VERSION ""

NS_ :

BS_:

BU_: AMP BCM DCSD DIAG_TEST DTV ECC EMCM ETM HCPM IPC LSMD LSMP LTM RRM TBM
BO_ 1283 RADIO_B3: 8 ETM
 SG_ ManDispCtrl : 56|1@0+ (1,0) [0|1] "" DCSD
 SG_ RQ_DISP_INTS : 55|8@0+ (0.5,0) [0|100] "%" DCSD

BO_ 1284 RADIO_B4: 8 ETM
 SG_ Radio_Theme : 7|8@0+ (1,0) [0|254] "-" Vector__XXX

BO_ 1289 RADIO_B9: 8 ETM
 SG_ ChargeNow : 39|1@0+ (1,0) [0|1] "" BCM

BO_ 1452 SAT_POS: 8 TBM
 SG_ Lat_Pos : 7|32@0+ (0.3017485143,-324000000) [-324000000|972000000.23334] "Milliarcseconds" ETM,LTM
 SG_ Long_Pos : 39|32@0+ (0.3017485143,-324000000) [-324000000|972000000.23334] "Milliarcseconds" ETM,LTM

BO_ 948 SDW_INFO: 6 BCM
 SG_ SDW_ChimeActivation_LHF : 36|1@0+ (1,0) [0|1] "-" AMP,ETM,IPC,LTM,TBM
 SG_ SDW_ChimeActivation_LHR : 38|1@0+ (1,0) [0|1] "-" AMP,ETM,IPC,LTM,TBM
 SG_ SDW_ChimeActivation_RHF : 37|1@0+ (1,0) [0|1] "-" AMP,ETM,IPC,LTM,TBM
 SG_ SDW_ChimeActivation_RHR : 39|1@0+ (1,0) [0|1] "-" AMP,ETM,IPC,LTM,TBM
 SG_ SDW_ChimeRepetitionRate_Left : 47|4@0+ (1,0) [0|15] "Hz" AMP,ETM,IPC,LTM,TBM
 SG_ SDW_ChimeRepetitionRate_Right : 43|4@0+ (1,0) [0|15] "Hz" AMP,ETM,IPC,LTM,TBM
 SG_ SDW_ChimeType_Left : 33|2@0+ (1,0) [0|3] "-" AMP,ETM,LTM,TBM
 SG_ SDW_ChimeType_Right : 35|2@0+ (1,0) [0|3] "-" AMP,ETM,LTM,TBM
 SG_ SDW_DisplayActivation : 6|1@0+ (1,0) [0|1] "-" IPC
 SG_ SDW_ObstacleInTrajectory_LLF : 5|1@0+ (1,0) [0|1] "-" IPC
 SG_ SDW_ObstacleInTrajectory_LLR : 4|1@0+ (1,0) [0|1] "-" IPC
 SG_ SDW_ObstacleInTrajectory_LRF : 3|1@0+ (1,0) [0|1] "-" IPC
 SG_ SDW_ObstacleInTrajectory_LRR : 2|1@0+ (1,0) [0|1] "-" IPC
 SG_ SDW_Warning_Left_1 : 27|2@0+ (1,0) [0|2] "-" IPC
 SG_ SDW_Warning_Left_2 : 25|2@0+ (1,0) [0|2] "-" IPC
 SG_ SDW_Warning_Right_1 : 31|2@0+ (1,0) [0|2] "-" IPC
 SG_ SDW_Warning_Right_2 : 29|2@0+ (1,0) [0|2] "-" IPC

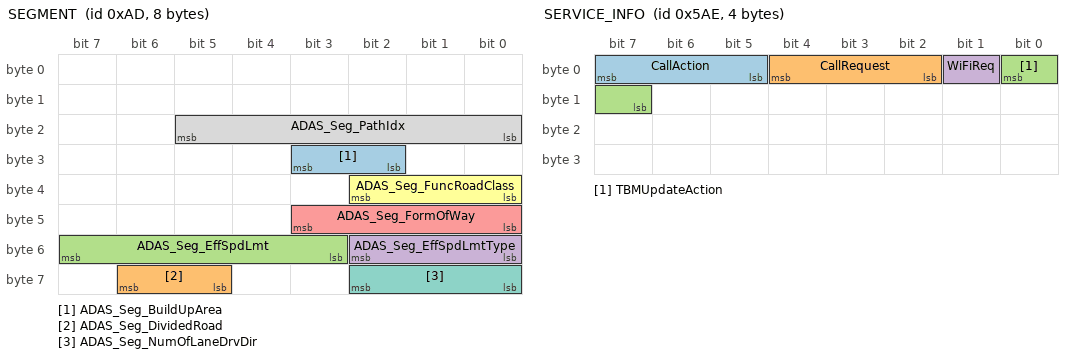
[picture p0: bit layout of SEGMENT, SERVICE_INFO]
BO_ 173 SEGMENT: 8 ETM
 SG_ ADAS_Seg_BuildUpArea : 27|2@0+ (1,0) [0|3] "-" BCM,IPC
 SG_ ADAS_Seg_DividedRoad : 62|2@0+ (1,0) [0|3] "-" BCM,IPC
 SG_ ADAS_Seg_EffSpdLmt : 55|5@0+ (1,0) [0|31] "-" BCM,IPC
 SG_ ADAS_Seg_EffSpdLmtType : 50|3@0+ (1,0) [0|7] "-" BCM,IPC
 SG_ ADAS_Seg_FormOfWay : 43|4@0+ (1,0) [0|15] "-" BCM,IPC
 SG_ ADAS_Seg_FuncRoadClass : 34|3@0+ (1,0) [0|7] "-" BCM,IPC
 SG_ ADAS_Seg_NumOfLaneDrvDir : 58|3@0+ (1,0) [0|7] "" BCM,IPC
 SG_ ADAS_Seg_PathIdx : 21|6@0+ (1,0) [0|63] "-" BCM,IPC

BO_ 1454 SERVICE_INFO: 4 ETM
 SG_ CallAction : 7|3@0+ (1,0) [0|7] "" TBM
 SG_ CallRequest : 4|3@0+ (1,0) [0|7] "" TBM
 SG_ TBMUpdateAction : 0|2@0+ (1,0) [0|3] "" TBM
 SG_ WiFiReq : 1|1@0+ (1,0) [0|1] "" TBM

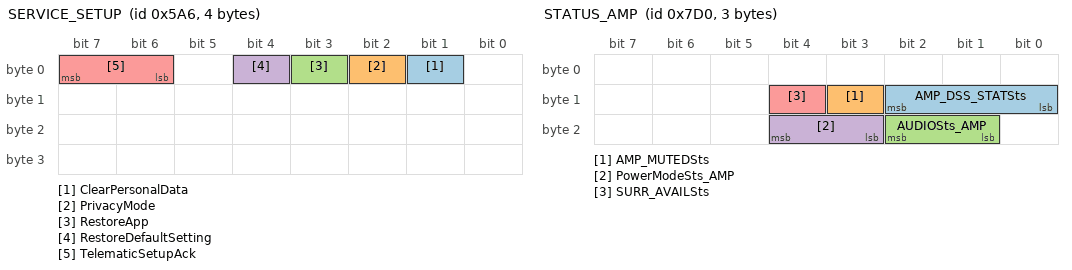
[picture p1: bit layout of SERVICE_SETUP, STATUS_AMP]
BO_ 1446 SERVICE_SETUP: 4 TBM
 SG_ ClearPersonalData : 1|1@0+ (1,0) [0|1] "-" ETM,LTM
 SG_ PrivacyMode : 2|1@0+ (1,0) [0|1] "-" ETM,LTM
 SG_ RestoreApp : 3|1@0+ (1,0) [0|1] "-" ETM,LTM
 SG_ RestoreDefaultSetting : 4|1@0+ (1,0) [0|1] "-" ETM,LTM
 SG_ TelematicSetupAck : 7|2@0+ (1,0) [0|3] "-" ETM

BO_ 1890 SERVICEINFO2: 6 IPC
 SG_ DaysToService : 22|9@0+ (1,0) [0|366] "day" LTM,TBM
 SG_ DistanceToService : 7|17@0+ (1,0) [0|131071] "km_or_mi" ETM,LTM,TBM

BO_ 2000 STATUS_AMP: 3 AMP
 SG_ AMP_DSS_STATSts : 10|3@0+ (1,0) [0|7] "" ETM,LTM
 SG_ AMP_MUTEDSts : 11|1@0+ (1,0) [0|1] "" ETM,LTM
 SG_ AUDIOSts_AMP : 18|2@0+ (1,0) [0|3] "" ETM,LTM
 SG_ PowerModeSts_AMP : 20|2@0+ (1,0) [0|3] "" BCM
 SG_ SURR_AVAILSts : 12|1@0+ (1,0) [0|1] "" ETM,LTM

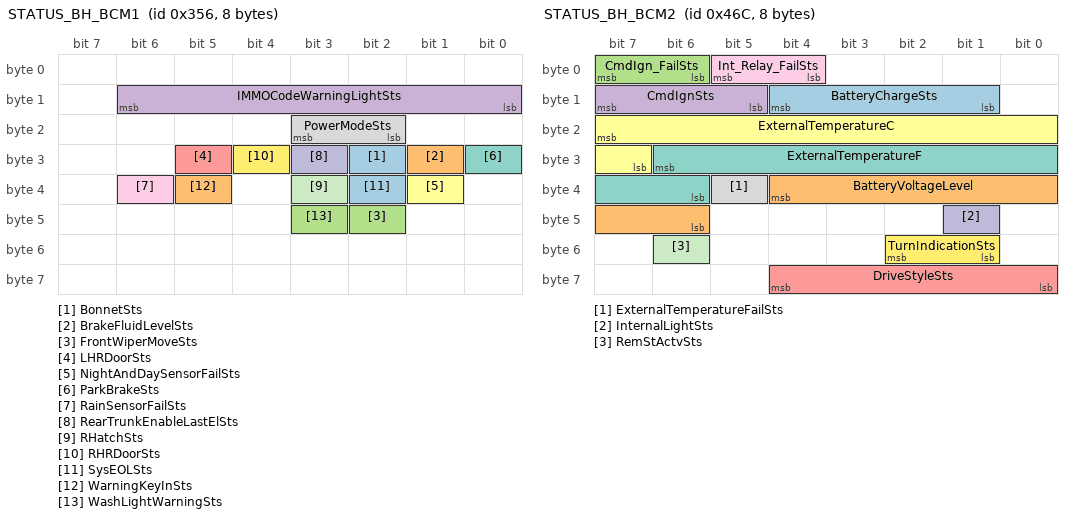
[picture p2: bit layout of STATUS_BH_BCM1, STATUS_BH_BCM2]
BO_ 854 STATUS_BH_BCM1: 8 BCM
 SG_ BonnetSts : 26|1@0+ (1,0) [0|1] "-" ETM,IPC,LTM,TBM
 SG_ BrakeFluidLevelSts : 25|1@0+ (1,0) [0|1] "-" ETM,LTM,RRM,TBM
 SG_ FrontWiperMoveSts : 42|1@0+ (1,0) [0|1] "" ECC,TBM
 SG_ IMMOCodeWarningLightSts : 14|7@0+ (1,0) [0|18] "-" IPC
 SG_ LHRDoorSts : 29|1@0+ (1,0) [0|1] "-" ECC,ETM,IPC,LTM,TBM
 SG_ NightAndDaySensorFailSts : 33|1@0+ (1,0) [0|1] "" IPC
 SG_ ParkBrakeSts : 24|1@0+ (1,0) [0|1] "-" ETM,LTM
 SG_ PowerModeSts : 19|2@0+ (1,0) [0|3] "" AMP,ECC,ETM,HCPM,LSMD,LSMP,LTM,RRM,TBM
 SG_ RainSensorFailSts : 38|1@0+ (1,0) [0|1] "-" IPC
 SG_ RearTrunkEnableLastElSts : 27|1@0+ (1,0) [0|1] "-" TBM
 SG_ RHatchSts : 35|1@0+ (1,0) [0|1] "-" ECC,ETM,IPC,LTM,TBM
 SG_ RHRDoorSts : 28|1@0+ (1,0) [0|1] "-" ECC,ETM,IPC,LTM,TBM
 SG_ SysEOLSts : 34|1@0+ (1,0) [0|1] "-" IPC
 SG_ WarningKeyInSts : 37|1@0+ (1,0) [0|1] "" IPC
 SG_ WashLightWarningSts : 43|1@0+ (1,0) [0|1] "" IPC,TBM

BO_ 1132 STATUS_BH_BCM2: 8 BCM
 SG_ BatteryChargeSts : 12|4@0+ (5,40) [40|110] "%" Vector__XXX
 SG_ BatteryVoltageLevel : 36|7@0+ (0.16,0) [0|18] "Volt" ECC,ETM,LTM,TBM
 SG_ CmdIgn_FailSts : 7|2@0+ (1,0) [0|3] "" AMP,DCSD,ECC,EMCM,ETM,HCPM,LSMD,LSMP,LTM,RRM,TBM
 SG_ CmdIgnSts : 15|3@0+ (1,0) [0|7] "" AMP,DCSD,ECC,EMCM,ETM,HCPM,LSMD,LSMP,LTM,RRM,TBM
 SG_ DriveStyleSts : 60|5@0+ (1,0) [0|31] "-" ECC,ETM,IPC,LTM,TBM
 SG_ ExternalTemperatureC : 23|9@0+ (0.5,-85) [-85|170] "°C" ECC,ETM,IPC,LTM,RRM,TBM
 SG_ ExternalTemperatureF : 30|9@0+ (1,-121) [-121|389] "°F" ETM,IPC,LTM,RRM,TBM
 SG_ ExternalTemperatureFailSts : 37|1@0+ (1,0) [0|1] "-" ECC,ETM,IPC,LTM,RRM,TBM
 SG_ Int_Relay_FailSts : 5|2@0+ (1,0) [0|3] "" Vector__XXX
 SG_ InternalLightSts : 41|1@0+ (1,0) [0|1] "" DCSD,EMCM,ETM,HCPM,LSMD,LSMP,LTM,TBM
 SG_ RemStActvSts : 54|1@0+ (1,0) [0|1] "" ECC,EMCM,ETM,LTM,RRM,TBM
 SG_ TurnIndicationSts : 50|2@0+ (1,0) [0|3] "" ETM,LTM

BO_ 1450 STATUS_BH_BCM3: 4 BCM
 SG_ PreCondActvSts : 28|1@0+ (1,0) [0|1] "" ECC
 SG_ RecoveryIgnOffInd : 15|2@0+ (1,0) [0|3] "" IPC

BO_ 1128 STATUS_BH_IPC: 2 IPC
 SG_ InternalLightLevel2 : 2|4@0+ (1,0) [0|15] "" BCM,DCSD,EMCM,HCPM,TBM

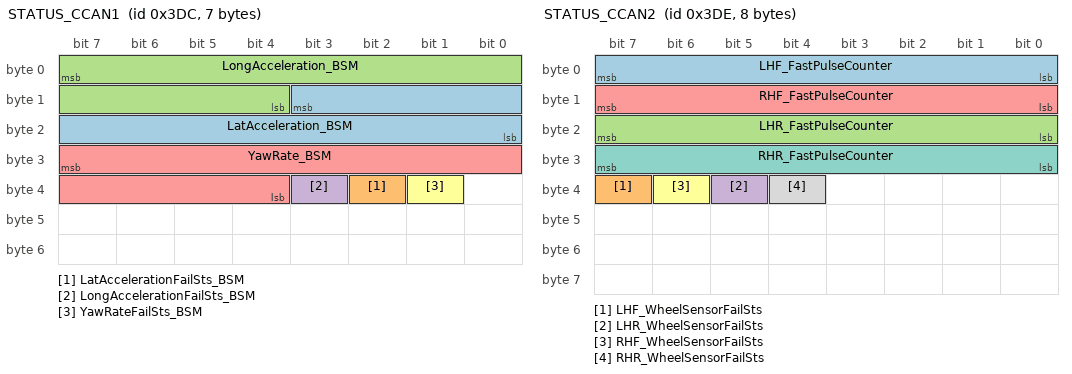
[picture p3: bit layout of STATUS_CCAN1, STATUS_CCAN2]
BO_ 988 STATUS_CCAN1: 7 BCM
 SG_ LatAcceleration_BSM : 11|12@0+ (0.02,-40.96) [-40.96|40.92] "m/s^2" ETM,LTM
 SG_ LatAccelerationFailSts_BSM : 34|1@0+ (1,0) [0|1] "-" ETM,LTM
 SG_ LongAcceleration_BSM : 7|12@0+ (0.02,-40.96) [-40.96|40.92] "m/s^2" ETM,LTM
 SG_ LongAccelerationFailSts_BSM : 35|1@0+ (1,0) [0|1] "-" ETM,LTM
 SG_ YawRate_BSM : 31|12@0+ (0.08,-163.84) [-163.84|163.68] "deg/s" ETM,LTM
 SG_ YawRateFailSts_BSM : 33|1@0+ (1,0) [0|1] "-" ETM,LTM

BO_ 990 STATUS_CCAN2: 8 BCM
 SG_ LHF_FastPulseCounter : 7|8@0+ (1,0) [0|255] "pulse" ETM,LTM,RRM
 SG_ LHF_WheelSensorFailSts : 39|1@0+ (1,0) [0|1] "-" ETM,LTM,RRM
 SG_ LHR_FastPulseCounter : 23|8@0+ (1,0) [0|255] "pulse" ETM,LTM,RRM
 SG_ LHR_WheelSensorFailSts : 37|1@0+ (1,0) [0|1] "-" ETM,LTM,RRM
 SG_ RHF_FastPulseCounter : 15|8@0+ (1,0) [0|255] "pulse" ETM,LTM,RRM
 SG_ RHF_WheelSensorFailSts : 38|1@0+ (1,0) [0|1] "-" ETM,LTM,RRM
 SG_ RHR_FastPulseCounter : 31|8@0+ (1,0) [0|255] "pulse" ETM,LTM,RRM
 SG_ RHR_WheelSensorFailSts : 36|1@0+ (1,0) [0|1] "-" ETM,LTM,RRM

BO_ 994 STATUS_CCAN3: 8 BCM
 SG_ PowertrainPrplsnActv : 33|1@0+ (1,0) [0|1] "" AMP,DCSD,ECC,EMCM,ETM,HCPM,LSMD,LSMP,LTM,RRM,TBM
 SG_ VehicleSpeedVSOSig : 47|13@0+ (0.0625,0) [0|511.9375] "Km/h" AMP,ECC,ETM,LSMD,LSMP,LTM,RRM
 SG_ VehicleSpeedVSOSigFailSts : 32|1@0+ (1,0) [0|1] "" AMP,ECC,ETM,LSMD,LSMP,LTM,RRM

BO_ 996 STATUS_CCAN4: 8 BCM
 SG_ ReverseGearSts : 62|2@0+ (1,0) [0|3] "-" ETM,LTM,RRM

BO_ 998 STATUS_CCAN5: 8 BCM
 SG_ AirTemp_Outsd : 55|8@0+ (0.5,-40) [-40|85] "°C" ECC
 SG_ ShiftLeverPosition : 7|4@0+ (1,0) [0|15] "-" ETM,LTM

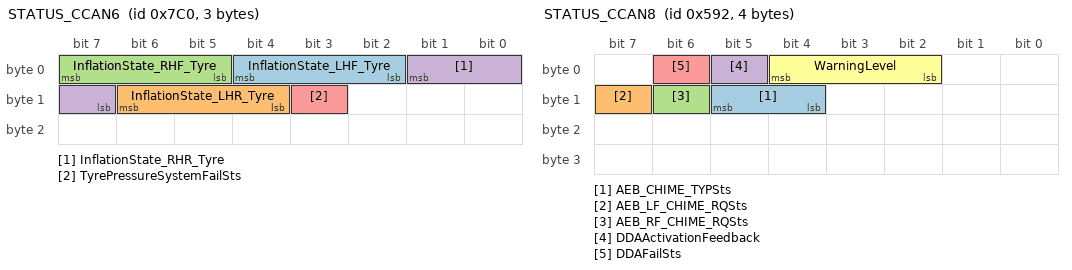
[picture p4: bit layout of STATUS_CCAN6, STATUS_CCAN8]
BO_ 1984 STATUS_CCAN6: 3 BCM
 SG_ InflationState_LHF_Tyre : 4|3@0+ (1,0) [0|4] "-" ETM,LTM
 SG_ InflationState_LHR_Tyre : 14|3@0+ (1,0) [0|4] "-" ETM,LTM
 SG_ InflationState_RHF_Tyre : 7|3@0+ (1,0) [0|4] "-" ETM,LTM
 SG_ InflationState_RHR_Tyre : 1|3@0+ (1,0) [0|4] "-" ETM,LTM
 SG_ TyrePressureSystemFailSts : 11|1@0+ (1,0) [0|1] "" ETM,LTM

BO_ 1426 STATUS_CCAN8: 4 BCM
 SG_ AEB_CHIME_TYPSts : 13|2@0+ (1,0) [0|3] "" AMP,ETM,LTM,TBM
 SG_ AEB_LF_CHIME_RQSts : 15|1@0+ (1,0) [0|1] "" AMP,ETM,LTM,TBM
 SG_ AEB_RF_CHIME_RQSts : 14|1@0+ (1,0) [0|1] "" AMP,ETM,LTM,TBM
 SG_ DDAActivationFeedback : 5|1@0+ (1,0) [0|1] "Nm" IPC
 SG_ DDAFailSts : 6|1@0+ (1,0) [0|1] "-" IPC
 SG_ WarningLevel : 4|3@0+ (1,0) [0|7] "-" IPC

BO_ 1460 STATUS_CENTERSTACK: 2 HCPM
 SG_ PowerModeSts_CStack : 7|2@0+ (1,0) [0|3] "" BCM

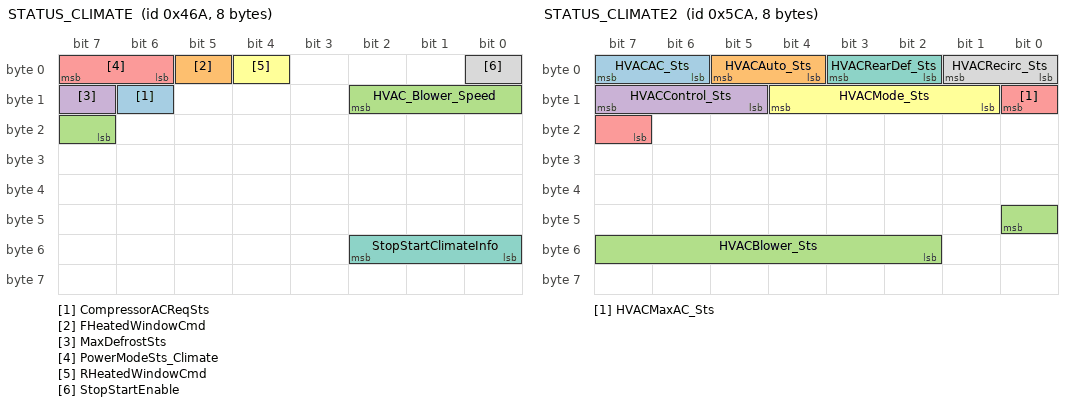
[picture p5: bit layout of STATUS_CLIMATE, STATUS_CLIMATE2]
BO_ 1130 STATUS_CLIMATE: 8 ECC
 SG_ CompressorACReqSts : 14|1@0+ (1,0) [0|1] "-" BCM
 SG_ FHeatedWindowCmd : 5|1@0+ (1,0) [0|1] "-" BCM
 SG_ HVAC_Blower_Speed : 10|4@0+ (1,0) [0|14] "" Vector__XXX
 SG_ MaxDefrostSts : 15|1@0+ (1,0) [0|1] "-" BCM,ETM,HCPM,LTM
 SG_ PowerModeSts_Climate : 7|2@0+ (1,0) [0|3] "-" BCM
 SG_ RHeatedWindowCmd : 4|1@0+ (1,0) [0|1] "-" BCM
 SG_ StopStartClimateInfo : 50|3@0+ (1,0) [0|5] "-" Vector__XXX
 SG_ StopStartEnable : 0|1@0+ (1,0) [0|1] "-" Vector__XXX

BO_ 1482 STATUS_CLIMATE2: 8 ECC
 SG_ HVACAC_Sts : 7|2@0+ (1,0) [0|3] "" ETM,HCPM,LTM,TBM
 SG_ HVACAuto_Sts : 5|2@0+ (1,0) [0|3] "" ETM,HCPM,LTM,TBM
 SG_ HVACBlower_Sts : 40|7@0+ (1,0) [0|127] "" ETM,HCPM,LTM,TBM
 SG_ HVACControl_Sts : 15|3@0+ (1,0) [0|7] "" ETM,HCPM,IPC,LTM
 SG_ HVACMaxAC_Sts : 8|2@0+ (1,0) [0|3] "" ETM,HCPM,LTM,TBM
 SG_ HVACMode_Sts : 12|4@0+ (1,0) [0|15] "" ETM,HCPM,LTM,TBM
 SG_ HVACRearDef_Sts : 3|2@0+ (1,0) [0|3] "" ETM,HCPM,LTM
 SG_ HVACRecirc_Sts : 1|2@0+ (1,0) [0|3] "" ETM,HCPM,LTM,TBM

BO_ 1483 STATUS_CLIMATE3: 8 ECC
 SG_ HVACDRVTemp : 7|6@0+ (1,0) [0|63] "°" ETM,HCPM,LTM,TBM

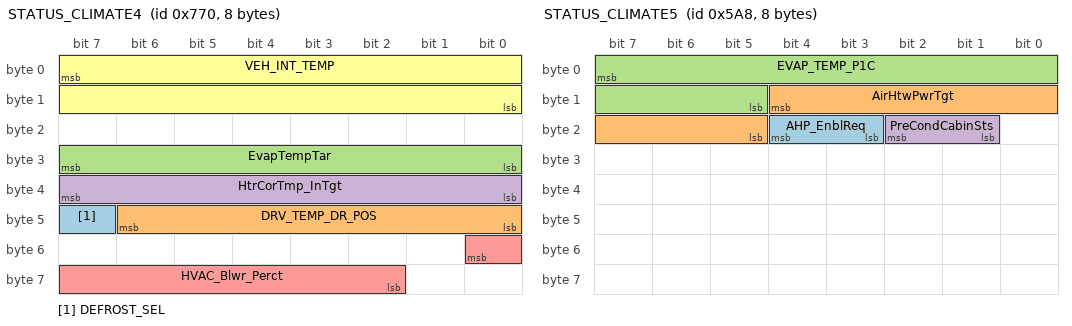
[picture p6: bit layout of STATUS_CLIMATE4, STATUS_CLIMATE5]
BO_ 1904 STATUS_CLIMATE4: 8 ECC
 SG_ DEFROST_SEL : 47|1@0+ (1,0) [0|1] "" BCM
 SG_ DRV_TEMP_DR_POS : 46|7@0+ (1,0) [0|100] "%" BCM
 SG_ EvapTempTar : 31|8@0+ (0.5,-20) [-20|107] "°C" BCM
 SG_ HtrCorTmp_InTgt : 39|8@0+ (1,-40) [-40|214] "°C" BCM
 SG_ HVAC_Blwr_Perct : 48|7@0+ (1,0) [0|100] "%" BCM
 SG_ VEH_INT_TEMP : 7|16@0+ (0.01,-40) [-40|85] "°C" BCM,ETM,LTM

BO_ 1448 STATUS_CLIMATE5: 8 ECC
 SG_ AHP_EnblReq : 20|2@0+ (1,0) [0|3] "" Vector__XXX
 SG_ AirHtwPwrTgt : 12|8@0+ (1,0) [0|254] "%" BCM
 SG_ EVAP_TEMP_P1C : 7|11@0+ (0.1,-40) [-40|85] "°C" BCM
 SG_ PreCondCabinSts : 18|2@0+ (1,0) [0|3] "" BCM,IPC

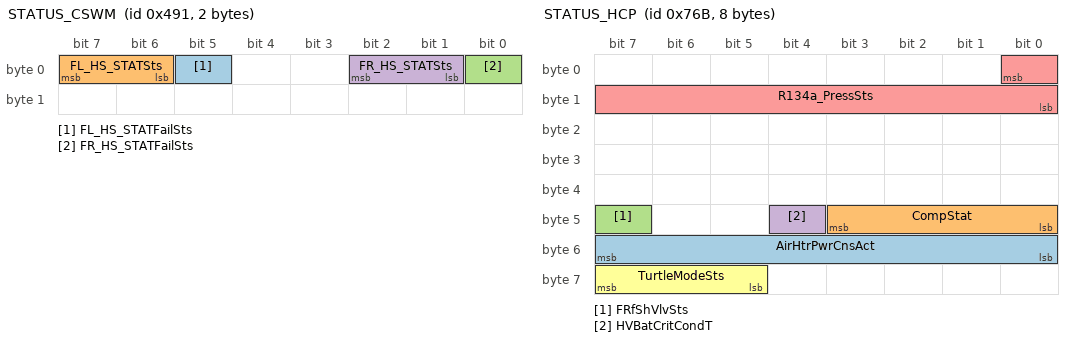
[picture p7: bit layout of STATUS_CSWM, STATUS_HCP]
BO_ 1169 STATUS_CSWM: 2 ECC
 SG_ FL_HS_STATFailSts : 5|1@0+ (1,0) [0|1] "" ETM,LTM
 SG_ FL_HS_STATSts : 7|2@0+ (1,0) [0|3] "" ETM,IPC,LTM,TBM
 SG_ FR_HS_STATFailSts : 0|1@0+ (1,0) [0|1] "" ETM,LTM
 SG_ FR_HS_STATSts : 2|2@0+ (1,0) [0|3] "" ETM,IPC,LTM,TBM

BO_ 1899 STATUS_HCP: 8 BCM
 SG_ AirHtrPwrCnsAct : 55|8@0+ (1,0) [0|254] "%" ECC
 SG_ CompStat : 43|4@0+ (1,0) [0|15] "-" ECC
 SG_ FRfShVlvSts : 47|1@0+ (1,0) [0|1] "-" ECC
 SG_ HVBatCritCondT : 44|1@0+ (1,0) [0|1] "-" ECC
 SG_ R134a_PressSts : 0|9@0+ (0.1,0) [0|40] "bar" ECC
 SG_ TurtleModeSts : 63|3@0+ (1,0) [0|6] "" ECC,ETM,HCPM,IPC

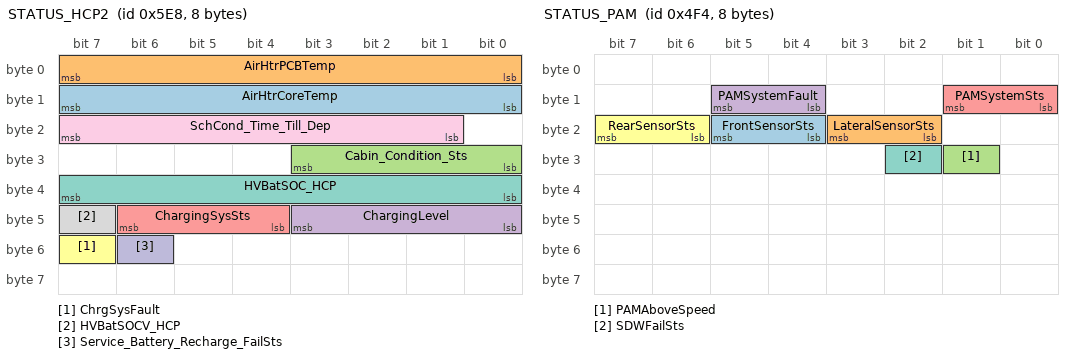
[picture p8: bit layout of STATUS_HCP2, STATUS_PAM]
BO_ 1512 STATUS_HCP2: 8 BCM
 SG_ AirHtrCoreTemp : 15|8@0+ (1,-40) [-40|214] "°C" ECC
 SG_ AirHtrPCBTemp : 7|8@0+ (1,-40) [-40|214] "°C" ECC
 SG_ Cabin_Condition_Sts : 27|4@0+ (1,0) [0|14] "" ECC
 SG_ ChargingLevel : 43|4@0+ (1,0) [0|14] "" ECC
 SG_ ChargingSysSts : 46|3@0+ (1,0) [0|6] "" ECC
 SG_ ChrgSysFault : 55|1@0+ (1,0) [0|1] "" ECC
 SG_ HVBatSOC_HCP : 39|8@0+ (0.3922,0) [0|100] "%" ECC,ETM,LTM,RRM
 SG_ HVBatSOCV_HCP : 47|1@0+ (1,0) [0|1] "" ECC,ETM,LTM
 SG_ SchCond_Time_Till_Dep : 23|7@0+ (1,0) [0|126] "min" ECC
 SG_ Service_Battery_Recharge_FailSts : 54|1@0+ (1,0) [0|1] "" ECC

BO_ 1462 STATUS_LIN: 8 BCM
 SG_ SWSError : 17|1@0+ (1,0) [0|1] "" ETM,IPC,LTM,RRM

BO_ 1268 STATUS_PAM: 8 BCM
 SG_ FrontSensorSts : 21|2@0+ (1,0) [0|3] "" IPC,TBM
 SG_ LateralSensorSts : 19|2@0+ (1,0) [0|3] "" IPC
 SG_ PAMAboveSpeed : 25|1@0+ (1,0) [0|1] "" IPC
 SG_ PAMSystemFault : 13|2@0+ (1,0) [0|3] "-" IPC
 SG_ PAMSystemSts : 9|2@0+ (1,0) [0|3] "" IPC
 SG_ RearSensorSts : 23|2@0+ (1,0) [0|3] "" IPC,TBM
 SG_ SDWFailSts : 26|1@0+ (1,0) [0|1] "" IPC

BO_ 1458 STATUS_TBM: 8 TBM
 SG_ AudioRequest : 19|1@0+ (1,0) [0|1] "" ETM,LTM
 SG_ BUBFailSts : 25|2@0+ (1,0) [0|3] "" ETM,LTM
 SG_ CallSts : 23|4@0+ (1,0) [0|15] "" ETM,LTM
 SG_ CallType : 10|3@0+ (1,0) [0|7] "" ETM,LTM
 SG_ GPSFailSts : 36|1@0+ (1,0) [0|1] "" ETM,LTM
 SG_ IVA : 47|2@0+ (1,0) [0|3] "-" ETM,LTM
 SG_ LTESts : 18|3@0+ (1,0) [0|7] "" ETM,LTM
 SG_ MuteRequest : 45|1@0+ (1,0) [0|1] "-" ETM,LTM,RRM
 SG_ NetConnection : 33|2@0+ (1,0) [0|3] "" ETM,LTM
 SG_ PowerModeSts_TBM : 12|2@0+ (1,0) [0|3] "-" BCM
 SG_ Provisioning : 31|3@0+ (1,0) [0|7] "" ETM,LTM
 SG_ SignalStrength : 28|3@0+ (1,0) [0|7] "" ETM,LTM
 SG_ SOSCallStatus : 3|4@0+ (1,0) [0|15] "-" ETM,IPC,LTM,RRM
 SG_ SOSCallType : 15|3@0+ (1,0) [0|7] "-" ETM,LTM,RRM
 SG_ SOSFailSts : 35|1@0+ (1,0) [0|1] "" ETM,LTM
 SG_ SystemFailSts : 34|1@0+ (1,0) [0|1] "" ETM,LTM
 SG_ WiFiFailSts : 37|1@0+ (1,0) [0|1] "" ETM,LTM
 SG_ WiFiSts : 39|2@0+ (1,0) [0|3] "" ETM,LTM

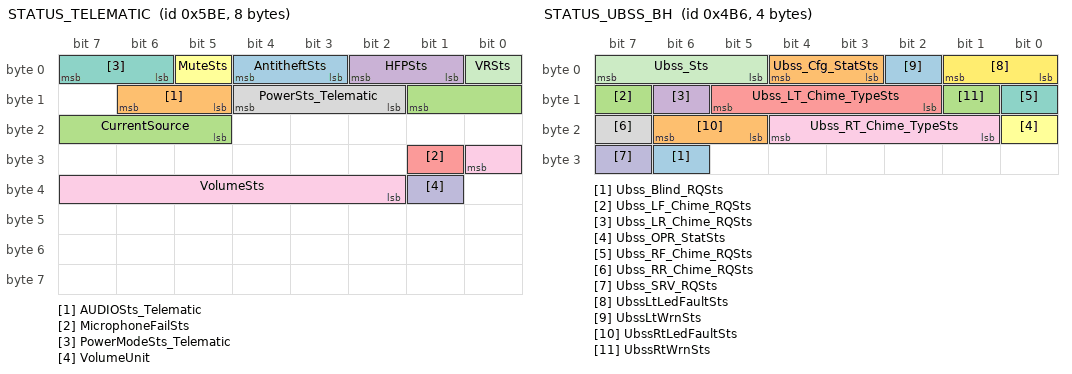
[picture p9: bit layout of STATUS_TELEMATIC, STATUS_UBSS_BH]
BO_ 1470 STATUS_TELEMATIC: 8 ETM
 SG_ AntitheftSts : 4|2@0+ (1,0) [0|3] "-" Vector__XXX
 SG_ AUDIOSts_Telematic : 14|2@0+ (1,0) [0|3] "-" AMP,IPC,TBM
 SG_ CurrentSource : 9|5@0+ (1,0) [0|31] "-" AMP,DTV,TBM
 SG_ HFPSts : 2|2@0+ (1,0) [0|3] "-" Vector__XXX
 SG_ MicrophoneFailSts : 25|1@0+ (1,0) [0|1] "-" TBM
 SG_ MuteSts : 5|1@0+ (1,0) [0|1] "-" AMP,TBM
 SG_ PowerModeSts_Telematic : 7|2@0+ (1,0) [0|3] "-" BCM
 SG_ PowerSts_Telematic : 12|3@0+ (1,0) [0|7] "-" DCSD,EMCM,IPC,TBM
 SG_ VolumeSts : 24|7@0+ (1,0) [0|126] "-" IPC
 SG_ VolumeUnit : 33|1@0+ (1,0) [0|1] "-" IPC
 SG_ VRSts : 0|1@0+ (1,0) [0|1] "-" Vector__XXX

BO_ 1206 STATUS_UBSS_BH: 4 BCM
 SG_ Ubss_Blind_RQSts : 30|1@0+ (1,0) [0|1] "" IPC,TBM
 SG_ Ubss_Cfg_StatSts : 4|2@0+ (1,0) [0|2] "" AMP,ETM,IPC,LTM,TBM
 SG_ Ubss_LF_Chime_RQSts : 15|1@0+ (1,0) [0|1] "" AMP,ETM,IPC,LTM,TBM
 SG_ Ubss_LR_Chime_RQSts : 14|1@0+ (1,0) [0|1] "" AMP,ETM,IPC,LTM,TBM
 SG_ Ubss_LT_Chime_TypeSts : 13|4@0+ (1,0) [0|14] "" AMP,ETM,IPC,LTM,TBM
 SG_ Ubss_OPR_StatSts : 16|1@0+ (1,0) [0|1] "" IPC,TBM
 SG_ Ubss_RF_Chime_RQSts : 8|1@0+ (1,0) [0|1] "" AMP,ETM,IPC,LTM,TBM
 SG_ Ubss_RR_Chime_RQSts : 23|1@0+ (1,0) [0|1] "" AMP,ETM,IPC,LTM,TBM
 SG_ Ubss_RT_Chime_TypeSts : 20|4@0+ (1,0) [0|14] "" AMP,ETM,IPC,LTM,TBM
 SG_ Ubss_SRV_RQSts : 31|1@0+ (1,0) [0|1] "" IPC,TBM
 SG_ Ubss_Sts : 7|3@0+ (1,0) [0|6] "" IPC
 SG_ UbssLtLedFaultSts : 1|2@0+ (1,0) [0|3] "" Vector__XXX
 SG_ UbssLtWrnSts : 2|1@0+ (1,0) [0|1] "" Vector__XXX
 SG_ UbssRtLedFaultSts : 22|2@0+ (1,0) [0|3] "" Vector__XXX
 SG_ UbssRtWrnSts : 9|1@0+ (1,0) [0|1] "" Vector__XXX

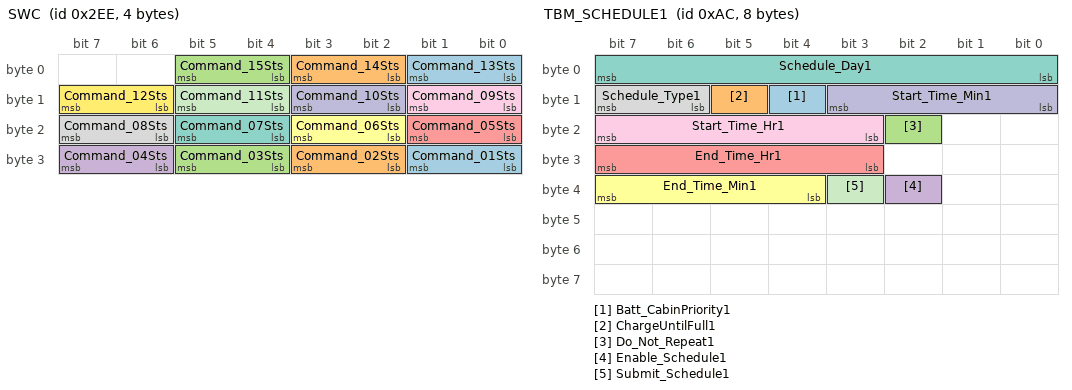
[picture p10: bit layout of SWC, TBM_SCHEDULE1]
BO_ 750 SWC: 4 BCM
 SG_ Command_01Sts : 25|2@0+ (1,0) [0|2] "" ETM,LTM,RRM,TBM
 SG_ Command_02Sts : 27|2@0+ (1,0) [0|2] "" ETM,LTM,RRM,TBM
 SG_ Command_03Sts : 29|2@0+ (1,0) [0|2] "" ETM,LTM,RRM,TBM
 SG_ Command_04Sts : 31|2@0+ (1,0) [0|2] "" ETM,LTM,RRM,TBM
 SG_ Command_05Sts : 17|2@0+ (1,0) [0|2] "" ETM,LTM,RRM,TBM
 SG_ Command_06Sts : 19|2@0+ (1,0) [0|2] "" ETM,LTM,RRM,TBM
 SG_ Command_07Sts : 21|2@0+ (1,0) [0|2] "" ETM,LTM,RRM,TBM
 SG_ Command_08Sts : 23|2@0+ (1,0) [0|2] "" ETM,LTM,RRM,TBM
 SG_ Command_09Sts : 9|2@0+ (1,0) [0|2] "" ETM,LTM,RRM,TBM
 SG_ Command_10Sts : 11|2@0+ (1,0) [0|2] "" ETM,LTM,RRM,TBM
 SG_ Command_11Sts : 13|2@0+ (1,0) [0|2] "" ETM,IPC,TBM
 SG_ Command_12Sts : 15|2@0+ (1,0) [0|2] "" ETM,IPC,TBM
 SG_ Command_13Sts : 1|2@0+ (1,0) [0|2] "" ETM,IPC,TBM
 SG_ Command_14Sts : 3|2@0+ (1,0) [0|2] "" IPC,TBM
 SG_ Command_15Sts : 5|2@0+ (1,0) [0|2] "" IPC,TBM

BO_ 178 TBM_REQUEST: 4 TBM
 SG_ ChargeNow : 7|1@0+ (1,0) [0|0] "" BCM

BO_ 172 TBM_SCHEDULE1: 8 TBM
 SG_ Batt_CabinPriority1 : 12|1@0+ (1,0) [0|1] "-" BCM
 SG_ ChargeUntilFull1 : 13|1@0+ (1,0) [0|1] "-" BCM
 SG_ Do_Not_Repeat1 : 18|1@0+ (1,0) [0|1] "-" BCM
 SG_ Enable_Schedule1 : 34|1@0+ (1,0) [0|1] "-" BCM
 SG_ End_Time_Hr1 : 31|5@0+ (1,0) [0|23] "Hours" BCM
 SG_ End_Time_Min1 : 39|4@0+ (5,0) [0|55] "min" BCM
 SG_ Schedule_Day1 : 7|8@0+ (1,0) [0|255] "-" BCM
 SG_ Schedule_Type1 : 15|2@0+ (1,0) [0|3] "-" BCM
 SG_ Start_Time_Hr1 : 23|5@0+ (1,0) [0|23] "Hours" BCM
 SG_ Start_Time_Min1 : 11|4@0+ (5,0) [0|55] "min" BCM
 SG_ Submit_Schedule1 : 35|1@0+ (1,0) [0|1] "-" BCM

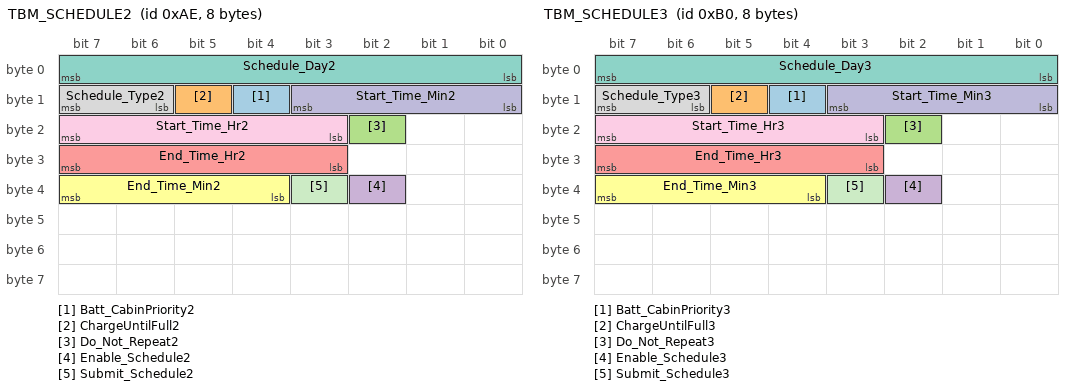
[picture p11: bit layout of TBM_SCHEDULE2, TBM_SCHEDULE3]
BO_ 174 TBM_SCHEDULE2: 8 TBM
 SG_ Batt_CabinPriority2 : 12|1@0+ (1,0) [0|1] "-" BCM
 SG_ ChargeUntilFull2 : 13|1@0+ (1,0) [0|1] "-" BCM
 SG_ Do_Not_Repeat2 : 18|1@0+ (1,0) [0|1] "-" BCM
 SG_ Enable_Schedule2 : 34|1@0+ (1,0) [0|1] "-" BCM
 SG_ End_Time_Hr2 : 31|5@0+ (1,0) [0|23] "Hours" BCM
 SG_ End_Time_Min2 : 39|4@0+ (5,0) [0|55] "min" BCM
 SG_ Schedule_Day2 : 7|8@0+ (1,0) [0|255] "-" BCM
 SG_ Schedule_Type2 : 15|2@0+ (1,0) [0|3] "-" BCM
 SG_ Start_Time_Hr2 : 23|5@0+ (1,0) [0|23] "Hours" BCM
 SG_ Start_Time_Min2 : 11|4@0+ (5,0) [0|55] "min" BCM
 SG_ Submit_Schedule2 : 35|1@0+ (1,0) [0|1] "-" BCM

BO_ 176 TBM_SCHEDULE3: 8 TBM
 SG_ Batt_CabinPriority3 : 12|1@0+ (1,0) [0|1] "-" BCM
 SG_ ChargeUntilFull3 : 13|1@0+ (1,0) [0|1] "-" BCM
 SG_ Do_Not_Repeat3 : 18|1@0+ (1,0) [0|1] "-" BCM
 SG_ Enable_Schedule3 : 34|1@0+ (1,0) [0|1] "-" BCM
 SG_ End_Time_Hr3 : 31|5@0+ (1,0) [0|23] "Hours" BCM
 SG_ End_Time_Min3 : 39|4@0+ (5,0) [0|55] "min" BCM
 SG_ Schedule_Day3 : 7|8@0+ (1,0) [0|255] "-" BCM
 SG_ Schedule_Type3 : 15|2@0+ (1,0) [0|3] "-" BCM
 SG_ Start_Time_Hr3 : 23|5@0+ (1,0) [0|23] "Hours" BCM
 SG_ Start_Time_Min3 : 11|4@0+ (5,0) [0|55] "min" BCM
 SG_ Submit_Schedule3 : 35|1@0+ (1,0) [0|1] "-" BCM

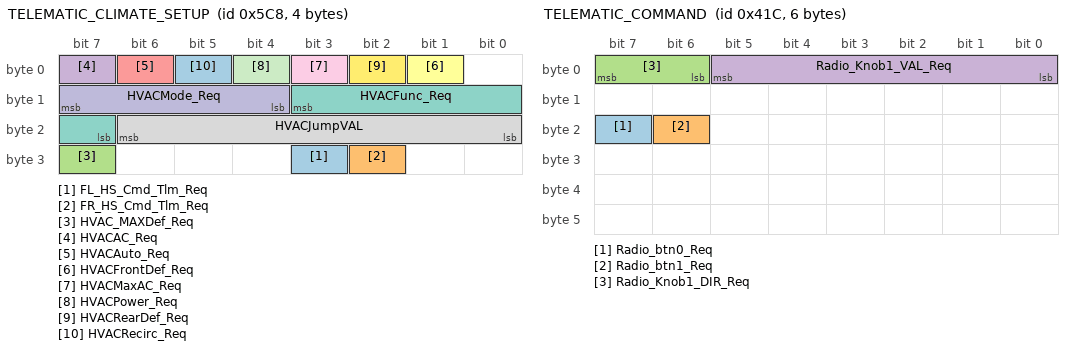
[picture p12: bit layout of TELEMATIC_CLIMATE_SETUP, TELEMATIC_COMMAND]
BO_ 1480 TELEMATIC_CLIMATE_SETUP: 4 ETM
 SG_ FL_HS_Cmd_Tlm_Req : 27|1@0+ (1,0) [0|1] "" ECC,TBM
 SG_ FR_HS_Cmd_Tlm_Req : 26|1@0+ (1,0) [0|1] "" ECC,TBM
 SG_ HVAC_MAXDef_Req : 31|1@0+ (1,0) [0|1] "" ECC
 SG_ HVACAC_Req : 7|1@0+ (1,0) [0|1] "" ECC,TBM
 SG_ HVACAuto_Req : 6|1@0+ (1,0) [0|1] "" ECC,TBM
 SG_ HVACFrontDef_Req : 1|1@0+ (1,0) [0|1] "" ECC
 SG_ HVACFunc_Req : 11|5@0+ (1,0) [0|31] "" ECC,IPC
 SG_ HVACJumpVAL : 22|7@0+ (1,0) [0|127] "" ECC
 SG_ HVACMaxAC_Req : 3|1@0+ (1,0) [0|1] "" ECC,TBM
 SG_ HVACMode_Req : 15|4@0+ (1,0) [0|15] "" ECC,TBM
 SG_ HVACPower_Req : 4|1@0+ (1,0) [0|1] "" ECC
 SG_ HVACRearDef_Req : 2|1@0+ (1,0) [0|1] "" ECC,TBM
 SG_ HVACRecirc_Req : 5|1@0+ (1,0) [0|1] "" ECC,TBM

BO_ 1052 TELEMATIC_COMMAND: 6 EMCM
 SG_ Radio_btn0_Req : 23|1@0+ (1,0) [0|1] "" ETM,LTM
 SG_ Radio_btn1_Req : 22|1@0+ (1,0) [0|1] "" ETM,LTM,RRM
 SG_ Radio_Knob1_DIR_Req : 7|2@0+ (1,0) [0|3] "" ETM,LTM,RRM,TBM
 SG_ Radio_Knob1_VAL_Req : 5|6@0+ (1,0) [0|63] "" ETM,LTM,RRM,TBM

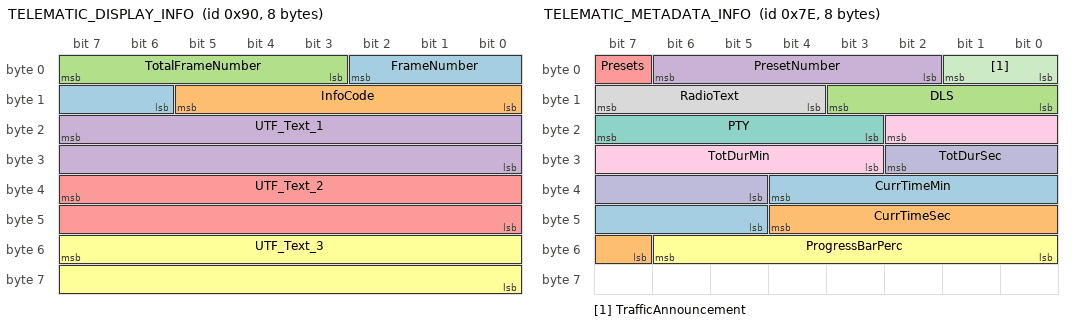
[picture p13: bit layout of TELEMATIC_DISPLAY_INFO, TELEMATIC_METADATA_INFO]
BO_ 144 TELEMATIC_DISPLAY_INFO: 8 ETM
 SG_ FrameNumber : 2|5@0+ (1,0) [0|31] "-" IPC
 SG_ InfoCode : 13|6@0+ (1,0) [0|63] "-" IPC
 SG_ TotalFrameNumber : 7|5@0+ (1,0) [0|31] "-" IPC
 SG_ UTF_Text_1 : 23|16@0+ (1,0) [0|65535] "-" IPC
 SG_ UTF_Text_2 : 39|16@0+ (1,0) [0|65535] "-" IPC
 SG_ UTF_Text_3 : 55|16@0+ (1,0) [0|65535] "-" IPC

BO_ 1502 TELEMATIC_DISPLAY1: 8 ETM
 SG_ TGW_PT_CAB_DRSts : 7|1@0+ (1,0) [0|0] "" DTV
 SG_ TGW_RQ1Sts : 15|8@0+ (1,0) [0|254] "" DTV

BO_ 1500 TELEMATIC_DISPLAY2: 8 ETM
 SG_ TGW_DISP_STATSts : 0|4@0+ (1,0) [0|14] "" DCSD,DTV

BO_ 126 TELEMATIC_METADATA_INFO: 8 ETM
 SG_ CurrTimeMin : 36|8@0+ (1,0) [0|254] "min" IPC
 SG_ CurrTimeSec : 44|6@0+ (1,0) [0|62] "sec" IPC
 SG_ DLS : 11|4@0+ (1,0) [0|14] "" IPC
 SG_ PresetNumber : 6|5@0+ (1,0) [0|30] "" IPC
 SG_ Presets : 7|1@0+ (1,0) [0|1] "" IPC
 SG_ ProgressBarPerc : 54|7@0+ (1,0) [0|126] "%" IPC
 SG_ PTY : 23|5@0+ (1,0) [0|31] "" IPC
 SG_ RadioText : 15|4@0+ (1,0) [0|14] "" IPC
 SG_ TotDurMin : 18|8@0+ (1,0) [0|254] "min" IPC
 SG_ TotDurSec : 26|6@0+ (1,0) [0|62] "sec" IPC
 SG_ TrafficAnnouncement : 1|2@0+ (1,0) [0|3] "" IPC

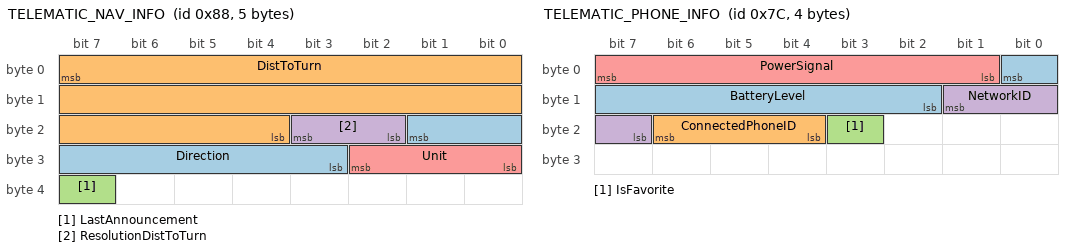
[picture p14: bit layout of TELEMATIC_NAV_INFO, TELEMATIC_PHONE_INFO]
BO_ 136 TELEMATIC_NAV_INFO: 5 ETM
 SG_ Direction : 17|7@0+ (1,0) [0|127] "-" IPC
 SG_ DistToTurn : 7|20@0+ (1,0) [0|1048575] "-" IPC
 SG_ LastAnnouncement : 39|1@0+ (1,0) [0|1] "-" IPC
 SG_ ResolutionDistToTurn : 19|2@0+ (1,0) [0|2] "-" IPC
 SG_ Unit : 26|3@0+ (1,0) [0|6] "-" IPC

BO_ 124 TELEMATIC_PHONE_INFO: 4 ETM
 SG_ BatteryLevel : 0|7@0+ (1,0) [0|126] "%" IPC
 SG_ ConnectedPhoneID : 22|3@0+ (1,0) [0|6] "" IPC
 SG_ IsFavorite : 19|1@0+ (1,0) [0|1] "" IPC
 SG_ NetworkID : 9|3@0+ (1,0) [0|6] "" IPC
 SG_ PowerSignal : 7|7@0+ (1,0) [0|126] "%" IPC

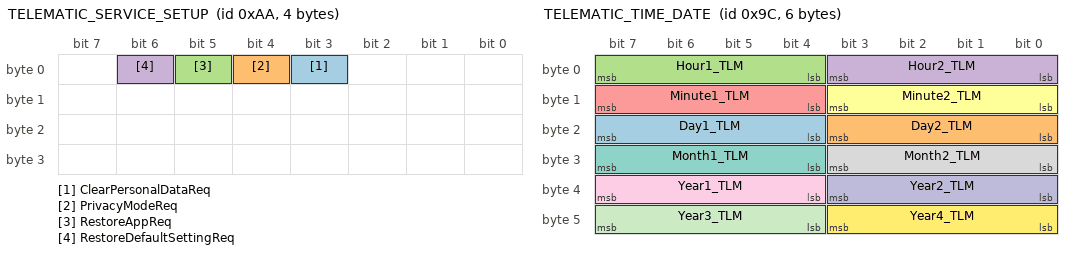
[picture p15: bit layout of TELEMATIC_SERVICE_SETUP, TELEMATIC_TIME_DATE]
BO_ 170 TELEMATIC_SERVICE_SETUP: 4 ETM
 SG_ ClearPersonalDataReq : 3|1@0+ (1,0) [0|1] "-" TBM
 SG_ PrivacyModeReq : 4|1@0+ (1,0) [0|1] "-" TBM
 SG_ RestoreAppReq : 5|1@0+ (1,0) [0|1] "-" TBM
 SG_ RestoreDefaultSettingReq : 6|1@0+ (1,0) [0|1] "-" TBM

BO_ 156 TELEMATIC_TIME_DATE: 6 ETM
 SG_ Day1_TLM : 23|4@0+ (1,0) [0|3] "-" IPC
 SG_ Day2_TLM : 19|4@0+ (1,0) [0|9] "-" IPC
 SG_ Hour1_TLM : 7|4@0+ (1,0) [0|2] "-" IPC
 SG_ Hour2_TLM : 3|4@0+ (1,0) [0|9] "-" IPC
 SG_ Minute1_TLM : 15|4@0+ (1,0) [0|5] "-" IPC
 SG_ Minute2_TLM : 11|4@0+ (1,0) [0|9] "-" IPC
 SG_ Month1_TLM : 31|4@0+ (1,0) [0|1] "-" IPC
 SG_ Month2_TLM : 27|4@0+ (1,0) [0|9] "-" IPC
 SG_ Year1_TLM : 39|4@0+ (1,0) [0|2] "-" IPC
 SG_ Year2_TLM : 35|4@0+ (1,0) [0|9] "-" IPC
 SG_ Year3_TLM : 47|4@0+ (1,0) [0|9] "-" IPC
 SG_ Year4_TLM : 43|4@0+ (1,0) [0|9] "-" IPC

BO_ 158 TELEMATIC_VEHICLE_SETUP: 8 ETM
 SG_ AutoHighBeamEnable_Req : 21|1@0+ (1,0) [0|1] "-" IPC
 SG_ AutoParkBrake_Req : 33|1@0+ (1,0) [0|1] "" IPC
 SG_ BSDEnable_Req : 30|2@0+ (1,0) [0|2] "-" IPC
 SG_ CorneringEnable_Req : 18|1@0+ (1,0) [0|1] "-" IPC
 SG_ DistanceUnit_Req : 10|1@0+ (1,0) [0|1] "-" IPC
 SG_ DRLEnable_Req : 12|1@0+ (1,0) [0|1] "-" IPC
 SG_ ExternalLightSensorLevel_Req : 9|2@0+ (1,0) [0|3] "-" IPC
 SG_ HourMode_Req : 23|1@0+ (1,0) [0|1] "-" IPC
 SG_ LanguageSelection_Req : 7|8@0+ (1,0) [0|255] "-" IPC
 SG_ PamAlertMode_Req : 43|2@0+ (1,0) [0|3] "" IPC
 SG_ PamChimeVolumeFront_Req : 45|2@0+ (1,0) [0|3] "" IPC
 SG_ PamChimeVolumeRear_Req : 41|2@0+ (1,0) [0|3] "" IPC
 SG_ PassiveEntry_Req : 28|1@0+ (1,0) [0|1] "" IPC
 SG_ RainSensorLevel_Req : 22|1@0+ (1,0) [0|1] "-" IPC
 SG_ RemoteDoorUnlock_Req : 34|1@0+ (1,0) [0|1] "" IPC
 SG_ Sdw_Req : 55|2@0+ (1,0) [0|3] "" IPC
 SG_ SoundHornLock_Req : 37|2@0+ (1,0) [0|3] "" IPC
 SG_ SoundHornRemoteStart_Req : 35|1@0+ (1,0) [0|1] "" IPC
 SG_ SpeedLockDoorEnable_Req : 20|1@0+ (1,0) [0|1] "-" IPC
 SG_ TemperatureUnit_Req : 19|1@0+ (1,0) [0|1] "-" IPC,TBM

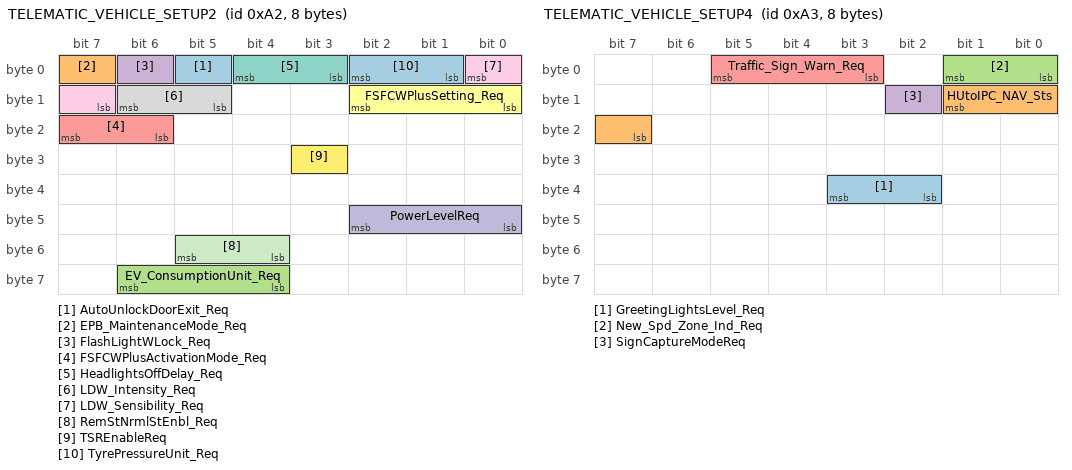
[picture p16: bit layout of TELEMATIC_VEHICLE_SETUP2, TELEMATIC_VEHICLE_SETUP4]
BO_ 162 TELEMATIC_VEHICLE_SETUP2: 8 ETM
 SG_ AutoUnlockDoorExit_Req : 5|1@0+ (1,0) [0|1] "-" IPC
 SG_ EPB_MaintenanceMode_Req : 7|1@0+ (1,0) [0|1] "-" IPC
 SG_ EV_ConsumptionUnit_Req : 62|3@0+ (1,0) [0|7] "" IPC
 SG_ FlashLightWLock_Req : 6|1@0+ (1,0) [0|1] "-" IPC
 SG_ FSFCWPlusActivationMode_Req : 23|2@0+ (1,0) [0|3] "-" IPC
 SG_ FSFCWPlusSetting_Req : 10|3@0+ (1,0) [0|7] "-" IPC
 SG_ HeadlightsOffDelay_Req : 4|2@0+ (1,0) [0|3] "-" IPC
 SG_ LDW_Intensity_Req : 14|2@0+ (1,0) [0|3] "-" IPC
 SG_ LDW_Sensibility_Req : 0|2@0+ (1,0) [0|3] "-" IPC
 SG_ PowerLevelReq : 42|3@0+ (1,0) [0|7] "-" IPC
 SG_ RemStNrmlStEnbl_Req : 53|2@0+ (1,0) [0|3] "-" IPC
 SG_ TSREnableReq : 27|1@0+ (1,0) [0|1] "" IPC
 SG_ TyrePressureUnit_Req : 2|2@0+ (1,0) [0|3] "-" IPC

BO_ 1291 TELEMATIC_VEHICLE_SETUP3: 8 ETM
 SG_ AutoHoldReq : 56|1@0+ (1,0) [0|1] "" IPC
 SG_ Drowsy_Driver_Alert_Req : 62|1@0+ (1,0) [0|1] "-" IPC
 SG_ Speed_Unit_Req : 55|1@0+ (1,0) [0|1] "" IPC

BO_ 163 TELEMATIC_VEHICLE_SETUP4: 8 ETM
 SG_ GreetingLightsLevel_Req : 35|2@0+ (1,0) [0|3] "" IPC
 SG_ HUtoIPC_NAV_Sts : 9|3@0+ (1,0) [0|6] "" IPC
 SG_ New_Spd_Zone_Ind_Req : 1|2@0+ (1,0) [0|3] "" IPC
 SG_ SignCaptureModeReq : 10|1@0+ (1,0) [0|1] "" IPC
 SG_ Traffic_Sign_Warn_Req : 5|3@0+ (1,0) [0|3] "" IPC

BO_ 192 TELEMATIC_VEHICLE_SETUP5: 8 ETM
 SG_ TSI_WarningTolerance_Req : 8|4@0+ (1,0) [0|15] "" Vector__XXX

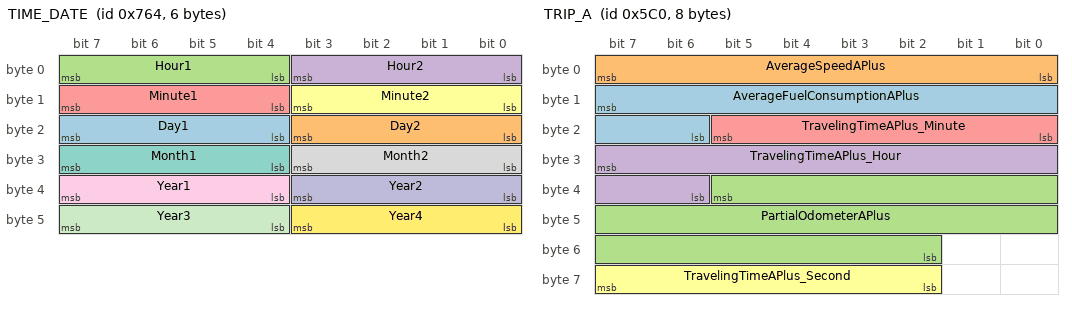
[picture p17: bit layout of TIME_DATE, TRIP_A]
BO_ 1892 TIME_DATE: 6 IPC
 SG_ Day1 : 23|4@0+ (1,0) [0|9] "-" ETM,LTM,RRM,TBM
 SG_ Day2 : 19|4@0+ (1,0) [0|9] "-" ETM,LTM,RRM,TBM
 SG_ Hour1 : 7|4@0+ (1,0) [0|9] "-" ETM,LTM,RRM,TBM
 SG_ Hour2 : 3|4@0+ (1,0) [0|9] "-" ETM,LTM,RRM,TBM
 SG_ Minute1 : 15|4@0+ (1,0) [0|9] "-" ETM,LTM,RRM,TBM
 SG_ Minute2 : 11|4@0+ (1,0) [0|9] "-" ETM,LTM,RRM,TBM
 SG_ Month1 : 31|4@0+ (1,0) [0|9] "-" ETM,LTM,RRM,TBM
 SG_ Month2 : 27|4@0+ (1,0) [0|9] "-" ETM,LTM,RRM,TBM
 SG_ Year1 : 39|4@0+ (1,0) [0|9] "-" ETM,LTM,RRM,TBM
 SG_ Year2 : 35|4@0+ (1,0) [0|9] "-" ETM,LTM,RRM,TBM
 SG_ Year3 : 47|4@0+ (1,0) [0|9] "-" ETM,LTM,RRM,TBM
 SG_ Year4 : 43|4@0+ (1,0) [0|9] "-" ETM,LTM,RRM,TBM

BO_ 1472 TRIP_A: 8 IPC
 SG_ AverageFuelConsumptionAPlus : 15|10@0+ (0.1,0) [0|102.3] "km/l or l/100km or km/kWh" ETM,LTM,RRM,TBM
 SG_ AverageSpeedAPlus : 7|8@0+ (1,0) [0|255] "km/h or mph" ETM,LTM,RRM
 SG_ PartialOdometerAPlus : 37|20@0+ (0.1,0) [0|104857.5] "km or mi." ETM,LTM,RRM,TBM
 SG_ TravelingTimeAPlus_Hour : 31|10@0+ (1,0) [0|1023] "Hour" TBM
 SG_ TravelingTimeAPlus_Minute : 21|6@0+ (1,0) [0|63] "Minute" TBM
 SG_ TravelingTimeAPlus_Second : 63|6@0+ (1,0) [0|63] "Second" TBM

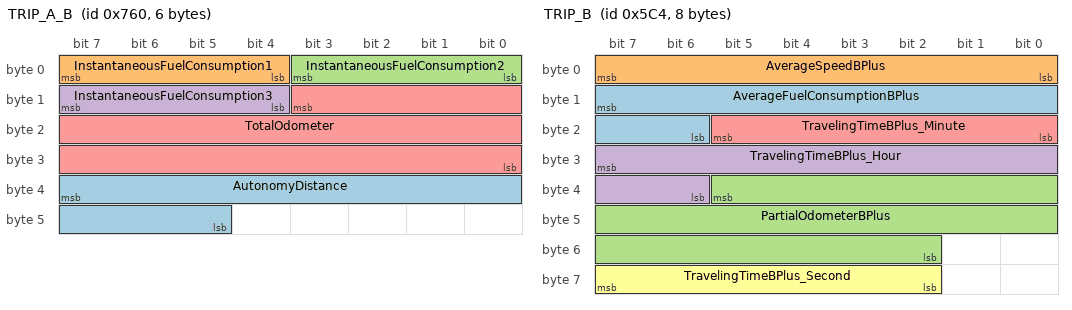
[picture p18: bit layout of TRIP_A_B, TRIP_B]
BO_ 1888 TRIP_A_B: 6 IPC
 SG_ AutonomyDistance : 39|11@0+ (1,0) [0|2047] "km or mi" ETM,LTM,RRM,TBM
 SG_ InstantaneousFuelConsumption1 : 7|4@0+ (1,0) [0|15] "-" ETM,LTM,TBM
 SG_ InstantaneousFuelConsumption2 : 3|4@0+ (1,0) [0|15] "-" ETM,LTM,TBM
 SG_ InstantaneousFuelConsumption3 : 15|4@0+ (1,0) [0|15] "-" ETM,LTM,TBM
 SG_ TotalOdometer : 11|20@0+ (1,0) [0|1048575] "km" AMP,DCSD,ECC,EMCM,ETM,HCPM,LSMD,LSMP,LTM,RRM,TBM

BO_ 1476 TRIP_B: 8 IPC
 SG_ AverageFuelConsumptionBPlus : 15|10@0+ (0.1,0) [0|102.3] "km/l or l/100km or km/kWh" ETM,LTM,TBM
 SG_ AverageSpeedBPlus : 7|8@0+ (1,0) [0|255] "km/h or mph" ETM,LTM
 SG_ PartialOdometerBPlus : 37|20@0+ (0.1,0) [0|104857.5] "km or mi." ETM,LTM,RRM,TBM
 SG_ TravelingTimeBPlus_Hour : 31|10@0+ (1,0) [0|1023] "Hour" Vector__XXX
 SG_ TravelingTimeBPlus_Minute : 21|6@0+ (1,0) [0|63] "Minute" Vector__XXX
 SG_ TravelingTimeBPlus_Second : 63|6@0+ (1,0) [0|63] "Second" Vector__XXX

BO_ 1444 TRIP_D: 8 IPC
 SG_ Electric_Dist_Kilometers : 19|10@0+ (1,0) [0|1023] "km" ETM,LTM,RRM,TBM
 SG_ Electric_Dist_Miles : 25|10@0+ (1,0) [0|1023] "miles" ETM,LTM,RRM,TBM

BO_ 748 U_CONN_REQ: 5 TBM
 SG_ UConnReq : 7|5@0+ (1,0) [0|31] "-" BCM,TBM
 SG_ UConnReqAuthCode : 2|16@0+ (1,0) [0|65535] "-" BCM
 SG_ UConnReqFOBNum : 18|4@0+ (1,0) [0|15] "-" BCM

BO_ 1976 U_CONN_SEED: 4 BCM
 SG_ UConnSeed1 : 31|8@0+ (1,0) [0|255] "" TBM
 SG_ UConnSeed2 : 23|8@0+ (1,0) [0|255] "" TBM
 SG_ UConnSeed3 : 15|8@0+ (1,0) [0|255] "" TBM
 SG_ UConnSeed4 : 7|8@0+ (1,0) [0|255] "" TBM

BO_ 992 VIN: 8 BCM
 SG_ VIN_DATA : 15|56@0+ (1,0) [0|7.20575940379279E+16] "" AMP,DCSD,ECC,EMCM,ETM,HCPM,LSMD,LSMP,LTM,TBM
 SG_ VIN_MSG : 1|2@0+ (1,0) [0|3] "" AMP,DCSD,ECC,EMCM,ETM,HCPM,LSMD,LSMP,LTM,TBM

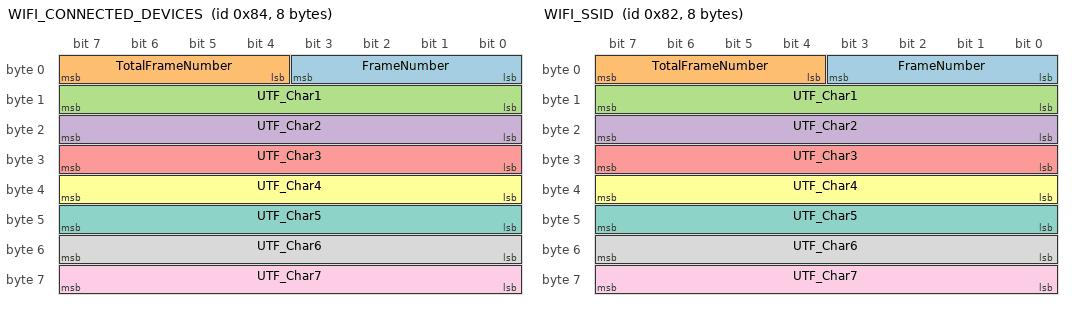
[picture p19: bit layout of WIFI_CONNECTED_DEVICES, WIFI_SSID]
BO_ 132 WIFI_CONNECTED_DEVICES: 8 TBM
 SG_ FrameNumber : 3|4@0+ (1,0) [0|15] "-" ETM,LTM
 SG_ TotalFrameNumber : 7|4@0+ (1,0) [0|15] "-" ETM,LTM
 SG_ UTF_Char1 : 15|8@0+ (1,0) [0|255] "-" ETM,LTM
 SG_ UTF_Char2 : 23|8@0+ (1,0) [0|255] "-" ETM,LTM
 SG_ UTF_Char3 : 31|8@0+ (1,0) [0|255] "-" ETM,LTM
 SG_ UTF_Char4 : 39|8@0+ (1,0) [0|255] "-" ETM,LTM
 SG_ UTF_Char5 : 47|8@0+ (1,0) [0|255] "-" ETM,LTM
 SG_ UTF_Char6 : 55|8@0+ (1,0) [0|255] "-" ETM,LTM
 SG_ UTF_Char7 : 63|8@0+ (1,0) [0|255] "-" ETM,LTM

BO_ 130 WIFI_SSID: 8 TBM
 SG_ FrameNumber : 3|4@0+ (1,0) [0|15] "-" ETM,LTM
 SG_ TotalFrameNumber : 7|4@0+ (1,0) [0|15] "-" ETM,LTM
 SG_ UTF_Char1 : 15|8@0+ (1,0) [0|255] "-" ETM,LTM
 SG_ UTF_Char2 : 23|8@0+ (1,0) [0|255] "-" ETM,LTM
 SG_ UTF_Char3 : 31|8@0+ (1,0) [0|255] "-" ETM,LTM
 SG_ UTF_Char4 : 39|8@0+ (1,0) [0|255] "-" ETM,LTM
 SG_ UTF_Char5 : 47|8@0+ (1,0) [0|255] "-" ETM,LTM
 SG_ UTF_Char6 : 55|8@0+ (1,0) [0|255] "-" ETM,LTM
 SG_ UTF_Char7 : 63|8@0+ (1,0) [0|255] "-" ETM,LTM

BO_TX_BU_ 1283 : ETM,LTM;
BO_TX_BU_ 1284 : ETM,LTM;
BO_TX_BU_ 1289 : ETM,LTM;
BO_TX_BU_ 1454 : ETM,LTM;
BO_TX_BU_ 1470 : ETM,LTM;
BO_TX_BU_ 1480 : ETM,LTM;
BO_TX_BU_ 144 : ETM,LTM;
BO_TX_BU_ 1500 : ETM,LTM;
BO_TX_BU_ 126 : ETM,LTM;
BO_TX_BU_ 136 : ETM,LTM;
BO_TX_BU_ 124 : ETM,LTM;
BO_TX_BU_ 170 : ETM,LTM;
BO_TX_BU_ 156 : ETM,LTM;
BO_TX_BU_ 158 : ETM,LTM;
BO_TX_BU_ 162 : ETM,LTM;
BO_TX_BU_ 1291 : ETM,LTM;
BO_TX_BU_ 163 : ETM,LTM;
BO_TX_BU_ 192 : ETM,LTM;
CM_ SG_ 1283 ManDispCtrl "Manual remote display intensity control";
CM_ SG_ 1283 RQ_DISP_INTS "Requested display intensity";
CM_ SG_ 1284 Radio_Theme "Radio Theme";
CM_ SG_ 1289 ChargeNow "Charge Now Signal";
CM_ SG_ 1452 Lat_Pos "It indicates GPS Latitude (- means south).";
CM_ SG_ 1452 Long_Pos "It indicates GPS Longitude (- means west).";
CM_ SG_ 948 SDW_ChimeActivation_LHF "This signal indicates the chime activation request for the left hand, front audio speaker, or rear hardwired buzzer.";
CM_ SG_ 948 SDW_ChimeActivation_LHR "This signal indicates the chime activation request for the left hand, rear audio speaker, or rear hardwired buzzer.";
CM_ SG_ 948 SDW_ChimeActivation_RHF "This signal indicates the chime activation request for the right hand, front audio speaker, or rear hardwired buzzer.";
CM_ SG_ 948 SDW_ChimeActivation_RHR "This signal indicates the chime activation request for the right hand, rear audio speaker, or rear hardwired buzzer.";
CM_ SG_ 948 SDW_ChimeRepetitionRate_Left "This signal indicates the repetition rate for the left audio speakers.";
CM_ SG_ 948 SDW_ChimeRepetitionRate_Right "This signal indicates the repetition rate for the right audio speakers.";
CM_ SG_ 948 SDW_ChimeType_Left "This signal indicates the Chime Type for the left audio speakers.";
CM_ SG_ 948 SDW_ChimeType_Right "This signal indicates the Chime Type for the right audio speakers.";
CM_ SG_ 948 SDW_DisplayActivation "This signal indicates the request to display the car graphics layout on the IPC/EVIC screen.";
CM_ SG_ 948 SDW_ObstacleInTrajectory_LLF "This signal is used to indicate if the detected obstacle is inside or outside of the vehicle path.";
CM_ SG_ 948 SDW_ObstacleInTrajectory_LLR "This signal is used to indicate if the detected obstacle is inside or outside of the vehicle path.";
CM_ SG_ 948 SDW_ObstacleInTrajectory_LRF "This signal is used to indicate if the detected obstacle is inside or outside of the vehicle path.";
CM_ SG_ 948 SDW_ObstacleInTrajectory_LRR "This signal is used to indicate if the detected obstacle is inside or outside of the vehicle path.";
CM_ SG_ 948 SDW_Warning_Left_1 "This signal is used to turn lateral arc";
CM_ SG_ 948 SDW_Warning_Left_2 "This signal is used to turn lateral arc";
CM_ SG_ 948 SDW_Warning_Right_1 "This signal is used to turn lateral arc";
CM_ SG_ 948 SDW_Warning_Right_2 "This signal is used to turn lateral arc";
CM_ SG_ 173 ADAS_Seg_BuildUpArea "This signal indicates the segment built-up area status.";
CM_ SG_ 173 ADAS_Seg_DividedRoad "This signal indicates the Segment Divided Road.";
CM_ SG_ 173 ADAS_Seg_EffSpdLmt "This signal indicates the Effective/Current Speed Limit.";
CM_ SG_ 173 ADAS_Seg_EffSpdLmtType "This signal indicates the Effective Speed Limit Type.";
CM_ SG_ 173 ADAS_Seg_FormOfWay "This signal indicates the Form of Way.";
CM_ SG_ 173 ADAS_Seg_FuncRoadClass "This signal indicates the Functional Road Class.";
CM_ SG_ 173 ADAS_Seg_NumOfLaneDrvDir "This signal indicates the number of lanes in driving direction.";
CM_ SG_ 173 ADAS_Seg_PathIdx "This signal indicates the Path Index.";
CM_ SG_ 1454 CallAction "It indicates the call action chosen by the user  through the Radio.";
CM_ SG_ 1454 CallRequest "It indicates the type of call requested by the user through the Radio.";
CM_ SG_ 1454 TBMUpdateAction "It indicates the TBM update action chosen by the user  through the Radio";
CM_ SG_ 1454 WiFiReq "It indicates the user interaction to change the WiFi modem status through the Radio.";
CM_ SG_ 1446 ClearPersonalData "It is used to give information about the Clear Personal Data functionality.";
CM_ SG_ 1446 PrivacyMode "It is used to give information about  the Privacy Mode functionality.";
CM_ SG_ 1446 RestoreApp "It is used to give information about the Restore App functionality.";
CM_ SG_ 1446 RestoreDefaultSetting "It is used to give information about the Restore Default Setting functionality.";
CM_ SG_ 1446 TelematicSetupAck "It is used to give information about the acknowledge of the requested setup changes by telematic module.";
CM_ SG_ 1890 DaysToService "Used to give information about the missing days for the next vehicle service.";
CM_ SG_ 1890 DistanceToService "Used to give information about the missing distance for the next vehicle service.";
CM_ SG_ 2000 AMP_DSS_STATSts "Driver Select Surround Status";
CM_ SG_ 2000 AMP_MUTEDSts "Amplifer mute status; unmuted = [0], muted = [1]";
CM_ SG_ 2000 AUDIOSts_AMP "Used to give information about Telematic Module audio availability";
CM_ SG_ 2000 SURR_AVAILSts "Surround sound available for selected cabin mode; [1] = True";
CM_ SG_ 854 BonnetSts "Used to indicate the status of the bonnet";
CM_ SG_ 854 FrontWiperMoveSts "This signal indicates the position of the front wiper (contact cam open or close).";
CM_ SG_ 854 LHRDoorSts "Used to indicate the status of left rear door";
CM_ SG_ 854 ParkBrakeSts "Status of Park Brake";
CM_ SG_ 854 RainSensorFailSts "This signal indicates a Rain sensor fail.";
CM_ SG_ 854 RearTrunkEnableLastElSts "It specifies the electric status of the rear trunk switch";
CM_ SG_ 854 RHatchSts "Used to indicate the status of the trunk liftgate";
CM_ SG_ 854 RHRDoorSts "Used to indicate the status of right rear door";
CM_ SG_ 854 WarningKeyInSts "This signal activates a buzzer when the driver door is open and the key is in the starting system.";
CM_ SG_ 1132 BatteryChargeSts "Battery State of Charge (in %), as acquired from the battery sensor";
CM_ SG_ 1132 BatteryVoltageLevel "This signal is used to indicate the voltage level of the battery";
CM_ SG_ 1132 CmdIgnSts "Used to give information about the key selector position";
CM_ SG_ 1132 DriveStyleSts "This signal gives indications about drive style status required.";
CM_ SG_ 1132 ExternalTemperatureC "Used to indicate the external temperature value in °C";
CM_ SG_ 1132 ExternalTemperatureF "Used to indicate the external temperature value in °F";
CM_ SG_ 1132 ExternalTemperatureFailSts "Used to indicate if a Fail is present for the external temperature value";
CM_ SG_ 1132 InternalLightSts "Used to give information about backlight mode selected (Day or Night).";
CM_ SG_ 1132 RemStActvSts "Ignition Run active for remote start";
CM_ SG_ 1450 PreCondActvSts "Cabin Pre Condition Status";
CM_ SG_ 1450 RecoveryIgnOffInd "This signal is used to enable the indication for ignition off manual procedure.";
CM_ SG_ 1128 InternalLightLevel2 "This signal is used to modulate the Internal Light Level";
CM_ SG_ 988 LatAcceleration_BSM "This signal indicates the Lateral Acceleration Value";
CM_ SG_ 988 LatAccelerationFailSts_BSM "This signal indicates the status of Lateral Acceleration Signal";
CM_ SG_ 988 LongAcceleration_BSM "This signal indicates the Longitudinal Acceleration Value";
CM_ SG_ 988 LongAccelerationFailSts_BSM "This signal indicates the status of Longitudinal acceleration signal";
CM_ SG_ 988 YawRate_BSM "This signal indicates the Yaw Rate Value";
CM_ SG_ 988 YawRateFailSts_BSM "This signal indicates the Status of Yaw Rate Signal";
CM_ SG_ 990 LHF_FastPulseCounter "This signal is the left front wheel pulse counter.";
CM_ SG_ 990 LHF_WheelSensorFailSts "This signal indicates the fail status of LHF sensor";
CM_ SG_ 990 LHR_FastPulseCounter "This signal is the left rear wheel pulse counter.";
CM_ SG_ 990 LHR_WheelSensorFailSts "This signal indicates the fail status of LHR sensor";
CM_ SG_ 990 RHF_FastPulseCounter "This signal is the right front wheel pulse counter.";
CM_ SG_ 990 RHF_WheelSensorFailSts "This signal indicates the fail status of RHF sensor";
CM_ SG_ 990 RHR_FastPulseCounter "This signal is the right rear wheel pulse counter.";
CM_ SG_ 990 RHR_WheelSensorFailSts "This signal indicates the fail status of RHR sensor";
CM_ SG_ 994 PowertrainPrplsnActv "Propulsion status.";
CM_ SG_ 994 VehicleSpeedVSOSig "It is the average vehicle speed calculated.";
CM_ SG_ 994 VehicleSpeedVSOSigFailSts "It is the average vehicle speed fail status.";
CM_ SG_ 996 ReverseGearSts "It gives information of reverse gear status.";
CM_ SG_ 998 AirTemp_Outsd "Outside air temperature External Temp Non Filtered";
CM_ SG_ 1984 InflationState_LHF_Tyre "It signal indicated the state for the pressure of the wheel identified";
CM_ SG_ 1984 InflationState_LHR_Tyre "It signal indicated the state for the pressure of the wheel identified";
CM_ SG_ 1984 InflationState_RHF_Tyre "It signal indicated the state for the pressure of the wheel identified";
CM_ SG_ 1984 InflationState_RHR_Tyre "It signal indicated the state for the pressure of the wheel identified";
CM_ SG_ 1984 TyrePressureSystemFailSts "It indicates that the TPM System is in Fault or not";
CM_ SG_ 1426 AEB_CHIME_TYPSts "Selected Chime Type for ACC/FCW  warnings";
CM_ SG_ 1426 AEB_LF_CHIME_RQSts "Left Front Chime Activation Request";
CM_ SG_ 1426 AEB_RF_CHIME_RQSts "Right Front Chime Activation Request";
CM_ SG_ 1426 DDAActivationFeedback "This signal specifies the activation state of Drowsy Driver Assist";
CM_ SG_ 1426 DDAFailSts "This signal gives information about the fail status of DDA";
CM_ SG_ 1426 WarningLevel "This signal gives information about the warning status of Driver Drowsing Assistant";
CM_ SG_ 1130 CompressorACReqSts "Used to indicate the user request of compressor activation";
CM_ SG_ 1130 FHeatedWindowCmd "Used to require the Front heated window activation/deactivation";
CM_ SG_ 1130 HVAC_Blower_Speed "The signal indicates the PWM command for Blower and blower status";
CM_ SG_ 1130 MaxDefrostSts "Used to indicate the user request status of Max Defrost";
CM_ SG_ 1130 RHeatedWindowCmd "Used to require the Rear heated window activation/deactivation.";
CM_ SG_ 1130 StopStartClimateInfo "Stop start enable from ECC";
CM_ SG_ 1130 StopStartEnable "Sent by ECC (if present) it signals the consent by climate control to the Stop&Start function";
CM_ SG_ 1482 HVACAC_Sts "Used to indicate the air conditioning request status";
CM_ SG_ 1482 HVACAuto_Sts "Used to indicate the Auto function request status";
CM_ SG_ 1482 HVACBlower_Sts "Used to indicate the Blower speed selection status";
CM_ SG_ 1482 HVACControl_Sts "Used to indicate the status of Blower and Mode (auto or manual)";
CM_ SG_ 1482 HVACMaxAC_Sts "Used to indicate the Max AC request status";
CM_ SG_ 1482 HVACMode_Sts "Used to indicate the Mode selection status";
CM_ SG_ 1482 HVACRearDef_Sts "Used to indicate the Rear Defrost request status";
CM_ SG_ 1482 HVACRecirc_Sts "Used to indicate the Recirculation status";
CM_ SG_ 1483 HVACDRVTemp "Front driver temperature status";
CM_ SG_ 1904 DEFROST_SEL "Defrost select switch";
CM_ SG_ 1904 DRV_TEMP_DR_POS "Driver temperature door postion";
CM_ SG_ 1904 EvapTempTar "Evaporator temperature target";
CM_ SG_ 1904 HtrCorTmp_InTgt "Heater core temp target";
CM_ SG_ 1904 HVAC_Blwr_Perct "HVAC blower PWM percentage for service mode";
CM_ SG_ 1904 VEH_INT_TEMP "Vehicle interior temperature";
CM_ SG_ 1448 AHP_EnblReq "Used to require the activation of Auxiliary Heater Pump";
CM_ SG_ 1448 AirHtwPwrTgt "Used to give the target power to Electric Air Heater";
CM_ SG_ 1448 EVAP_TEMP_P1C "Evaporator Temperature";
CM_ SG_ 1448 PreCondCabinSts "HVAC Pre-Condition Status";
CM_ SG_ 1169 FL_HS_STATFailSts "It indicates a fail in Front Left heated seat";
CM_ SG_ 1169 FL_HS_STATSts "Front left heated seat status";
CM_ SG_ 1169 FR_HS_STATFailSts "It indicates a fail in Front Right heated seat";
CM_ SG_ 1169 FR_HS_STATSts "Front right heated seat status";
CM_ SG_ 1899 AirHtrPwrCnsAct "Used to give information about actual heater power consumption";
CM_ SG_ 1899 CompStat "Comppressor state";
CM_ SG_ 1899 FRfShVlvSts "Front Refrigerant Shutoff Valve Status";
CM_ SG_ 1899 HVBatCritCondT "High Voltage Battery Temperature Critical Condition, [1] = True";
CM_ SG_ 1899 R134a_PressSts "Refrigerant pressure (R134a or R1234YF)";
CM_ SG_ 1899 TurtleModeSts "Turtle mode status.";
CM_ SG_ 1512 AirHtrCoreTemp "Electric Air Heater Core Temperature";
CM_ SG_ 1512 AirHtrPCBTemp "Electric Air Heater PCB Temperature";
CM_ SG_ 1512 Cabin_Condition_Sts "Cabin Condition Status";
CM_ SG_ 1512 ChargingLevel "Charging level and type.";
CM_ SG_ 1512 ChargingSysSts "Charging System status";
CM_ SG_ 1512 ChrgSysFault "Charging System Fault status";
CM_ SG_ 1512 HVBatSOC_HCP "High voltage battery state of charge";
CM_ SG_ 1512 HVBatSOCV_HCP "High voltage battery state of charge validity: invalid = [1]";
CM_ SG_ 1512 SchCond_Time_Till_Dep "Schedule Cabin Conditonting - Time till Departure for HVAC";
CM_ SG_ 1512 Service_Battery_Recharge_FailSts "Information about status of Service_Battery_Recharge";
CM_ SG_ 1268 FrontSensorSts "This signal indicates the activation state of the front sensors.";
CM_ SG_ 1268 LateralSensorSts "This signal indicates the activation state of the lateral sensors";
CM_ SG_ 1268 PAMAboveSpeed "This signal is used to manage a indication, related to the deactivation of PAM system, when the vehicle speed is too high.";
CM_ SG_ 1268 PAMSystemFault "This signal indicates if the PAM is in a faulted condition";
CM_ SG_ 1268 PAMSystemSts "This signal indicates the activation state of the PAM";
CM_ SG_ 1268 RearSensorSts "This signal indicates the activation state of the rear sensors";
CM_ SG_ 1268 SDWFailSts "The signal is used to indicate a failure in the function";
CM_ SG_ 1458 AudioRequest "It indicates the request to use the audio radio system";
CM_ SG_ 1458 BUBFailSts "It indicates the faults of the Back Up Battery of the TBM";
CM_ SG_ 1458 CallSts "It indicates the service call status";
CM_ SG_ 1458 CallType "It indicates the service call type";
CM_ SG_ 1458 GPSFailSts "It indicates the fault of the GPS system";
CM_ SG_ 1458 IVA "It indicate whether the IVA Call procedure is ongoing or not";
CM_ SG_ 1458 LTESts "It is used to show the cell network level";
CM_ SG_ 1458 MuteRequest "It indicates the request to mute the audio radio system";
CM_ SG_ 1458 NetConnection "It is used to estimate data connection";
CM_ SG_ 1458 Provisioning "It is used to enable or disable the call provisioning";
CM_ SG_ 1458 SignalStrength "It is used to show the cell signal strength";
CM_ SG_ 1458 SOSCallStatus "SOS call function status";
CM_ SG_ 1458 SOSCallType "Type of SOS call";
CM_ SG_ 1458 SOSFailSts "It indicates the fault of the SOS call system";
CM_ SG_ 1458 SystemFailSts "It indicates a generic system internal fail";
CM_ SG_ 1458 WiFiFailSts "It indicates the fault of the WiFi modem";
CM_ SG_ 1458 WiFiSts "It indicates the status of the WiFi modem";
CM_ SG_ 1470 AntitheftSts "ETM Antitheft logic status";
CM_ SG_ 1470 AUDIOSts_Telematic "Used to give information about Telematic Module audio availability";
CM_ SG_ 1470 CurrentSource "ETM current active source";
CM_ SG_ 1470 HFPSts "ETM hands free phone status";
CM_ SG_ 1470 MicrophoneFailSts "This signal is used to determinate an Eletric Fault for the microphone.";
CM_ SG_ 1470 MuteSts "ETM Entertainment source Mute status";
CM_ SG_ 1470 PowerSts_Telematic "ETM power status";
CM_ SG_ 1470 VolumeSts "Indicates the value of Volume set on radio";
CM_ SG_ 1470 VolumeUnit "Indicates if the volume of the radio is a percentage or an integer value";
CM_ SG_ 1470 VRSts "ETM Voice Recognition  Status";
CM_ SG_ 1206 Ubss_Blind_RQSts "Urban Blind spot sensor blinded";
CM_ SG_ 1206 Ubss_Cfg_StatSts "Urban Blind Spot System configuration status";
CM_ SG_ 1206 Ubss_LF_Chime_RQSts "Urban Blind Spot System left front chime on request";
CM_ SG_ 1206 Ubss_LR_Chime_RQSts "Urban Blind Spot System left rear chime on request";
CM_ SG_ 1206 Ubss_LT_Chime_TypeSts "Urban Blind Spot system left side chime type";
CM_ SG_ 1206 Ubss_OPR_StatSts "Urban Blind Spot system operation status";
CM_ SG_ 1206 Ubss_RF_Chime_RQSts "Urban Blind Spot System right front chime on request";
CM_ SG_ 1206 Ubss_RR_Chime_RQSts "Urban Blind Spot System right rear chime on request";
CM_ SG_ 1206 Ubss_RT_Chime_TypeSts "Urban Blind Spot system right side chime type";
CM_ SG_ 1206 Ubss_SRV_RQSts "Urban Blind Spot system service warning request";
CM_ SG_ 1206 Ubss_Sts "Urban Blind spot System state";
CM_ SG_ 1206 UbssLtLedFaultSts "Urban Blind Spot left led fault status";
CM_ SG_ 1206 UbssLtWrnSts "Urban Blind Spot left led warning Status";
CM_ SG_ 1206 UbssRtLedFaultSts "Urban Blind Spot right led fault status";
CM_ SG_ 1206 UbssRtWrnSts "Urban Blind Spot right led warning status";
CM_ SG_ 750 Command_01Sts "Infotainment Switch 1";
CM_ SG_ 750 Command_02Sts "Infotainment Switch 2";
CM_ SG_ 750 Command_03Sts "Infotainment Switch 3";
CM_ SG_ 750 Command_04Sts "Infotainment Switch 4";
CM_ SG_ 750 Command_05Sts "Infotainment Switch 5";
CM_ SG_ 750 Command_06Sts "Infotainment Switch 6";
CM_ SG_ 750 Command_07Sts "Infotainment Switch 7";
CM_ SG_ 750 Command_08Sts "Infotainment Switch 8";
CM_ SG_ 750 Command_09Sts "Infotainment Switch 9";
CM_ SG_ 750 Command_10Sts "Infotainment Switch 10";
CM_ SG_ 750 Command_11Sts "Infotainment Switch 11";
CM_ SG_ 750 Command_12Sts "Infotainment Switch 12";
CM_ SG_ 750 Command_13Sts "Infotainment Switch 13";
CM_ SG_ 750 Command_14Sts "Infotainment Switch 14";
CM_ SG_ 750 Command_15Sts "Infotainment Switch 15";
CM_ SG_ 178 ChargeNow "Charge Now Signal";
CM_ SG_ 172 Batt_CabinPriority1 "Bit to prioritize cabin conditioning under schedule 1";
CM_ SG_ 172 ChargeUntilFull1 "Charge until battery is fully charged with schedule 1";
CM_ SG_ 172 Do_Not_Repeat1 "Do not repeat the set Schedule";
CM_ SG_ 172 Enable_Schedule1 "Schedule 1 checkbox enabled";
CM_ SG_ 172 End_Time_Hr1 "End Time of schedule 1 (hours in 24 hrs. format)";
CM_ SG_ 172 End_Time_Min1 "End Time of schedule 1(Minutes)";
CM_ SG_ 172 Schedule_Day1 "Schedule#1 Day for charging or cabin conditioning";
CM_ SG_ 172 Schedule_Type1 "Type of charging and climate schedule";
CM_ SG_ 172 Start_Time_Hr1 "Start Time of schedule  1 (hours in 24 hrs. format)";
CM_ SG_ 172 Start_Time_Min1 "Start Time of schedule  1 (minutes)";
CM_ SG_ 172 Submit_Schedule1 "Schedule 1 submitted";
CM_ SG_ 174 Batt_CabinPriority2 "Bit to prioritize battery charging or cabin conditioning under schedule 2";
CM_ SG_ 174 ChargeUntilFull2 "Charge until battery is fully charged with schedule 2";
CM_ SG_ 174 Do_Not_Repeat2 "Do not repeat the set Schedule";
CM_ SG_ 174 Enable_Schedule2 "Schedule 2 checkbox enabled";
CM_ SG_ 174 End_Time_Hr2 "End Time of schedule  2 (hours in 24 hrs. format)";
CM_ SG_ 174 End_Time_Min2 "End Time of schedule  2(Minutes)";
CM_ SG_ 174 Schedule_Day2 "Schedule#2 Day for charging or cabin conditioning";
CM_ SG_ 174 Schedule_Type2 "Type of charging and climate schedule";
CM_ SG_ 174 Start_Time_Hr2 "Start Time of schedule  2(hours in 24 hrs. format)";
CM_ SG_ 174 Start_Time_Min2 "Start Time of schedule  2 (minutes)";
CM_ SG_ 174 Submit_Schedule2 "Schedule 2 submitted";
CM_ SG_ 176 Batt_CabinPriority3 "Bit to prioritize battery charging or cabin conditioning under schedule 3";
CM_ SG_ 176 ChargeUntilFull3 "Charge until battery is fully charged with schedule 3";
CM_ SG_ 176 Do_Not_Repeat3 "Do not repeat the set Schedule";
CM_ SG_ 176 Enable_Schedule3 "Schedule 3 checkbox enabled";
CM_ SG_ 176 End_Time_Hr3 "End Time of schedule  3 (hours in 24 hrs. format)";
CM_ SG_ 176 End_Time_Min3 "End Time of schedule  3 (Minutes)";
CM_ SG_ 176 Schedule_Day3 "Schedule#3 Day for charging or cabin conditioning";
CM_ SG_ 176 Schedule_Type3 "Type of charging and climate schedule";
CM_ SG_ 176 Start_Time_Hr3 "Start Time of schedule  3 (hours in 24 hrs. format)";
CM_ SG_ 176 Start_Time_Min3 "Start Time of schedule  3 (minutes)";
CM_ SG_ 176 Submit_Schedule3 "Schedule 3 submitted";
CM_ SG_ 1480 FL_HS_Cmd_Tlm_Req "Used to command front right heated seat";
CM_ SG_ 1480 FR_HS_Cmd_Tlm_Req "Used to command front left  heated seat";
CM_ SG_ 1480 HVAC_MAXDef_Req "MAX Def Req signal";
CM_ SG_ 1480 HVACAC_Req "Used to require the AC function";
CM_ SG_ 1480 HVACAuto_Req "Used to require the Auto function";
CM_ SG_ 1480 HVACFrontDef_Req "Used to require the Front Defrost function";
CM_ SG_ 1480 HVACFunc_Req "Used to indicate the blower speed and temperature selection";
CM_ SG_ 1480 HVACJumpVAL "Used to indicate the amount of jump function";
CM_ SG_ 1480 HVACMaxAC_Req "Used to require the Max AC function";
CM_ SG_ 1480 HVACMode_Req "Used to indicate the mode selection";
CM_ SG_ 1480 HVACPower_Req "Used to Power On/Off the climate";
CM_ SG_ 1480 HVACRearDef_Req "Used to require the Rear Defrost function";
CM_ SG_ 1480 HVACRecirc_Req "Used to open/close the recirculation flap";
CM_ SG_ 1052 Radio_btn0_Req "Indicates the status of  radio button0";
CM_ SG_ 1052 Radio_btn1_Req "Indicates the status of  radio button1";
CM_ SG_ 1052 Radio_Knob1_DIR_Req "Knob direction";
CM_ SG_ 1052 Radio_Knob1_VAL_Req "Knob value";
CM_ SG_ 1502 TGW_PT_CAB_DRSts "TGW pointer for Cabin/driver";
CM_ SG_ 1502 TGW_RQ1Sts "TGW request1";
CM_ SG_ 1500 TGW_DISP_STATSts "TGW Display status";
CM_ SG_ 126 CurrTimeMin "Indicates the current time of played multimedia (minutes)";
CM_ SG_ 126 CurrTimeSec "Indicates the current time of played multimedia (seconds)";
CM_ SG_ 126 DLS "Indicates which DLS information is available with DAB source";
CM_ SG_ 126 PresetNumber "Indicates the index in Presets list of the actual AM, FM or DAB station";
CM_ SG_ 126 Presets "Indicates if the actual AM, FM or DAB station is saved in Presets list";
CM_ SG_ 126 ProgressBarPerc "Indicates the progress bar time of played multimedia";
CM_ SG_ 126 PTY "Indicates which PTY information is available with FM/DAB source";
CM_ SG_ 126 RadioText "Indicates which RadioText information is available with FM source";
CM_ SG_ 126 TotDurMin "Indicates the total duration of current played multimedia (minutes)";
CM_ SG_ 126 TotDurSec "Indicates the total duration of current played multimedia (seconds)";
CM_ SG_ 126 TrafficAnnouncement "Indicates if Traffic Announcement is enabled and/or active";
CM_ SG_ 124 BatteryLevel "Indicates the available battery charge of the connected mobile phone";
CM_ SG_ 124 ConnectedPhoneID "Indicates the ID of the connected phone with HU";
CM_ SG_ 124 IsFavorite "Indicates if the connected phone to HU is in the Favorite List";
CM_ SG_ 124 NetworkID "Indicates the ID of the actual available network on connected phone";
CM_ SG_ 124 PowerSignal "Indicates the power signal of the connected mobile phone";
CM_ SG_ 170 ClearPersonalDataReq "It is managed when the driver requests a setting of Clear Personal Data.";
CM_ SG_ 170 PrivacyModeReq "It is managed when the driver requests a setting of Privacy Mode.";
CM_ SG_ 170 RestoreAppReq "It is managed when the driver requests a setting of  Restore App.";
CM_ SG_ 170 RestoreDefaultSettingReq "It is managed when the driver requests a setting of  Restore Default Setting.";
CM_ SG_ 158 AutoHighBeamEnable_Req "This signal is managed when the driver requests a setting of  the Auto High Beam feature";
CM_ SG_ 158 AutoParkBrake_Req "This signal is managed when the driver requests a setting of the Auto Park Brake";
CM_ SG_ 158 BSDEnable_Req "This signal is managed when the driver requests a setting of Blind Spot Alert";
CM_ SG_ 158 CorneringEnable_Req "This signal is managed when the driver requests a setting of Cornering Lights";
CM_ SG_ 158 DistanceUnit_Req "This signal is managed when the driver requests a setting of Distance Unit";
CM_ SG_ 158 DRLEnable_Req "This signal is managed when the driver requests a setting of the DRL feature";
CM_ SG_ 158 ExternalLightSensorLevel_Req "This signal is managed when the driver requests a setting of External Light Sensor Level";
CM_ SG_ 158 HourMode_Req "This signal is managed when the driver requests a setting of Hour Mode";
CM_ SG_ 158 LanguageSelection_Req "This signal is managed when the driver requests a setting of Language";
CM_ SG_ 158 PamAlertMode_Req "This signal is managed when the driver requests a setting of the PAM Alert Mode";
CM_ SG_ 158 PamChimeVolumeFront_Req "This signal is managed when the driver request a  setting of the of Chime Volume  of the PAM";
CM_ SG_ 158 PamChimeVolumeRear_Req "This signal is managed when the driver request a  setting of the of Chime Volume  of the PAM  8  Channels";
CM_ SG_ 158 PassiveEntry_Req "This signal is managed when the driver requests a setting of the Passive Entry";
CM_ SG_ 158 RainSensorLevel_Req "This signal is managed when the driver requests a setting of Rain Sensor Level";
CM_ SG_ 158 RemoteDoorUnlock_Req "This signal is managed when the driver requests a setting of the Remote Door Unlock";
CM_ SG_ 158 Sdw_Req "This signal is managed when the driver request a  setting of the Sdw";
CM_ SG_ 158 SoundHornLock_Req "This signal is managed when the driver requests a setting of the Sound Horn with Unlock";
CM_ SG_ 158 SoundHornRemoteStart_Req "This signal is managed when the driver requests a setting of the Sound Horn with Remote Start";
CM_ SG_ 158 SpeedLockDoorEnable_Req "This signal is managed when the driver requests a setting of Auto Door Locks";
CM_ SG_ 158 TemperatureUnit_Req "This signal is managed when the driver requests a setting of Temperature Unit";
CM_ SG_ 162 AutoUnlockDoorExit_Req "This signal is managed when the driver request a setting of  Auto Unlock Door On Exit";
CM_ SG_ 162 EPB_MaintenanceMode_Req "This signal is managed when the driver request a setting of  Maintenance Mode";
CM_ SG_ 162 EV_ConsumptionUnit_Req "This signal is managed when the driver requests a setting of Electrical Consumption Unit";
CM_ SG_ 162 FlashLightWLock_Req "This signal is managed when the driver request a setting of  Flash Light With Lock";
CM_ SG_ 162 FSFCWPlusActivationMode_Req "This signal is managed when the driver request a  setting of FSFCW";
CM_ SG_ 162 FSFCWPlusSetting_Req "This signal is managed when the driver request a  setting of FSFCW";
CM_ SG_ 162 HeadlightsOffDelay_Req "This signal is managed when the driver requests a setting of the Headligts Off Delay";
CM_ SG_ 162 LDW_Intensity_Req "This signal is managed when the driver requests a setting of the LDW Intensity";
CM_ SG_ 162 LDW_Sensibility_Req "This signal is managed when the driver requests a setting of  the LDW Sensibility";
CM_ SG_ 162 PowerLevelReq "This signal is menaged when the driver requests the Power Level setting";
CM_ SG_ 162 RemStNrmlStEnbl_Req "Setting to allow seat heating and venting for all starts, remote starts, or none";
CM_ SG_ 162 TSREnableReq "This signal is managed when the driver requests a setting of the TSR feature";
CM_ SG_ 162 TyrePressureUnit_Req "This signal is managed when the driver requests a setting of  the Tyre Pressure Unit";
CM_ SG_ 1291 AutoHoldReq "Auto Hold setting request";
CM_ SG_ 1291 Drowsy_Driver_Alert_Req "Drowsy Driver Alert setting request";
CM_ SG_ 1291 Speed_Unit_Req "Speed Unit setting request";
CM_ SG_ 163 GreetingLightsLevel_Req "This signal is managed when the driver requests a setting of  Greeting Lights Level";
CM_ SG_ 163 HUtoIPC_NAV_Sts "HU to IPC NAV status.";
CM_ SG_ 163 New_Spd_Zone_Ind_Req "New Speed Zone Indication setting request";
CM_ SG_ 163 SignCaptureModeReq "Intelligent Speed Mode setting request";
CM_ SG_ 163 Traffic_Sign_Warn_Req "Traffic Sign Warning setting request";
CM_ SG_ 192 TSI_WarningTolerance_Req "Gives the Warning Tollerance request to apply to Traffic Sign Information.";
CM_ SG_ 1892 Day1 "It is the first digit of the day for the date visualization";
CM_ SG_ 1892 Day2 "It is the second digit of the day for the date visualization";
CM_ SG_ 1892 Hour1 "It is the first digit of the hours for the clock visualization";
CM_ SG_ 1892 Hour2 "It is the second digit of the hours for the clock visualization";
CM_ SG_ 1892 Minute1 "It is  the first digit of the minutes for the clock visualization";
CM_ SG_ 1892 Minute2 "It is the second digit of the minutes for the clock visualization";
CM_ SG_ 1892 Month1 "It is the first digit of the month for the date visualization";
CM_ SG_ 1892 Month2 "It is the second digit of the month for the date visualization";
CM_ SG_ 1892 Year1 "It is the first digit of the year for the date visualization";
CM_ SG_ 1892 Year2 "It is the second digit of the year for the date visualization";
CM_ SG_ 1892 Year3 "It is the third digit of the year for the date visualization";
CM_ SG_ 1892 Year4 "It is the fourth digit of the year for the date visualization";
CM_ SG_ 1472 AverageFuelConsumptionAPlus "Used to give information about the average fuel consumption for Trip A.";
CM_ SG_ 1472 AverageSpeedAPlus "Used to give information about the average speed for Trip A.";
CM_ SG_ 1472 PartialOdometerAPlus "Used to give information about the partial odometer for Trip A";
CM_ SG_ 1472 TravelingTimeAPlus_Hour "Used to give information about hours of travel time for Trip A.";
CM_ SG_ 1472 TravelingTimeAPlus_Minute "Used to give information about minutes of travel time for Trip A.";
CM_ SG_ 1472 TravelingTimeAPlus_Second "Used to give information about seconds of travel time for Trip A";
CM_ SG_ 1888 AutonomyDistance "Used to give information about the distance to empty.";
CM_ SG_ 1888 InstantaneousFuelConsumption1 "Used to give information about the tens of the instantaneous fuel consumption value.";
CM_ SG_ 1888 InstantaneousFuelConsumption2 "Used to give information about the units of the instantaneous fuel consumption value.";
CM_ SG_ 1888 InstantaneousFuelConsumption3 "Used to give information about the tenths of the instantaneous fuel consumption value.";
CM_ SG_ 1888 TotalOdometer "Used to give information about the total odometer value in km.";
CM_ SG_ 1476 AverageFuelConsumptionBPlus "Used to give information about the average fuel consumption for Trip B.";
CM_ SG_ 1476 AverageSpeedBPlus "Used to give information about the average speed for Trip B.";
CM_ SG_ 1476 PartialOdometerBPlus "Used to give information about the partial odometer for Trip B.";
CM_ SG_ 1476 TravelingTimeBPlus_Hour "Used to give information about hours of travel time for Trip B.";
CM_ SG_ 1476 TravelingTimeBPlus_Minute "Used to give information about minutes of travel time for Trip B.";
CM_ SG_ 1476 TravelingTimeBPlus_Second "Used to give information about seconds of travel time for Trip B";
CM_ SG_ 1444 Electric_Dist_Kilometers "Electric distance traveled during IgnCycle in kilometers";
CM_ SG_ 1444 Electric_Dist_Miles "Electric distance traveled during IgnCycle in US miles";
CM_ SG_ 748 UConnReq "Requests specific vehicle function";
CM_ SG_ 748 UConnReqAuthCode "Authenticates function requests";
CM_ SG_ 748 UConnReqFOBNum "Indicates Corresponding  FOB number 1-8";
CM_ SG_ 1976 UConnSeed1 "random # for security, Character 1";
CM_ SG_ 1976 UConnSeed2 "random # for security, Character 2";
CM_ SG_ 1976 UConnSeed3 "random # for security, Character 3";
CM_ SG_ 1976 UConnSeed4 "random # for security, Character 4";
CM_ SG_ 992 VIN_DATA "VIN Digits (8 bit ascii encoded)";
CM_ SG_ 992 VIN_MSG "VIN Message Information";

BA_DEF_ SG_ "Accuracy" STRING ;
BA_DEF_ SG_ "Event trans." ENUM "Yes","No";
BA_DEF_ SG_ "GenSigStartValue" INT 0 2147483647;
BA_DEF_ SG_ "GenSigInactiveValue" INT 0 2147483647;
BA_DEF_ SG_ "GenSigSendType" ENUM "NotUsed","OnWrite","OnWriteWithRepetition","OnChange","OnChangeWithRepetition","IfActive","IfActiveWithRepetition","NoSigSendType";
BA_DEF_ SG_ "SystemSignalLongSymbol" STRING ;
BA_DEF_ BO_ "DiagRequest" ENUM "No","Yes";
BA_DEF_ BO_ "Period [ms]" INT 0 65535;
BA_DEF_ BO_ "Type" ENUM "P","C","PE","COC","PE_Cntrl","E","E_Cntrl","OC","S","BAF","DC","EM","MM","-";
BA_DEF_ BO_ "DiagResponse" ENUM "No","Yes";
BA_DEF_ BO_ "NmMessage" ENUM "No","Yes";
BA_DEF_ BO_ "GenMsgSendType" ENUM "Cyclic","NotUsed","NotUsed","NotUsed","NotUsed","NotUsed","NotUsed","NotUsed","NoMsgSendType";
BA_DEF_ BO_ "GenMsgTimeoutTime" INT 0 10000;
BA_DEF_ BO_ "GenMsgNrOfRepetition" INT 0 255;
BA_DEF_ BO_ "GenMsgILSupport" ENUM "No","Yes";
BA_DEF_ BO_ "GenMsgStartDelayTime" INT 0 65535;
BA_DEF_ BO_ "GenMsgCycleTimeFast" INT 0 65535;
BA_DEF_ BO_ "GenMsgCycleTime" INT 0 65535;
BA_DEF_ BO_ "GenMsgDelayTime" INT 0 65535;
BA_DEF_ BO_ "DiagState" ENUM "No","Yes";
BA_DEF_DEF_ "Accuracy" "";
BA_DEF_DEF_ "Event trans." "No";
BA_DEF_DEF_ "GenSigStartValue" 0;
BA_DEF_DEF_ "GenSigInactiveValue" 0;
BA_DEF_DEF_ "GenSigSendType" "NoSigSendType";
BA_DEF_DEF_ "SystemSignalLongSymbol" "";
BA_DEF_DEF_ "DiagRequest" "No";
BA_DEF_DEF_ "Period [ms]" 0;
BA_DEF_DEF_ "Type" "-";
BA_DEF_DEF_ "DiagResponse" "No";
BA_DEF_DEF_ "NmMessage" "No";
BA_DEF_DEF_ "GenMsgSendType" "NoMsgSendType";
BA_DEF_DEF_ "GenMsgTimeoutTime" 0;
BA_DEF_DEF_ "GenMsgNrOfRepetition" 0;
BA_DEF_DEF_ "GenMsgILSupport" "No";
BA_DEF_DEF_ "GenMsgStartDelayTime" 0;
BA_DEF_DEF_ "GenMsgCycleTimeFast" 0;
BA_DEF_DEF_ "GenMsgCycleTime" 0;
BA_DEF_DEF_ "GenMsgDelayTime" 0;
BA_DEF_DEF_ "DiagState" "No";
BA_ "Period [ms]" BO_ 1283 1000;
BA_ "Type" BO_ 1283 3;
BA_ "GenMsgSendType" BO_ 1283 0;
BA_ "GenMsgTimeoutTime" BO_ 1283 2500;
BA_ "GenMsgILSupport" BO_ 1283 1;
BA_ "GenMsgStartDelayTime" BO_ 1283 50;
BA_ "GenMsgCycleTime" BO_ 1283 1000;
BA_ "GenMsgDelayTime" BO_ 1283 20;
BA_ "Period [ms]" BO_ 1284 1000;
BA_ "Type" BO_ 1284 3;
BA_ "GenMsgSendType" BO_ 1284 0;
BA_ "GenMsgTimeoutTime" BO_ 1284 2500;
BA_ "GenMsgILSupport" BO_ 1284 1;
BA_ "GenMsgStartDelayTime" BO_ 1284 150;
BA_ "GenMsgCycleTime" BO_ 1284 1000;
BA_ "GenMsgDelayTime" BO_ 1284 20;
BA_ "Period [ms]" BO_ 1289 1000;
BA_ "Type" BO_ 1289 3;
BA_ "GenMsgSendType" BO_ 1289 0;
BA_ "GenMsgTimeoutTime" BO_ 1289 2500;
BA_ "GenMsgILSupport" BO_ 1289 1;
BA_ "GenMsgCycleTime" BO_ 1289 1000;
BA_ "GenMsgDelayTime" BO_ 1289 20;
BA_ "Period [ms]" BO_ 1452 1000;
BA_ "Type" BO_ 1452 3;
BA_ "GenMsgSendType" BO_ 1452 0;
BA_ "GenMsgTimeoutTime" BO_ 1452 2500;
BA_ "GenMsgILSupport" BO_ 1452 1;
BA_ "GenMsgCycleTime" BO_ 1452 1000;
BA_ "GenMsgDelayTime" BO_ 1452 20;
BA_ "Type" BO_ 948 11;
BA_ "GenMsgILSupport" BO_ 948 1;
BA_ "GenMsgDelayTime" BO_ 948 50;
BA_ "Type" BO_ 173 7;
BA_ "GenMsgILSupport" BO_ 173 1;
BA_ "GenMsgDelayTime" BO_ 173 100;
BA_ "Type" BO_ 1454 8;
BA_ "GenMsgILSupport" BO_ 1454 1;
BA_ "GenMsgDelayTime" BO_ 1454 250;
BA_ "Period [ms]" BO_ 1446 1000;
BA_ "Type" BO_ 1446 3;
BA_ "GenMsgSendType" BO_ 1446 0;
BA_ "GenMsgILSupport" BO_ 1446 1;
BA_ "GenMsgCycleTime" BO_ 1446 1000;
BA_ "GenMsgDelayTime" BO_ 1446 20;
BA_ "Period [ms]" BO_ 1890 1000;
BA_ "Type" BO_ 1890 1;
BA_ "GenMsgSendType" BO_ 1890 0;
BA_ "GenMsgILSupport" BO_ 1890 1;
BA_ "GenMsgStartDelayTime" BO_ 1890 650;
BA_ "GenMsgCycleTime" BO_ 1890 1000;
BA_ "Period [ms]" BO_ 2000 1500;
BA_ "Type" BO_ 2000 3;
BA_ "GenMsgSendType" BO_ 2000 0;
BA_ "GenMsgTimeoutTime" BO_ 2000 2500;
BA_ "GenMsgILSupport" BO_ 2000 1;
BA_ "GenMsgCycleTime" BO_ 2000 1500;
BA_ "GenMsgDelayTime" BO_ 2000 20;
BA_ "Period [ms]" BO_ 854 250;
BA_ "Type" BO_ 854 3;
BA_ "GenMsgSendType" BO_ 854 0;
BA_ "GenMsgILSupport" BO_ 854 1;
BA_ "GenMsgStartDelayTime" BO_ 854 190;
BA_ "GenMsgCycleTime" BO_ 854 250;
BA_ "GenMsgDelayTime" BO_ 854 20;
BA_ "Period [ms]" BO_ 1132 500;
BA_ "Type" BO_ 1132 3;
BA_ "GenMsgSendType" BO_ 1132 0;
BA_ "GenMsgILSupport" BO_ 1132 1;
BA_ "GenMsgStartDelayTime" BO_ 1132 250;
BA_ "GenMsgCycleTime" BO_ 1132 500;
BA_ "GenMsgDelayTime" BO_ 1132 20;
BA_ "Period [ms]" BO_ 1450 1000;
BA_ "Type" BO_ 1450 3;
BA_ "GenMsgSendType" BO_ 1450 0;
BA_ "GenMsgTimeoutTime" BO_ 1450 2500;
BA_ "GenMsgILSupport" BO_ 1450 1;
BA_ "GenMsgStartDelayTime" BO_ 1450 100;
BA_ "GenMsgCycleTime" BO_ 1450 1000;
BA_ "Period [ms]" BO_ 1128 500;
BA_ "Type" BO_ 1128 3;
BA_ "GenMsgSendType" BO_ 1128 0;
BA_ "GenMsgILSupport" BO_ 1128 1;
BA_ "GenMsgCycleTime" BO_ 1128 500;
BA_ "GenMsgDelayTime" BO_ 1128 20;
BA_ "Period [ms]" BO_ 988 100;
BA_ "Type" BO_ 988 1;
BA_ "GenMsgSendType" BO_ 988 0;
BA_ "GenMsgTimeoutTime" BO_ 988 2500;
BA_ "GenMsgILSupport" BO_ 988 1;
BA_ "GenMsgCycleTime" BO_ 988 100;
BA_ "Period [ms]" BO_ 990 100;
BA_ "Type" BO_ 990 1;
BA_ "GenMsgSendType" BO_ 990 0;
BA_ "GenMsgILSupport" BO_ 990 1;
BA_ "GenMsgStartDelayTime" BO_ 990 25;
BA_ "GenMsgCycleTime" BO_ 990 100;
BA_ "Period [ms]" BO_ 994 100;
BA_ "Type" BO_ 994 1;
BA_ "GenMsgSendType" BO_ 994 0;
BA_ "GenMsgTimeoutTime" BO_ 994 2500;
BA_ "GenMsgILSupport" BO_ 994 1;
BA_ "GenMsgStartDelayTime" BO_ 994 60;
BA_ "GenMsgCycleTime" BO_ 994 100;
BA_ "Period [ms]" BO_ 996 100;
BA_ "Type" BO_ 996 1;
BA_ "GenMsgSendType" BO_ 996 0;
BA_ "GenMsgILSupport" BO_ 996 1;
BA_ "GenMsgStartDelayTime" BO_ 996 75;
BA_ "GenMsgCycleTime" BO_ 996 100;
BA_ "Period [ms]" BO_ 998 100;
BA_ "Type" BO_ 998 1;
BA_ "GenMsgSendType" BO_ 998 0;
BA_ "GenMsgILSupport" BO_ 998 1;
BA_ "GenMsgStartDelayTime" BO_ 998 90;
BA_ "GenMsgCycleTime" BO_ 998 100;
BA_ "Period [ms]" BO_ 1984 2000;
BA_ "Type" BO_ 1984 1;
BA_ "GenMsgSendType" BO_ 1984 0;
BA_ "GenMsgILSupport" BO_ 1984 1;
BA_ "GenMsgStartDelayTime" BO_ 1984 1000;
BA_ "GenMsgCycleTime" BO_ 1984 2000;
BA_ "Period [ms]" BO_ 1426 1000;
BA_ "Type" BO_ 1426 3;
BA_ "GenMsgSendType" BO_ 1426 0;
BA_ "GenMsgTimeoutTime" BO_ 1426 2500;
BA_ "GenMsgILSupport" BO_ 1426 1;
BA_ "GenMsgStartDelayTime" BO_ 1426 50;
BA_ "GenMsgCycleTime" BO_ 1426 1000;
BA_ "GenMsgDelayTime" BO_ 1426 20;
BA_ "Period [ms]" BO_ 1460 1000;
BA_ "Type" BO_ 1460 3;
BA_ "GenMsgSendType" BO_ 1460 0;
BA_ "GenMsgTimeoutTime" BO_ 1460 2500;
BA_ "GenMsgILSupport" BO_ 1460 1;
BA_ "GenMsgCycleTime" BO_ 1460 1000;
BA_ "GenMsgDelayTime" BO_ 1460 50;
BA_ "Period [ms]" BO_ 1130 500;
BA_ "Type" BO_ 1130 3;
BA_ "GenMsgSendType" BO_ 1130 0;
BA_ "GenMsgILSupport" BO_ 1130 1;
BA_ "GenMsgCycleTime" BO_ 1130 500;
BA_ "GenMsgDelayTime" BO_ 1130 20;
BA_ "Period [ms]" BO_ 1482 1000;
BA_ "Type" BO_ 1482 3;
BA_ "GenMsgSendType" BO_ 1482 0;
BA_ "GenMsgILSupport" BO_ 1482 1;
BA_ "GenMsgCycleTime" BO_ 1482 1000;
BA_ "GenMsgDelayTime" BO_ 1482 100;
BA_ "Period [ms]" BO_ 1483 1000;
BA_ "Type" BO_ 1483 3;
BA_ "GenMsgSendType" BO_ 1483 0;
BA_ "GenMsgTimeoutTime" BO_ 1483 2500;
BA_ "GenMsgILSupport" BO_ 1483 1;
BA_ "GenMsgCycleTime" BO_ 1483 1000;
BA_ "GenMsgDelayTime" BO_ 1483 100;
BA_ "Period [ms]" BO_ 1904 1000;
BA_ "Type" BO_ 1904 1;
BA_ "GenMsgSendType" BO_ 1904 0;
BA_ "GenMsgILSupport" BO_ 1904 1;
BA_ "GenMsgCycleTime" BO_ 1904 1000;
BA_ "GenMsgDelayTime" BO_ 1904 20;
BA_ "Period [ms]" BO_ 1448 1000;
BA_ "Type" BO_ 1448 3;
BA_ "GenMsgSendType" BO_ 1448 0;
BA_ "GenMsgTimeoutTime" BO_ 1448 2500;
BA_ "GenMsgILSupport" BO_ 1448 1;
BA_ "GenMsgCycleTime" BO_ 1448 1000;
BA_ "GenMsgDelayTime" BO_ 1448 100;
BA_ "Period [ms]" BO_ 1169 500;
BA_ "Type" BO_ 1169 3;
BA_ "GenMsgSendType" BO_ 1169 0;
BA_ "GenMsgTimeoutTime" BO_ 1169 2500;
BA_ "GenMsgILSupport" BO_ 1169 1;
BA_ "GenMsgCycleTime" BO_ 1169 500;
BA_ "GenMsgDelayTime" BO_ 1169 20;
BA_ "Period [ms]" BO_ 1899 1000;
BA_ "Type" BO_ 1899 1;
BA_ "GenMsgSendType" BO_ 1899 0;
BA_ "GenMsgILSupport" BO_ 1899 1;
BA_ "GenMsgStartDelayTime" BO_ 1899 400;
BA_ "GenMsgCycleTime" BO_ 1899 1000;
BA_ "GenMsgDelayTime" BO_ 1899 20;
BA_ "Period [ms]" BO_ 1512 1000;
BA_ "Type" BO_ 1512 3;
BA_ "GenMsgSendType" BO_ 1512 0;
BA_ "GenMsgILSupport" BO_ 1512 1;
BA_ "GenMsgStartDelayTime" BO_ 1512 400;
BA_ "GenMsgCycleTime" BO_ 1512 1000;
BA_ "GenMsgDelayTime" BO_ 1512 20;
BA_ "Period [ms]" BO_ 1462 1000;
BA_ "Type" BO_ 1462 3;
BA_ "GenMsgSendType" BO_ 1462 0;
BA_ "GenMsgILSupport" BO_ 1462 1;
BA_ "GenMsgStartDelayTime" BO_ 1462 250;
BA_ "GenMsgCycleTime" BO_ 1462 1000;
BA_ "GenMsgDelayTime" BO_ 1462 20;
BA_ "Type" BO_ 1268 11;
BA_ "GenMsgILSupport" BO_ 1268 1;
BA_ "GenMsgDelayTime" BO_ 1268 50;
BA_ "Period [ms]" BO_ 1458 1000;
BA_ "Type" BO_ 1458 3;
BA_ "GenMsgSendType" BO_ 1458 0;
BA_ "GenMsgTimeoutTime" BO_ 1458 2500;
BA_ "GenMsgILSupport" BO_ 1458 1;
BA_ "GenMsgCycleTime" BO_ 1458 1000;
BA_ "GenMsgDelayTime" BO_ 1458 20;
BA_ "Period [ms]" BO_ 1470 1000;
BA_ "Type" BO_ 1470 3;
BA_ "GenMsgSendType" BO_ 1470 0;
BA_ "GenMsgILSupport" BO_ 1470 1;
BA_ "GenMsgStartDelayTime" BO_ 1470 250;
BA_ "GenMsgCycleTime" BO_ 1470 1000;
BA_ "GenMsgDelayTime" BO_ 1470 50;
BA_ "Period [ms]" BO_ 1206 500;
BA_ "Type" BO_ 1206 3;
BA_ "GenMsgSendType" BO_ 1206 0;
BA_ "GenMsgILSupport" BO_ 1206 1;
BA_ "GenMsgCycleTime" BO_ 1206 500;
BA_ "GenMsgDelayTime" BO_ 1206 20;
BA_ "Type" BO_ 750 7;
BA_ "GenMsgTimeoutTime" BO_ 750 2500;
BA_ "GenMsgILSupport" BO_ 750 1;
BA_ "GenMsgDelayTime" BO_ 750 20;
BA_ "Type" BO_ 178 8;
BA_ "GenMsgTimeoutTime" BO_ 178 2500;
BA_ "GenMsgNrOfRepetition" BO_ 178 10;
BA_ "GenMsgILSupport" BO_ 178 1;
BA_ "GenMsgCycleTimeFast" BO_ 178 500;
BA_ "GenMsgDelayTime" BO_ 178 20;
BA_ "Type" BO_ 172 8;
BA_ "GenMsgNrOfRepetition" BO_ 172 10;
BA_ "GenMsgILSupport" BO_ 172 1;
BA_ "GenMsgCycleTimeFast" BO_ 172 500;
BA_ "GenMsgDelayTime" BO_ 172 50;
BA_ "Type" BO_ 174 8;
BA_ "GenMsgNrOfRepetition" BO_ 174 10;
BA_ "GenMsgILSupport" BO_ 174 1;
BA_ "GenMsgCycleTimeFast" BO_ 174 500;
BA_ "GenMsgDelayTime" BO_ 174 50;
BA_ "Type" BO_ 176 8;
BA_ "GenMsgNrOfRepetition" BO_ 176 10;
BA_ "GenMsgILSupport" BO_ 176 1;
BA_ "GenMsgCycleTimeFast" BO_ 176 500;
BA_ "GenMsgDelayTime" BO_ 176 50;
BA_ "Period [ms]" BO_ 1480 1000;
BA_ "Type" BO_ 1480 3;
BA_ "GenMsgSendType" BO_ 1480 0;
BA_ "GenMsgILSupport" BO_ 1480 1;
BA_ "GenMsgStartDelayTime" BO_ 1480 400;
BA_ "GenMsgCycleTime" BO_ 1480 1000;
BA_ "GenMsgDelayTime" BO_ 1480 100;
BA_ "Period [ms]" BO_ 1052 1000;
BA_ "Type" BO_ 1052 10;
BA_ "GenMsgSendType" BO_ 1052 0;
BA_ "GenMsgILSupport" BO_ 1052 1;
BA_ "GenMsgCycleTimeFast" BO_ 1052 100;
BA_ "GenMsgCycleTime" BO_ 1052 1000;
BA_ "GenMsgDelayTime" BO_ 1052 100;
BA_ "Type" BO_ 144 12;
BA_ "GenMsgILSupport" BO_ 144 1;
BA_ "GenMsgDelayTime" BO_ 144 20;
BA_ "Period [ms]" BO_ 1502 1000;
BA_ "Type" BO_ 1502 3;
BA_ "GenMsgSendType" BO_ 1502 0;
BA_ "GenMsgTimeoutTime" BO_ 1502 2500;
BA_ "GenMsgILSupport" BO_ 1502 1;
BA_ "GenMsgStartDelayTime" BO_ 1502 400;
BA_ "GenMsgCycleTime" BO_ 1502 1000;
BA_ "GenMsgDelayTime" BO_ 1502 20;
BA_ "Period [ms]" BO_ 1500 1000;
BA_ "Type" BO_ 1500 3;
BA_ "GenMsgSendType" BO_ 1500 0;
BA_ "GenMsgTimeoutTime" BO_ 1500 2500;
BA_ "GenMsgILSupport" BO_ 1500 1;
BA_ "GenMsgStartDelayTime" BO_ 1500 400;
BA_ "GenMsgCycleTime" BO_ 1500 1000;
BA_ "GenMsgDelayTime" BO_ 1500 20;
BA_ "Type" BO_ 126 7;
BA_ "GenMsgILSupport" BO_ 126 1;
BA_ "GenMsgDelayTime" BO_ 126 100;
BA_ "Type" BO_ 136 7;
BA_ "GenMsgILSupport" BO_ 136 1;
BA_ "GenMsgDelayTime" BO_ 136 20;
BA_ "Type" BO_ 124 7;
BA_ "GenMsgILSupport" BO_ 124 1;
BA_ "GenMsgDelayTime" BO_ 124 100;
BA_ "Type" BO_ 170 8;
BA_ "GenMsgILSupport" BO_ 170 1;
BA_ "GenMsgDelayTime" BO_ 170 20;
BA_ "Type" BO_ 156 8;
BA_ "GenMsgILSupport" BO_ 156 1;
BA_ "GenMsgDelayTime" BO_ 156 20;
BA_ "Type" BO_ 158 8;
BA_ "GenMsgILSupport" BO_ 158 1;
BA_ "GenMsgDelayTime" BO_ 158 100;
BA_ "Type" BO_ 162 8;
BA_ "GenMsgILSupport" BO_ 162 1;
BA_ "GenMsgDelayTime" BO_ 162 100;
BA_ "Type" BO_ 1291 8;
BA_ "GenMsgILSupport" BO_ 1291 1;
BA_ "GenMsgDelayTime" BO_ 1291 100;
BA_ "Type" BO_ 163 8;
BA_ "GenMsgILSupport" BO_ 163 1;
BA_ "GenMsgDelayTime" BO_ 163 100;
BA_ "Type" BO_ 192 8;
BA_ "GenMsgILSupport" BO_ 192 1;
BA_ "GenMsgDelayTime" BO_ 192 50;
BA_ "Period [ms]" BO_ 1892 1000;
BA_ "Type" BO_ 1892 1;
BA_ "GenMsgSendType" BO_ 1892 0;
BA_ "GenMsgILSupport" BO_ 1892 1;
BA_ "GenMsgStartDelayTime" BO_ 1892 750;
BA_ "GenMsgCycleTime" BO_ 1892 1000;
BA_ "Period [ms]" BO_ 1472 1000;
BA_ "Type" BO_ 1472 3;
BA_ "GenMsgSendType" BO_ 1472 0;
BA_ "GenMsgILSupport" BO_ 1472 1;
BA_ "GenMsgStartDelayTime" BO_ 1472 220;
BA_ "GenMsgCycleTime" BO_ 1472 1000;
BA_ "GenMsgDelayTime" BO_ 1472 20;
BA_ "Period [ms]" BO_ 1888 1000;
BA_ "Type" BO_ 1888 1;
BA_ "GenMsgSendType" BO_ 1888 0;
BA_ "GenMsgILSupport" BO_ 1888 1;
BA_ "GenMsgStartDelayTime" BO_ 1888 500;
BA_ "GenMsgCycleTime" BO_ 1888 1000;
BA_ "Period [ms]" BO_ 1476 1000;
BA_ "Type" BO_ 1476 3;
BA_ "GenMsgSendType" BO_ 1476 0;
BA_ "GenMsgILSupport" BO_ 1476 1;
BA_ "GenMsgStartDelayTime" BO_ 1476 360;
BA_ "GenMsgCycleTime" BO_ 1476 1000;
BA_ "GenMsgDelayTime" BO_ 1476 20;
BA_ "Period [ms]" BO_ 1444 1000;
BA_ "Type" BO_ 1444 3;
BA_ "GenMsgSendType" BO_ 1444 0;
BA_ "GenMsgILSupport" BO_ 1444 1;
BA_ "GenMsgStartDelayTime" BO_ 1444 60;
BA_ "GenMsgCycleTime" BO_ 1444 1000;
BA_ "GenMsgDelayTime" BO_ 1444 20;
BA_ "Type" BO_ 748 9;
BA_ "GenMsgTimeoutTime" BO_ 748 2500;
BA_ "GenMsgNrOfRepetition" BO_ 748 2;
BA_ "GenMsgILSupport" BO_ 748 1;
BA_ "GenMsgCycleTimeFast" BO_ 748 100;
BA_ "GenMsgDelayTime" BO_ 748 20;
BA_ "Type" BO_ 1976 8;
BA_ "GenMsgTimeoutTime" BO_ 1976 2500;
BA_ "GenMsgILSupport" BO_ 1976 1;
BA_ "GenMsgDelayTime" BO_ 1976 20;
BA_ "Period [ms]" BO_ 992 100;
BA_ "Type" BO_ 992 1;
BA_ "GenMsgSendType" BO_ 992 0;
BA_ "GenMsgILSupport" BO_ 992 1;
BA_ "GenMsgStartDelayTime" BO_ 992 40;
BA_ "GenMsgCycleTime" BO_ 992 100;
BA_ "Type" BO_ 132 12;
BA_ "GenMsgILSupport" BO_ 132 1;
BA_ "GenMsgDelayTime" BO_ 132 20;
BA_ "Type" BO_ 130 12;
BA_ "GenMsgILSupport" BO_ 130 1;
BA_ "GenMsgDelayTime" BO_ 130 20;
BA_ "Event trans." SG_ 1283 ManDispCtrl 0;
BA_ "GenSigSendType" SG_ 1283 ManDispCtrl 3;
BA_ "Event trans." SG_ 1283 RQ_DISP_INTS 0;
BA_ "GenSigStartValue" SG_ 1283 RQ_DISP_INTS 255;
BA_ "GenSigSendType" SG_ 1283 RQ_DISP_INTS 3;
BA_ "Event trans." SG_ 1284 Radio_Theme 0;
BA_ "GenSigSendType" SG_ 1284 Radio_Theme 3;
BA_ "Event trans." SG_ 1289 ChargeNow 0;
BA_ "GenSigSendType" SG_ 1289 ChargeNow 3;
BA_ "Event trans." SG_ 948 SDW_ChimeActivation_LHF 0;
BA_ "GenSigSendType" SG_ 948 SDW_ChimeActivation_LHF 1;
BA_ "Event trans." SG_ 948 SDW_ChimeActivation_LHR 0;
BA_ "GenSigSendType" SG_ 948 SDW_ChimeActivation_LHR 1;
BA_ "Event trans." SG_ 948 SDW_ChimeActivation_RHF 0;
BA_ "GenSigSendType" SG_ 948 SDW_ChimeActivation_RHF 1;
BA_ "Event trans." SG_ 948 SDW_ChimeActivation_RHR 0;
BA_ "GenSigSendType" SG_ 948 SDW_ChimeActivation_RHR 1;
BA_ "Event trans." SG_ 948 SDW_ChimeRepetitionRate_Left 0;
BA_ "GenSigSendType" SG_ 948 SDW_ChimeRepetitionRate_Left 1;
BA_ "Event trans." SG_ 948 SDW_ChimeRepetitionRate_Right 0;
BA_ "GenSigSendType" SG_ 948 SDW_ChimeRepetitionRate_Right 1;
BA_ "Event trans." SG_ 948 SDW_ChimeType_Left 0;
BA_ "GenSigSendType" SG_ 948 SDW_ChimeType_Left 1;
BA_ "Event trans." SG_ 948 SDW_ChimeType_Right 0;
BA_ "GenSigSendType" SG_ 948 SDW_ChimeType_Right 1;
BA_ "Event trans." SG_ 948 SDW_DisplayActivation 0;
BA_ "GenSigSendType" SG_ 948 SDW_DisplayActivation 1;
BA_ "Event trans." SG_ 948 SDW_ObstacleInTrajectory_LLF 0;
BA_ "GenSigSendType" SG_ 948 SDW_ObstacleInTrajectory_LLF 1;
BA_ "Event trans." SG_ 948 SDW_ObstacleInTrajectory_LLR 0;
BA_ "GenSigSendType" SG_ 948 SDW_ObstacleInTrajectory_LLR 1;
BA_ "Event trans." SG_ 948 SDW_ObstacleInTrajectory_LRF 0;
BA_ "GenSigSendType" SG_ 948 SDW_ObstacleInTrajectory_LRF 1;
BA_ "Event trans." SG_ 948 SDW_ObstacleInTrajectory_LRR 0;
BA_ "GenSigSendType" SG_ 948 SDW_ObstacleInTrajectory_LRR 1;
BA_ "Event trans." SG_ 948 SDW_Warning_Left_1 0;
BA_ "GenSigSendType" SG_ 948 SDW_Warning_Left_1 1;
BA_ "Event trans." SG_ 948 SDW_Warning_Left_2 0;
BA_ "GenSigSendType" SG_ 948 SDW_Warning_Left_2 1;
BA_ "Event trans." SG_ 948 SDW_Warning_Right_1 0;
BA_ "GenSigSendType" SG_ 948 SDW_Warning_Right_1 1;
BA_ "Event trans." SG_ 948 SDW_Warning_Right_2 0;
BA_ "GenSigSendType" SG_ 948 SDW_Warning_Right_2 1;
BA_ "Accuracy" SG_ 173 ADAS_Seg_BuildUpArea "-";
BA_ "Event trans." SG_ 173 ADAS_Seg_BuildUpArea 0;
BA_ "GenSigSendType" SG_ 173 ADAS_Seg_BuildUpArea 3;
BA_ "Accuracy" SG_ 173 ADAS_Seg_DividedRoad "-";
BA_ "Event trans." SG_ 173 ADAS_Seg_DividedRoad 0;
BA_ "GenSigSendType" SG_ 173 ADAS_Seg_DividedRoad 3;
BA_ "Event trans." SG_ 173 ADAS_Seg_EffSpdLmt 0;
BA_ "GenSigSendType" SG_ 173 ADAS_Seg_EffSpdLmt 3;
BA_ "Accuracy" SG_ 173 ADAS_Seg_EffSpdLmtType "-";
BA_ "Event trans." SG_ 173 ADAS_Seg_EffSpdLmtType 0;
BA_ "GenSigSendType" SG_ 173 ADAS_Seg_EffSpdLmtType 3;
BA_ "Event trans." SG_ 173 ADAS_Seg_FormOfWay 0;
BA_ "GenSigSendType" SG_ 173 ADAS_Seg_FormOfWay 3;
BA_ "Accuracy" SG_ 173 ADAS_Seg_FuncRoadClass "-";
BA_ "Event trans." SG_ 173 ADAS_Seg_FuncRoadClass 0;
BA_ "GenSigSendType" SG_ 173 ADAS_Seg_FuncRoadClass 3;
BA_ "Event trans." SG_ 173 ADAS_Seg_NumOfLaneDrvDir 0;
BA_ "GenSigSendType" SG_ 173 ADAS_Seg_NumOfLaneDrvDir 3;
BA_ "Accuracy" SG_ 173 ADAS_Seg_PathIdx "-";
BA_ "Event trans." SG_ 173 ADAS_Seg_PathIdx 0;
BA_ "GenSigSendType" SG_ 173 ADAS_Seg_PathIdx 3;
BA_ "Event trans." SG_ 1454 CallAction 0;
BA_ "GenSigSendType" SG_ 1454 CallAction 1;
BA_ "Event trans." SG_ 1454 CallRequest 0;
BA_ "GenSigSendType" SG_ 1454 CallRequest 1;
BA_ "Event trans." SG_ 1454 TBMUpdateAction 0;
BA_ "GenSigSendType" SG_ 1454 TBMUpdateAction 1;
BA_ "Event trans." SG_ 1454 WiFiReq 0;
BA_ "GenSigSendType" SG_ 1454 WiFiReq 1;
BA_ "Accuracy" SG_ 1446 ClearPersonalData "-";
BA_ "Event trans." SG_ 1446 ClearPersonalData 0;
BA_ "GenSigSendType" SG_ 1446 ClearPersonalData 3;
BA_ "Accuracy" SG_ 1446 PrivacyMode "-";
BA_ "Event trans." SG_ 1446 PrivacyMode 0;
BA_ "GenSigSendType" SG_ 1446 PrivacyMode 3;
BA_ "Accuracy" SG_ 1446 RestoreApp "-";
BA_ "Event trans." SG_ 1446 RestoreApp 0;
BA_ "GenSigSendType" SG_ 1446 RestoreApp 3;
BA_ "Accuracy" SG_ 1446 RestoreDefaultSetting "-";
BA_ "Event trans." SG_ 1446 RestoreDefaultSetting 0;
BA_ "GenSigSendType" SG_ 1446 RestoreDefaultSetting 3;
BA_ "Accuracy" SG_ 1446 TelematicSetupAck "-";
BA_ "Event trans." SG_ 1446 TelematicSetupAck 0;
BA_ "GenSigSendType" SG_ 1446 TelematicSetupAck 3;
BA_ "Accuracy" SG_ 1890 DaysToService "-";
BA_ "Accuracy" SG_ 1890 DistanceToService "-";
BA_ "Event trans." SG_ 2000 AMP_DSS_STATSts 0;
BA_ "GenSigSendType" SG_ 2000 AMP_DSS_STATSts 3;
BA_ "Event trans." SG_ 2000 AMP_MUTEDSts 0;
BA_ "GenSigSendType" SG_ 2000 AMP_MUTEDSts 3;
BA_ "Event trans." SG_ 2000 AUDIOSts_AMP 0;
BA_ "GenSigSendType" SG_ 2000 AUDIOSts_AMP 3;
BA_ "Event trans." SG_ 2000 PowerModeSts_AMP 0;
BA_ "GenSigSendType" SG_ 2000 PowerModeSts_AMP 3;
BA_ "Event trans." SG_ 2000 SURR_AVAILSts 0;
BA_ "GenSigSendType" SG_ 2000 SURR_AVAILSts 3;
BA_ "Accuracy" SG_ 854 BonnetSts "-";
BA_ "Event trans." SG_ 854 BonnetSts 0;
BA_ "GenSigSendType" SG_ 854 BonnetSts 3;
BA_ "Accuracy" SG_ 854 BrakeFluidLevelSts "-";
BA_ "Accuracy" SG_ 854 IMMOCodeWarningLightSts "-";
BA_ "Event trans." SG_ 854 IMMOCodeWarningLightSts 0;
BA_ "GenSigSendType" SG_ 854 IMMOCodeWarningLightSts 3;
BA_ "Accuracy" SG_ 854 LHRDoorSts "-";
BA_ "Event trans." SG_ 854 LHRDoorSts 0;
BA_ "GenSigSendType" SG_ 854 LHRDoorSts 3;
BA_ "Event trans." SG_ 854 NightAndDaySensorFailSts 0;
BA_ "GenSigSendType" SG_ 854 NightAndDaySensorFailSts 3;
BA_ "Accuracy" SG_ 854 ParkBrakeSts "-";
BA_ "Event trans." SG_ 854 ParkBrakeSts 0;
BA_ "GenSigSendType" SG_ 854 ParkBrakeSts 3;
BA_ "Accuracy" SG_ 854 RainSensorFailSts "-";
BA_ "Accuracy" SG_ 854 RearTrunkEnableLastElSts "-";
BA_ "Accuracy" SG_ 854 RHatchSts "-";
BA_ "Event trans." SG_ 854 RHatchSts 0;
BA_ "GenSigSendType" SG_ 854 RHatchSts 3;
BA_ "Accuracy" SG_ 854 RHRDoorSts "-";
BA_ "Event trans." SG_ 854 RHRDoorSts 0;
BA_ "GenSigSendType" SG_ 854 RHRDoorSts 3;
BA_ "Accuracy" SG_ 854 SysEOLSts "-";
BA_ "Accuracy" SG_ 854 WarningKeyInSts "-";
BA_ "Accuracy" SG_ 1132 BatteryChargeSts "5";
BA_ "Accuracy" SG_ 1132 BatteryVoltageLevel "0,05";
BA_ "Event trans." SG_ 1132 CmdIgn_FailSts 0;
BA_ "GenSigSendType" SG_ 1132 CmdIgn_FailSts 3;
BA_ "Event trans." SG_ 1132 CmdIgnSts 0;
BA_ "GenSigSendType" SG_ 1132 CmdIgnSts 3;
BA_ "Event trans." SG_ 1132 DriveStyleSts 0;
BA_ "GenSigSendType" SG_ 1132 DriveStyleSts 3;
BA_ "GenSigStartValue" SG_ 1132 ExternalTemperatureC 511;
BA_ "GenSigStartValue" SG_ 1132 ExternalTemperatureF 511;
BA_ "Accuracy" SG_ 1132 ExternalTemperatureFailSts "-";
BA_ "Event trans." SG_ 1132 Int_Relay_FailSts 0;
BA_ "GenSigSendType" SG_ 1132 Int_Relay_FailSts 3;
BA_ "Event trans." SG_ 1132 InternalLightSts 0;
BA_ "GenSigSendType" SG_ 1132 InternalLightSts 3;
BA_ "Event trans." SG_ 1132 RemStActvSts 0;
BA_ "GenSigSendType" SG_ 1132 RemStActvSts 3;
BA_ "Event trans." SG_ 1132 TurnIndicationSts 0;
BA_ "GenSigSendType" SG_ 1132 TurnIndicationSts 3;
BA_ "Event trans." SG_ 1450 PreCondActvSts 0;
BA_ "GenSigSendType" SG_ 1450 PreCondActvSts 3;
BA_ "Event trans." SG_ 1450 RecoveryIgnOffInd 0;
BA_ "GenSigSendType" SG_ 1450 RecoveryIgnOffInd 3;
BA_ "GenSigStartValue" SG_ 1128 InternalLightLevel2 5;
BA_ "Accuracy" SG_ 988 LatAcceleration_BSM "-";
BA_ "Accuracy" SG_ 988 LatAccelerationFailSts_BSM "-";
BA_ "Accuracy" SG_ 988 LongAcceleration_BSM "-";
BA_ "Accuracy" SG_ 988 LongAccelerationFailSts_BSM "-";
BA_ "Accuracy" SG_ 988 YawRate_BSM "-";
BA_ "Accuracy" SG_ 988 YawRateFailSts_BSM "-";
BA_ "Accuracy" SG_ 990 LHF_FastPulseCounter "-";
BA_ "Accuracy" SG_ 990 LHF_WheelSensorFailSts "-";
BA_ "Accuracy" SG_ 990 LHR_FastPulseCounter "-";
BA_ "Accuracy" SG_ 990 LHR_WheelSensorFailSts "-";
BA_ "Accuracy" SG_ 990 RHF_FastPulseCounter "-";
BA_ "Accuracy" SG_ 990 RHF_WheelSensorFailSts "-";
BA_ "Accuracy" SG_ 990 RHR_FastPulseCounter "-";
BA_ "Accuracy" SG_ 990 RHR_WheelSensorFailSts "-";
BA_ "Accuracy" SG_ 1984 InflationState_LHF_Tyre "-";
BA_ "Accuracy" SG_ 1984 InflationState_LHR_Tyre "-";
BA_ "Accuracy" SG_ 1984 InflationState_RHF_Tyre "-";
BA_ "Accuracy" SG_ 1984 InflationState_RHR_Tyre "-";
BA_ "Accuracy" SG_ 1984 TyrePressureSystemFailSts "-";
BA_ "Event trans." SG_ 1426 AEB_CHIME_TYPSts 0;
BA_ "GenSigSendType" SG_ 1426 AEB_CHIME_TYPSts 3;
BA_ "Event trans." SG_ 1426 AEB_LF_CHIME_RQSts 0;
BA_ "GenSigSendType" SG_ 1426 AEB_LF_CHIME_RQSts 3;
BA_ "Event trans." SG_ 1426 AEB_RF_CHIME_RQSts 0;
BA_ "GenSigSendType" SG_ 1426 AEB_RF_CHIME_RQSts 3;
BA_ "Accuracy" SG_ 1426 DDAActivationFeedback "-";
BA_ "Event trans." SG_ 1426 DDAActivationFeedback 0;
BA_ "GenSigSendType" SG_ 1426 DDAActivationFeedback 3;
BA_ "Accuracy" SG_ 1426 DDAFailSts "-";
BA_ "Event trans." SG_ 1426 DDAFailSts 0;
BA_ "GenSigSendType" SG_ 1426 DDAFailSts 3;
BA_ "Accuracy" SG_ 1426 WarningLevel "-";
BA_ "Event trans." SG_ 1426 WarningLevel 0;
BA_ "GenSigSendType" SG_ 1426 WarningLevel 3;
BA_ "Accuracy" SG_ 1130 CompressorACReqSts "-";
BA_ "Event trans." SG_ 1130 CompressorACReqSts 0;
BA_ "GenSigSendType" SG_ 1130 CompressorACReqSts 3;
BA_ "Accuracy" SG_ 1130 FHeatedWindowCmd "-";
BA_ "Event trans." SG_ 1130 FHeatedWindowCmd 0;
BA_ "GenSigSendType" SG_ 1130 FHeatedWindowCmd 3;
BA_ "Accuracy" SG_ 1130 MaxDefrostSts "-";
BA_ "Event trans." SG_ 1130 MaxDefrostSts 0;
BA_ "GenSigSendType" SG_ 1130 MaxDefrostSts 3;
BA_ "Accuracy" SG_ 1130 PowerModeSts_Climate "-";
BA_ "Event trans." SG_ 1130 PowerModeSts_Climate 0;
BA_ "GenSigSendType" SG_ 1130 PowerModeSts_Climate 3;
BA_ "Accuracy" SG_ 1130 RHeatedWindowCmd "-";
BA_ "Event trans." SG_ 1130 RHeatedWindowCmd 0;
BA_ "GenSigSendType" SG_ 1130 RHeatedWindowCmd 3;
BA_ "Accuracy" SG_ 1130 StopStartClimateInfo "-";
BA_ "Event trans." SG_ 1130 StopStartClimateInfo 0;
BA_ "GenSigSendType" SG_ 1130 StopStartClimateInfo 3;
BA_ "Accuracy" SG_ 1130 StopStartEnable "-";
BA_ "Event trans." SG_ 1130 StopStartEnable 0;
BA_ "GenSigStartValue" SG_ 1130 StopStartEnable 1;
BA_ "GenSigSendType" SG_ 1130 StopStartEnable 3;
BA_ "Event trans." SG_ 1482 HVACAC_Sts 0;
BA_ "GenSigSendType" SG_ 1482 HVACAC_Sts 3;
BA_ "Event trans." SG_ 1482 HVACAuto_Sts 0;
BA_ "GenSigSendType" SG_ 1482 HVACAuto_Sts 3;
BA_ "Event trans." SG_ 1482 HVACBlower_Sts 0;
BA_ "GenSigSendType" SG_ 1482 HVACBlower_Sts 3;
BA_ "Event trans." SG_ 1482 HVACControl_Sts 0;
BA_ "GenSigSendType" SG_ 1482 HVACControl_Sts 3;
BA_ "Event trans." SG_ 1482 HVACMaxAC_Sts 0;
BA_ "GenSigSendType" SG_ 1482 HVACMaxAC_Sts 3;
BA_ "Event trans." SG_ 1482 HVACMode_Sts 0;
BA_ "GenSigSendType" SG_ 1482 HVACMode_Sts 3;
BA_ "Event trans." SG_ 1482 HVACRearDef_Sts 0;
BA_ "GenSigSendType" SG_ 1482 HVACRearDef_Sts 3;
BA_ "Event trans." SG_ 1482 HVACRecirc_Sts 0;
BA_ "GenSigSendType" SG_ 1482 HVACRecirc_Sts 3;
BA_ "Event trans." SG_ 1483 HVACDRVTemp 0;
BA_ "GenSigSendType" SG_ 1483 HVACDRVTemp 3;
BA_ "Accuracy" SG_ 1904 DEFROST_SEL "-";
BA_ "Accuracy" SG_ 1904 DRV_TEMP_DR_POS "-";
BA_ "GenSigStartValue" SG_ 1904 DRV_TEMP_DR_POS 127;
BA_ "Accuracy" SG_ 1904 EvapTempTar "-";
BA_ "Accuracy" SG_ 1904 HtrCorTmp_InTgt "-";
BA_ "GenSigStartValue" SG_ 1904 HtrCorTmp_InTgt 215;
BA_ "Accuracy" SG_ 1904 HVAC_Blwr_Perct "-";
BA_ "GenSigStartValue" SG_ 1904 HVAC_Blwr_Perct 127;
BA_ "Accuracy" SG_ 1904 VEH_INT_TEMP "-";
BA_ "GenSigStartValue" SG_ 1904 VEH_INT_TEMP 65535;
BA_ "Event trans." SG_ 1448 AHP_EnblReq 0;
BA_ "GenSigSendType" SG_ 1448 AHP_EnblReq 3;
BA_ "Event trans." SG_ 1448 AirHtwPwrTgt 0;
BA_ "GenSigSendType" SG_ 1448 AirHtwPwrTgt 3;
BA_ "Event trans." SG_ 1448 EVAP_TEMP_P1C 0;
BA_ "GenSigSendType" SG_ 1448 EVAP_TEMP_P1C 3;
BA_ "Event trans." SG_ 1448 PreCondCabinSts 0;
BA_ "GenSigSendType" SG_ 1448 PreCondCabinSts 3;
BA_ "Event trans." SG_ 1169 FL_HS_STATFailSts 0;
BA_ "GenSigSendType" SG_ 1169 FL_HS_STATFailSts 3;
BA_ "Event trans." SG_ 1169 FL_HS_STATSts 0;
BA_ "GenSigSendType" SG_ 1169 FL_HS_STATSts 3;
BA_ "Event trans." SG_ 1169 FR_HS_STATFailSts 0;
BA_ "GenSigSendType" SG_ 1169 FR_HS_STATFailSts 3;
BA_ "Event trans." SG_ 1169 FR_HS_STATSts 0;
BA_ "GenSigSendType" SG_ 1169 FR_HS_STATSts 3;
BA_ "Accuracy" SG_ 1899 AirHtrPwrCnsAct "-";
BA_ "Accuracy" SG_ 1899 CompStat "-";
BA_ "Accuracy" SG_ 1899 FRfShVlvSts "-";
BA_ "Accuracy" SG_ 1899 HVBatCritCondT "-";
BA_ "Accuracy" SG_ 1899 R134a_PressSts "-";
BA_ "Accuracy" SG_ 1512 AirHtrCoreTemp "-";
BA_ "GenSigStartValue" SG_ 1512 AirHtrCoreTemp 255;
BA_ "Accuracy" SG_ 1512 AirHtrPCBTemp "-";
BA_ "GenSigStartValue" SG_ 1512 AirHtrPCBTemp 255;
BA_ "Accuracy" SG_ 1512 Cabin_Condition_Sts "-";
BA_ "Event trans." SG_ 1512 Cabin_Condition_Sts 0;
BA_ "GenSigSendType" SG_ 1512 Cabin_Condition_Sts 3;
BA_ "Accuracy" SG_ 1512 ChargingLevel "-";
BA_ "Accuracy" SG_ 1512 ChargingSysSts "-";
BA_ "Event trans." SG_ 1512 ChargingSysSts 0;
BA_ "GenSigSendType" SG_ 1512 ChargingSysSts 3;
BA_ "Accuracy" SG_ 1512 ChrgSysFault "-";
BA_ "Accuracy" SG_ 1512 HVBatSOC_HCP "-";
BA_ "Accuracy" SG_ 1512 HVBatSOCV_HCP "-";
BA_ "Accuracy" SG_ 1512 SchCond_Time_Till_Dep "-";
BA_ "Accuracy" SG_ 1512 Service_Battery_Recharge_FailSts "-";
BA_ "GenSigStartValue" SG_ 1512 Service_Battery_Recharge_FailSts 1;
BA_ "Event trans." SG_ 1462 SWSError 0;
BA_ "GenSigSendType" SG_ 1462 SWSError 3;
BA_ "Event trans." SG_ 1268 FrontSensorSts 0;
BA_ "GenSigSendType" SG_ 1268 FrontSensorSts 1;
BA_ "Event trans." SG_ 1268 LateralSensorSts 0;
BA_ "GenSigSendType" SG_ 1268 LateralSensorSts 1;
BA_ "Event trans." SG_ 1268 PAMAboveSpeed 0;
BA_ "GenSigSendType" SG_ 1268 PAMAboveSpeed 1;
BA_ "Accuracy" SG_ 1268 PAMSystemFault "-";
BA_ "Event trans." SG_ 1268 PAMSystemFault 0;
BA_ "GenSigSendType" SG_ 1268 PAMSystemFault 1;
BA_ "Event trans." SG_ 1268 PAMSystemSts 0;
BA_ "GenSigSendType" SG_ 1268 PAMSystemSts 1;
BA_ "Event trans." SG_ 1268 RearSensorSts 0;
BA_ "GenSigSendType" SG_ 1268 RearSensorSts 1;
BA_ "Event trans." SG_ 1268 SDWFailSts 0;
BA_ "GenSigSendType" SG_ 1268 SDWFailSts 1;
BA_ "Event trans." SG_ 1458 AudioRequest 0;
BA_ "GenSigSendType" SG_ 1458 AudioRequest 3;
BA_ "Event trans." SG_ 1458 BUBFailSts 0;
BA_ "GenSigSendType" SG_ 1458 BUBFailSts 3;
BA_ "Event trans." SG_ 1458 CallSts 0;
BA_ "GenSigStartValue" SG_ 1458 CallSts 1;
BA_ "GenSigSendType" SG_ 1458 CallSts 3;
BA_ "Event trans." SG_ 1458 CallType 0;
BA_ "GenSigSendType" SG_ 1458 CallType 3;
BA_ "Event trans." SG_ 1458 GPSFailSts 0;
BA_ "GenSigSendType" SG_ 1458 GPSFailSts 3;
BA_ "Event trans." SG_ 1458 IVA 0;
BA_ "GenSigSendType" SG_ 1458 IVA 3;
BA_ "Event trans." SG_ 1458 LTESts 0;
BA_ "GenSigSendType" SG_ 1458 LTESts 3;
BA_ "Event trans." SG_ 1458 NetConnection 0;
BA_ "GenSigSendType" SG_ 1458 NetConnection 3;
BA_ "Event trans." SG_ 1458 PowerModeSts_TBM 0;
BA_ "GenSigSendType" SG_ 1458 PowerModeSts_TBM 3;
BA_ "Event trans." SG_ 1458 Provisioning 0;
BA_ "GenSigSendType" SG_ 1458 Provisioning 3;
BA_ "Event trans." SG_ 1458 SignalStrength 0;
BA_ "GenSigSendType" SG_ 1458 SignalStrength 3;
BA_ "Event trans." SG_ 1458 SOSCallStatus 0;
BA_ "GenSigSendType" SG_ 1458 SOSCallStatus 3;
BA_ "Event trans." SG_ 1458 SOSCallType 0;
BA_ "GenSigSendType" SG_ 1458 SOSCallType 3;
BA_ "Event trans." SG_ 1458 SOSFailSts 0;
BA_ "GenSigSendType" SG_ 1458 SOSFailSts 3;
BA_ "Event trans." SG_ 1458 SystemFailSts 0;
BA_ "GenSigSendType" SG_ 1458 SystemFailSts 3;
BA_ "Event trans." SG_ 1458 WiFiFailSts 0;
BA_ "GenSigSendType" SG_ 1458 WiFiFailSts 3;
BA_ "Event trans." SG_ 1458 WiFiSts 0;
BA_ "GenSigSendType" SG_ 1458 WiFiSts 3;
BA_ "Accuracy" SG_ 1470 AntitheftSts "-";
BA_ "Event trans." SG_ 1470 AntitheftSts 0;
BA_ "GenSigSendType" SG_ 1470 AntitheftSts 3;
BA_ "Accuracy" SG_ 1470 AUDIOSts_Telematic "-";
BA_ "Event trans." SG_ 1470 AUDIOSts_Telematic 0;
BA_ "GenSigStartValue" SG_ 1470 AUDIOSts_Telematic 1;
BA_ "GenSigSendType" SG_ 1470 AUDIOSts_Telematic 3;
BA_ "Accuracy" SG_ 1470 CurrentSource "-";
BA_ "Event trans." SG_ 1470 CurrentSource 0;
BA_ "GenSigSendType" SG_ 1470 CurrentSource 3;
BA_ "Accuracy" SG_ 1470 HFPSts "-";
BA_ "Event trans." SG_ 1470 HFPSts 0;
BA_ "GenSigSendType" SG_ 1470 HFPSts 3;
BA_ "Accuracy" SG_ 1470 MicrophoneFailSts "-";
BA_ "Event trans." SG_ 1470 MicrophoneFailSts 0;
BA_ "GenSigSendType" SG_ 1470 MicrophoneFailSts 3;
BA_ "Accuracy" SG_ 1470 MuteSts "-";
BA_ "Event trans." SG_ 1470 MuteSts 0;
BA_ "GenSigSendType" SG_ 1470 MuteSts 3;
BA_ "Accuracy" SG_ 1470 PowerModeSts_Telematic "-";
BA_ "Event trans." SG_ 1470 PowerModeSts_Telematic 0;
BA_ "GenSigSendType" SG_ 1470 PowerModeSts_Telematic 3;
BA_ "Accuracy" SG_ 1470 PowerSts_Telematic "-";
BA_ "Event trans." SG_ 1470 PowerSts_Telematic 0;
BA_ "GenSigSendType" SG_ 1470 PowerSts_Telematic 3;
BA_ "Accuracy" SG_ 1470 VolumeSts "-";
BA_ "Event trans." SG_ 1470 VolumeSts 0;
BA_ "GenSigSendType" SG_ 1470 VolumeSts 3;
BA_ "Accuracy" SG_ 1470 VolumeUnit "-";
BA_ "Event trans." SG_ 1470 VolumeUnit 0;
BA_ "GenSigSendType" SG_ 1470 VolumeUnit 3;
BA_ "Accuracy" SG_ 1470 VRSts "-";
BA_ "Event trans." SG_ 1470 VRSts 0;
BA_ "GenSigSendType" SG_ 1470 VRSts 3;
BA_ "Event trans." SG_ 1206 Ubss_Blind_RQSts 0;
BA_ "GenSigSendType" SG_ 1206 Ubss_Blind_RQSts 3;
BA_ "Event trans." SG_ 1206 Ubss_Cfg_StatSts 0;
BA_ "GenSigSendType" SG_ 1206 Ubss_Cfg_StatSts 3;
BA_ "Event trans." SG_ 1206 Ubss_LF_Chime_RQSts 0;
BA_ "GenSigSendType" SG_ 1206 Ubss_LF_Chime_RQSts 3;
BA_ "Event trans." SG_ 1206 Ubss_LR_Chime_RQSts 0;
BA_ "GenSigSendType" SG_ 1206 Ubss_LR_Chime_RQSts 3;
BA_ "Event trans." SG_ 1206 Ubss_LT_Chime_TypeSts 0;
BA_ "GenSigSendType" SG_ 1206 Ubss_LT_Chime_TypeSts 3;
BA_ "Event trans." SG_ 1206 Ubss_OPR_StatSts 0;
BA_ "GenSigSendType" SG_ 1206 Ubss_OPR_StatSts 3;
BA_ "Event trans." SG_ 1206 Ubss_RF_Chime_RQSts 0;
BA_ "GenSigSendType" SG_ 1206 Ubss_RF_Chime_RQSts 3;
BA_ "Event trans." SG_ 1206 Ubss_RR_Chime_RQSts 0;
BA_ "GenSigSendType" SG_ 1206 Ubss_RR_Chime_RQSts 3;
BA_ "Event trans." SG_ 1206 Ubss_RT_Chime_TypeSts 0;
BA_ "GenSigSendType" SG_ 1206 Ubss_RT_Chime_TypeSts 3;
BA_ "Event trans." SG_ 1206 Ubss_SRV_RQSts 0;
BA_ "GenSigSendType" SG_ 1206 Ubss_SRV_RQSts 3;
BA_ "Accuracy" SG_ 1206 Ubss_Sts "-";
BA_ "Event trans." SG_ 1206 Ubss_Sts 0;
BA_ "GenSigSendType" SG_ 1206 Ubss_Sts 3;
BA_ "Event trans." SG_ 1206 UbssLtLedFaultSts 0;
BA_ "GenSigSendType" SG_ 1206 UbssLtLedFaultSts 3;
BA_ "Event trans." SG_ 1206 UbssLtWrnSts 0;
BA_ "GenSigSendType" SG_ 1206 UbssLtWrnSts 3;
BA_ "Event trans." SG_ 1206 UbssRtLedFaultSts 0;
BA_ "GenSigSendType" SG_ 1206 UbssRtLedFaultSts 3;
BA_ "Event trans." SG_ 1206 UbssRtWrnSts 0;
BA_ "GenSigSendType" SG_ 1206 UbssRtWrnSts 3;
BA_ "Event trans." SG_ 750 Command_01Sts 0;
BA_ "GenSigSendType" SG_ 750 Command_01Sts 3;
BA_ "Event trans." SG_ 750 Command_02Sts 0;
BA_ "GenSigSendType" SG_ 750 Command_02Sts 3;
BA_ "Event trans." SG_ 750 Command_03Sts 0;
BA_ "GenSigSendType" SG_ 750 Command_03Sts 3;
BA_ "Event trans." SG_ 750 Command_04Sts 0;
BA_ "GenSigSendType" SG_ 750 Command_04Sts 3;
BA_ "Event trans." SG_ 750 Command_05Sts 0;
BA_ "GenSigSendType" SG_ 750 Command_05Sts 3;
BA_ "Event trans." SG_ 750 Command_06Sts 0;
BA_ "GenSigSendType" SG_ 750 Command_06Sts 3;
BA_ "Event trans." SG_ 750 Command_07Sts 0;
BA_ "GenSigSendType" SG_ 750 Command_07Sts 3;
BA_ "Event trans." SG_ 750 Command_08Sts 0;
BA_ "GenSigSendType" SG_ 750 Command_08Sts 3;
BA_ "Event trans." SG_ 750 Command_09Sts 0;
BA_ "GenSigSendType" SG_ 750 Command_09Sts 3;
BA_ "Event trans." SG_ 750 Command_10Sts 0;
BA_ "GenSigSendType" SG_ 750 Command_10Sts 3;
BA_ "Event trans." SG_ 750 Command_11Sts 0;
BA_ "GenSigSendType" SG_ 750 Command_11Sts 3;
BA_ "Event trans." SG_ 750 Command_12Sts 0;
BA_ "GenSigSendType" SG_ 750 Command_12Sts 3;
BA_ "Event trans." SG_ 750 Command_13Sts 0;
BA_ "GenSigSendType" SG_ 750 Command_13Sts 3;
BA_ "Event trans." SG_ 750 Command_14Sts 0;
BA_ "GenSigSendType" SG_ 750 Command_14Sts 3;
BA_ "Event trans." SG_ 750 Command_15Sts 0;
BA_ "GenSigSendType" SG_ 750 Command_15Sts 3;
BA_ "Event trans." SG_ 178 ChargeNow 0;
BA_ "GenSigSendType" SG_ 178 ChargeNow 1;
BA_ "Event trans." SG_ 172 Enable_Schedule1 0;
BA_ "GenSigSendType" SG_ 172 Enable_Schedule1 2;
BA_ "Event trans." SG_ 174 Enable_Schedule2 0;
BA_ "GenSigSendType" SG_ 174 Enable_Schedule2 2;
BA_ "Event trans." SG_ 176 Enable_Schedule3 0;
BA_ "GenSigSendType" SG_ 176 Enable_Schedule3 2;
BA_ "Event trans." SG_ 1480 FL_HS_Cmd_Tlm_Req 0;
BA_ "GenSigSendType" SG_ 1480 FL_HS_Cmd_Tlm_Req 3;
BA_ "Event trans." SG_ 1480 FR_HS_Cmd_Tlm_Req 0;
BA_ "GenSigSendType" SG_ 1480 FR_HS_Cmd_Tlm_Req 3;
BA_ "Event trans." SG_ 1480 HVAC_MAXDef_Req 0;
BA_ "GenSigSendType" SG_ 1480 HVAC_MAXDef_Req 3;
BA_ "Event trans." SG_ 1480 HVACAC_Req 0;
BA_ "GenSigSendType" SG_ 1480 HVACAC_Req 3;
BA_ "Event trans." SG_ 1480 HVACAuto_Req 0;
BA_ "GenSigSendType" SG_ 1480 HVACAuto_Req 3;
BA_ "Event trans." SG_ 1480 HVACFrontDef_Req 0;
BA_ "GenSigSendType" SG_ 1480 HVACFrontDef_Req 3;
BA_ "Event trans." SG_ 1480 HVACFunc_Req 0;
BA_ "GenSigSendType" SG_ 1480 HVACFunc_Req 3;
BA_ "Event trans." SG_ 1480 HVACJumpVAL 0;
BA_ "GenSigSendType" SG_ 1480 HVACJumpVAL 3;
BA_ "Event trans." SG_ 1480 HVACMaxAC_Req 0;
BA_ "GenSigSendType" SG_ 1480 HVACMaxAC_Req 3;
BA_ "Event trans." SG_ 1480 HVACMode_Req 0;
BA_ "GenSigSendType" SG_ 1480 HVACMode_Req 3;
BA_ "Event trans." SG_ 1480 HVACPower_Req 0;
BA_ "GenSigSendType" SG_ 1480 HVACPower_Req 3;
BA_ "Event trans." SG_ 1480 HVACRearDef_Req 0;
BA_ "GenSigSendType" SG_ 1480 HVACRearDef_Req 3;
BA_ "Event trans." SG_ 1480 HVACRecirc_Req 0;
BA_ "GenSigSendType" SG_ 1480 HVACRecirc_Req 3;
BA_ "Event trans." SG_ 1052 Radio_btn0_Req 0;
BA_ "GenSigSendType" SG_ 1052 Radio_btn0_Req 3;
BA_ "Event trans." SG_ 1052 Radio_btn1_Req 0;
BA_ "GenSigSendType" SG_ 1052 Radio_btn1_Req 3;
BA_ "Event trans." SG_ 1052 Radio_Knob1_DIR_Req 0;
BA_ "GenSigSendType" SG_ 1052 Radio_Knob1_DIR_Req 5;
BA_ "Accuracy" SG_ 1052 Radio_Knob1_VAL_Req "1";
BA_ "Accuracy" SG_ 144 FrameNumber "-";
BA_ "Event trans." SG_ 144 FrameNumber 0;
BA_ "GenSigSendType" SG_ 144 FrameNumber 1;
BA_ "Accuracy" SG_ 144 InfoCode "-";
BA_ "Accuracy" SG_ 144 TotalFrameNumber "-";
BA_ "Accuracy" SG_ 144 UTF_Text_1 "-";
BA_ "Accuracy" SG_ 144 UTF_Text_2 "-";
BA_ "Accuracy" SG_ 144 UTF_Text_3 "-";
BA_ "Event trans." SG_ 1502 TGW_PT_CAB_DRSts 0;
BA_ "GenSigSendType" SG_ 1502 TGW_PT_CAB_DRSts 3;
BA_ "Accuracy" SG_ 1502 TGW_RQ1Sts "1";
BA_ "Event trans." SG_ 1502 TGW_RQ1Sts 0;
BA_ "GenSigSendType" SG_ 1502 TGW_RQ1Sts 3;
BA_ "Event trans." SG_ 1500 TGW_DISP_STATSts 0;
BA_ "GenSigSendType" SG_ 1500 TGW_DISP_STATSts 3;
BA_ "Event trans." SG_ 126 CurrTimeMin 0;
BA_ "GenSigSendType" SG_ 126 CurrTimeMin 3;
BA_ "Event trans." SG_ 126 CurrTimeSec 0;
BA_ "GenSigSendType" SG_ 126 CurrTimeSec 3;
BA_ "Event trans." SG_ 126 DLS 0;
BA_ "GenSigSendType" SG_ 126 DLS 3;
BA_ "Event trans." SG_ 126 PresetNumber 0;
BA_ "GenSigSendType" SG_ 126 PresetNumber 3;
BA_ "Event trans." SG_ 126 Presets 0;
BA_ "GenSigSendType" SG_ 126 Presets 3;
BA_ "Event trans." SG_ 126 ProgressBarPerc 0;
BA_ "GenSigSendType" SG_ 126 ProgressBarPerc 3;
BA_ "Event trans." SG_ 126 PTY 0;
BA_ "GenSigSendType" SG_ 126 PTY 3;
BA_ "Event trans." SG_ 126 RadioText 0;
BA_ "GenSigSendType" SG_ 126 RadioText 3;
BA_ "Event trans." SG_ 126 TotDurMin 0;
BA_ "GenSigSendType" SG_ 126 TotDurMin 3;
BA_ "Event trans." SG_ 126 TotDurSec 0;
BA_ "GenSigSendType" SG_ 126 TotDurSec 3;
BA_ "Event trans." SG_ 126 TrafficAnnouncement 0;
BA_ "GenSigSendType" SG_ 126 TrafficAnnouncement 3;
BA_ "Accuracy" SG_ 136 Direction "-";
BA_ "Event trans." SG_ 136 Direction 0;
BA_ "GenSigSendType" SG_ 136 Direction 3;
BA_ "Accuracy" SG_ 136 DistToTurn "-";
BA_ "Event trans." SG_ 136 DistToTurn 0;
BA_ "GenSigSendType" SG_ 136 DistToTurn 3;
BA_ "Accuracy" SG_ 136 LastAnnouncement "-";
BA_ "Event trans." SG_ 136 LastAnnouncement 0;
BA_ "GenSigSendType" SG_ 136 LastAnnouncement 3;
BA_ "Accuracy" SG_ 136 ResolutionDistToTurn "-";
BA_ "Accuracy" SG_ 136 Unit "-";
BA_ "Event trans." SG_ 136 Unit 0;
BA_ "GenSigStartValue" SG_ 136 Unit 6;
BA_ "GenSigSendType" SG_ 136 Unit 3;
BA_ "Event trans." SG_ 124 BatteryLevel 0;
BA_ "GenSigSendType" SG_ 124 BatteryLevel 3;
BA_ "Event trans." SG_ 124 ConnectedPhoneID 0;
BA_ "GenSigSendType" SG_ 124 ConnectedPhoneID 3;
BA_ "Event trans." SG_ 124 IsFavorite 0;
BA_ "GenSigSendType" SG_ 124 IsFavorite 3;
BA_ "Event trans." SG_ 124 NetworkID 0;
BA_ "GenSigSendType" SG_ 124 NetworkID 3;
BA_ "Event trans." SG_ 124 PowerSignal 0;
BA_ "GenSigSendType" SG_ 124 PowerSignal 3;
BA_ "Accuracy" SG_ 170 ClearPersonalDataReq "-";
BA_ "Event trans." SG_ 170 ClearPersonalDataReq 0;
BA_ "GenSigSendType" SG_ 170 ClearPersonalDataReq 1;
BA_ "Accuracy" SG_ 170 PrivacyModeReq "-";
BA_ "Event trans." SG_ 170 PrivacyModeReq 0;
BA_ "GenSigSendType" SG_ 170 PrivacyModeReq 1;
BA_ "Accuracy" SG_ 170 RestoreAppReq "-";
BA_ "Event trans." SG_ 170 RestoreAppReq 0;
BA_ "GenSigSendType" SG_ 170 RestoreAppReq 1;
BA_ "Accuracy" SG_ 170 RestoreDefaultSettingReq "-";
BA_ "Event trans." SG_ 170 RestoreDefaultSettingReq 0;
BA_ "GenSigSendType" SG_ 170 RestoreDefaultSettingReq 1;
BA_ "Accuracy" SG_ 156 Day1_TLM "-";
BA_ "Event trans." SG_ 156 Day1_TLM 0;
BA_ "GenSigSendType" SG_ 156 Day1_TLM 1;
BA_ "Accuracy" SG_ 156 Day2_TLM "-";
BA_ "Accuracy" SG_ 156 Hour1_TLM "-";
BA_ "Accuracy" SG_ 156 Hour2_TLM "-";
BA_ "Accuracy" SG_ 156 Minute1_TLM "-";
BA_ "Accuracy" SG_ 156 Minute2_TLM "-";
BA_ "Accuracy" SG_ 156 Month1_TLM "-";
BA_ "Accuracy" SG_ 156 Month2_TLM "-";
BA_ "Accuracy" SG_ 156 Year1_TLM "-";
BA_ "Accuracy" SG_ 156 Year2_TLM "-";
BA_ "Accuracy" SG_ 156 Year3_TLM "-";
BA_ "Accuracy" SG_ 156 Year4_TLM "-";
BA_ "Accuracy" SG_ 158 AutoHighBeamEnable_Req "-";
BA_ "Event trans." SG_ 158 AutoHighBeamEnable_Req 0;
BA_ "GenSigStartValue" SG_ 158 AutoHighBeamEnable_Req 1;
BA_ "GenSigSendType" SG_ 158 AutoHighBeamEnable_Req 1;
BA_ "Event trans." SG_ 158 AutoParkBrake_Req 0;
BA_ "GenSigSendType" SG_ 158 AutoParkBrake_Req 1;
BA_ "Accuracy" SG_ 158 BSDEnable_Req "-";
BA_ "Event trans." SG_ 158 BSDEnable_Req 0;
BA_ "GenSigStartValue" SG_ 158 BSDEnable_Req 2;
BA_ "GenSigSendType" SG_ 158 BSDEnable_Req 1;
BA_ "Accuracy" SG_ 158 CorneringEnable_Req "-";
BA_ "Event trans." SG_ 158 CorneringEnable_Req 0;
BA_ "GenSigSendType" SG_ 158 CorneringEnable_Req 1;
BA_ "Accuracy" SG_ 158 DistanceUnit_Req "-";
BA_ "Event trans." SG_ 158 DistanceUnit_Req 0;
BA_ "GenSigSendType" SG_ 158 DistanceUnit_Req 1;
BA_ "Accuracy" SG_ 158 DRLEnable_Req "-";
BA_ "Event trans." SG_ 158 DRLEnable_Req 0;
BA_ "GenSigSendType" SG_ 158 DRLEnable_Req 1;
BA_ "Accuracy" SG_ 158 ExternalLightSensorLevel_Req "-";
BA_ "Event trans." SG_ 158 ExternalLightSensorLevel_Req 0;
BA_ "GenSigStartValue" SG_ 158 ExternalLightSensorLevel_Req 1;
BA_ "GenSigSendType" SG_ 158 ExternalLightSensorLevel_Req 1;
BA_ "Accuracy" SG_ 158 HourMode_Req "-";
BA_ "Event trans." SG_ 158 HourMode_Req 0;
BA_ "GenSigSendType" SG_ 158 HourMode_Req 1;
BA_ "Accuracy" SG_ 158 LanguageSelection_Req "-";
BA_ "Event trans." SG_ 158 LanguageSelection_Req 0;
BA_ "GenSigSendType" SG_ 158 LanguageSelection_Req 1;
BA_ "Event trans." SG_ 158 PamAlertMode_Req 0;
BA_ "GenSigStartValue" SG_ 158 PamAlertMode_Req 2;
BA_ "GenSigSendType" SG_ 158 PamAlertMode_Req 1;
BA_ "Event trans." SG_ 158 PamChimeVolumeFront_Req 0;
BA_ "GenSigStartValue" SG_ 158 PamChimeVolumeFront_Req 1;
BA_ "GenSigSendType" SG_ 158 PamChimeVolumeFront_Req 1;
BA_ "Event trans." SG_ 158 PamChimeVolumeRear_Req 0;
BA_ "GenSigStartValue" SG_ 158 PamChimeVolumeRear_Req 1;
BA_ "GenSigSendType" SG_ 158 PamChimeVolumeRear_Req 1;
BA_ "Event trans." SG_ 158 PassiveEntry_Req 0;
BA_ "GenSigSendType" SG_ 158 PassiveEntry_Req 1;
BA_ "Accuracy" SG_ 158 RainSensorLevel_Req "-";
BA_ "Event trans." SG_ 158 RainSensorLevel_Req 0;
BA_ "GenSigStartValue" SG_ 158 RainSensorLevel_Req 1;
BA_ "GenSigSendType" SG_ 158 RainSensorLevel_Req 1;
BA_ "Event trans." SG_ 158 RemoteDoorUnlock_Req 0;
BA_ "GenSigStartValue" SG_ 158 RemoteDoorUnlock_Req 1;
BA_ "GenSigSendType" SG_ 158 RemoteDoorUnlock_Req 1;
BA_ "Event trans." SG_ 158 Sdw_Req 0;
BA_ "GenSigStartValue" SG_ 158 Sdw_Req 2;
BA_ "GenSigSendType" SG_ 158 Sdw_Req 1;
BA_ "Event trans." SG_ 158 SoundHornLock_Req 0;
BA_ "GenSigStartValue" SG_ 158 SoundHornLock_Req 1;
BA_ "GenSigSendType" SG_ 158 SoundHornLock_Req 1;
BA_ "Event trans." SG_ 158 SoundHornRemoteStart_Req 0;
BA_ "GenSigSendType" SG_ 158 SoundHornRemoteStart_Req 1;
BA_ "Accuracy" SG_ 158 SpeedLockDoorEnable_Req "-";
BA_ "Event trans." SG_ 158 SpeedLockDoorEnable_Req 0;
BA_ "GenSigSendType" SG_ 158 SpeedLockDoorEnable_Req 1;
BA_ "Accuracy" SG_ 158 TemperatureUnit_Req "-";
BA_ "Event trans." SG_ 158 TemperatureUnit_Req 0;
BA_ "GenSigSendType" SG_ 158 TemperatureUnit_Req 1;
BA_ "Accuracy" SG_ 162 AutoUnlockDoorExit_Req "-";
BA_ "Event trans." SG_ 162 AutoUnlockDoorExit_Req 0;
BA_ "GenSigStartValue" SG_ 162 AutoUnlockDoorExit_Req 1;
BA_ "GenSigSendType" SG_ 162 AutoUnlockDoorExit_Req 1;
BA_ "Accuracy" SG_ 162 EPB_MaintenanceMode_Req "-";
BA_ "Event trans." SG_ 162 EPB_MaintenanceMode_Req 0;
BA_ "GenSigSendType" SG_ 162 EPB_MaintenanceMode_Req 1;
BA_ "Event trans." SG_ 162 EV_ConsumptionUnit_Req 0;
BA_ "GenSigSendType" SG_ 162 EV_ConsumptionUnit_Req 1;
BA_ "Accuracy" SG_ 162 FlashLightWLock_Req "-";
BA_ "Event trans." SG_ 162 FlashLightWLock_Req 0;
BA_ "GenSigStartValue" SG_ 162 FlashLightWLock_Req 1;
BA_ "GenSigSendType" SG_ 162 FlashLightWLock_Req 1;
BA_ "Accuracy" SG_ 162 FSFCWPlusActivationMode_Req "-";
BA_ "Event trans." SG_ 162 FSFCWPlusActivationMode_Req 0;
BA_ "GenSigStartValue" SG_ 162 FSFCWPlusActivationMode_Req 1;
BA_ "GenSigSendType" SG_ 162 FSFCWPlusActivationMode_Req 1;
BA_ "Accuracy" SG_ 162 FSFCWPlusSetting_Req "-";
BA_ "Event trans." SG_ 162 FSFCWPlusSetting_Req 0;
BA_ "GenSigStartValue" SG_ 162 FSFCWPlusSetting_Req 3;
BA_ "GenSigSendType" SG_ 162 FSFCWPlusSetting_Req 1;
BA_ "Accuracy" SG_ 162 HeadlightsOffDelay_Req "-";
BA_ "Event trans." SG_ 162 HeadlightsOffDelay_Req 0;
BA_ "GenSigSendType" SG_ 162 HeadlightsOffDelay_Req 1;
BA_ "Accuracy" SG_ 162 LDW_Intensity_Req "-";
BA_ "Event trans." SG_ 162 LDW_Intensity_Req 0;
BA_ "GenSigSendType" SG_ 162 LDW_Intensity_Req 1;
BA_ "Accuracy" SG_ 162 LDW_Sensibility_Req "-";
BA_ "Event trans." SG_ 162 LDW_Sensibility_Req 0;
BA_ "GenSigStartValue" SG_ 162 LDW_Sensibility_Req 3;
BA_ "GenSigSendType" SG_ 162 LDW_Sensibility_Req 1;
BA_ "Accuracy" SG_ 162 PowerLevelReq "-";
BA_ "Event trans." SG_ 162 PowerLevelReq 0;
BA_ "GenSigStartValue" SG_ 162 PowerLevelReq 2;
BA_ "GenSigSendType" SG_ 162 PowerLevelReq 1;
BA_ "Accuracy" SG_ 162 RemStNrmlStEnbl_Req "-";
BA_ "Event trans." SG_ 162 RemStNrmlStEnbl_Req 0;
BA_ "GenSigStartValue" SG_ 162 RemStNrmlStEnbl_Req 2;
BA_ "GenSigSendType" SG_ 162 RemStNrmlStEnbl_Req 1;
BA_ "Event trans." SG_ 162 TSREnableReq 0;
BA_ "GenSigSendType" SG_ 162 TSREnableReq 1;
BA_ "Accuracy" SG_ 162 TyrePressureUnit_Req "-";
BA_ "Event trans." SG_ 162 TyrePressureUnit_Req 0;
BA_ "GenSigStartValue" SG_ 162 TyrePressureUnit_Req 2;
BA_ "GenSigSendType" SG_ 162 TyrePressureUnit_Req 1;
BA_ "Event trans." SG_ 1291 AutoHoldReq 0;
BA_ "GenSigStartValue" SG_ 1291 AutoHoldReq 1;
BA_ "GenSigSendType" SG_ 1291 AutoHoldReq 1;
BA_ "Accuracy" SG_ 1291 Drowsy_Driver_Alert_Req "-";
BA_ "Event trans." SG_ 1291 Drowsy_Driver_Alert_Req 0;
BA_ "GenSigStartValue" SG_ 1291 Drowsy_Driver_Alert_Req 1;
BA_ "GenSigSendType" SG_ 1291 Drowsy_Driver_Alert_Req 1;
BA_ "Event trans." SG_ 1291 Speed_Unit_Req 0;
BA_ "GenSigStartValue" SG_ 1291 Speed_Unit_Req 1;
BA_ "GenSigSendType" SG_ 1291 Speed_Unit_Req 1;
BA_ "Event trans." SG_ 163 GreetingLightsLevel_Req 0;
BA_ "GenSigSendType" SG_ 163 GreetingLightsLevel_Req 1;
BA_ "Event trans." SG_ 163 HUtoIPC_NAV_Sts 0;
BA_ "GenSigStartValue" SG_ 163 HUtoIPC_NAV_Sts 1;
BA_ "GenSigSendType" SG_ 163 HUtoIPC_NAV_Sts 1;
BA_ "Event trans." SG_ 163 New_Spd_Zone_Ind_Req 0;
BA_ "GenSigStartValue" SG_ 163 New_Spd_Zone_Ind_Req 1;
BA_ "GenSigSendType" SG_ 163 New_Spd_Zone_Ind_Req 1;
BA_ "Event trans." SG_ 163 SignCaptureModeReq 0;
BA_ "GenSigSendType" SG_ 163 SignCaptureModeReq 1;
BA_ "Event trans." SG_ 163 Traffic_Sign_Warn_Req 0;
BA_ "GenSigStartValue" SG_ 163 Traffic_Sign_Warn_Req 1;
BA_ "GenSigSendType" SG_ 163 Traffic_Sign_Warn_Req 1;
BA_ "Event trans." SG_ 192 TSI_WarningTolerance_Req 0;
BA_ "GenSigSendType" SG_ 192 TSI_WarningTolerance_Req 1;
BA_ "Accuracy" SG_ 1892 Day1 "-";
BA_ "Accuracy" SG_ 1892 Day2 "-";
BA_ "Accuracy" SG_ 1892 Hour1 "-";
BA_ "Accuracy" SG_ 1892 Hour2 "-";
BA_ "Accuracy" SG_ 1892 Minute1 "-";
BA_ "Accuracy" SG_ 1892 Minute2 "-";
BA_ "Accuracy" SG_ 1892 Month1 "-";
BA_ "Accuracy" SG_ 1892 Month2 "-";
BA_ "Accuracy" SG_ 1892 Year1 "-";
BA_ "Accuracy" SG_ 1892 Year2 "-";
BA_ "Accuracy" SG_ 1892 Year3 "-";
BA_ "Accuracy" SG_ 1892 Year4 "-";
BA_ "Accuracy" SG_ 1472 AverageFuelConsumptionAPlus "-";
BA_ "Event trans." SG_ 1472 AverageFuelConsumptionAPlus 0;
BA_ "GenSigSendType" SG_ 1472 AverageFuelConsumptionAPlus 3;
BA_ "Accuracy" SG_ 1472 AverageSpeedAPlus "-";
BA_ "Event trans." SG_ 1472 AverageSpeedAPlus 0;
BA_ "GenSigSendType" SG_ 1472 AverageSpeedAPlus 3;
BA_ "Accuracy" SG_ 1472 PartialOdometerAPlus "-";
BA_ "Event trans." SG_ 1472 PartialOdometerAPlus 0;
BA_ "GenSigSendType" SG_ 1472 PartialOdometerAPlus 3;
BA_ "Accuracy" SG_ 1472 TravelingTimeAPlus_Hour "-";
BA_ "Event trans." SG_ 1472 TravelingTimeAPlus_Hour 0;
BA_ "GenSigSendType" SG_ 1472 TravelingTimeAPlus_Hour 3;
BA_ "Accuracy" SG_ 1472 TravelingTimeAPlus_Minute "-";
BA_ "Event trans." SG_ 1472 TravelingTimeAPlus_Minute 0;
BA_ "GenSigSendType" SG_ 1472 TravelingTimeAPlus_Minute 3;
BA_ "Accuracy" SG_ 1472 TravelingTimeAPlus_Second "-";
BA_ "Accuracy" SG_ 1888 AutonomyDistance "-";
BA_ "Accuracy" SG_ 1888 InstantaneousFuelConsumption1 "-";
BA_ "Accuracy" SG_ 1888 InstantaneousFuelConsumption2 "-";
BA_ "Accuracy" SG_ 1888 InstantaneousFuelConsumption3 "-";
BA_ "Accuracy" SG_ 1888 TotalOdometer "-";
BA_ "Accuracy" SG_ 1476 AverageFuelConsumptionBPlus "-";
BA_ "Event trans." SG_ 1476 AverageFuelConsumptionBPlus 0;
BA_ "GenSigSendType" SG_ 1476 AverageFuelConsumptionBPlus 3;
BA_ "Accuracy" SG_ 1476 AverageSpeedBPlus "+/- 0,1";
BA_ "Event trans." SG_ 1476 AverageSpeedBPlus 0;
BA_ "GenSigSendType" SG_ 1476 AverageSpeedBPlus 3;
BA_ "Accuracy" SG_ 1476 PartialOdometerBPlus "+/- 0,1";
BA_ "Event trans." SG_ 1476 PartialOdometerBPlus 0;
BA_ "GenSigSendType" SG_ 1476 PartialOdometerBPlus 3;
BA_ "Accuracy" SG_ 1476 TravelingTimeBPlus_Hour "-";
BA_ "Event trans." SG_ 1476 TravelingTimeBPlus_Hour 0;
BA_ "GenSigSendType" SG_ 1476 TravelingTimeBPlus_Hour 3;
BA_ "Accuracy" SG_ 1476 TravelingTimeBPlus_Minute "-";
BA_ "Event trans." SG_ 1476 TravelingTimeBPlus_Minute 0;
BA_ "GenSigSendType" SG_ 1476 TravelingTimeBPlus_Minute 3;
BA_ "Accuracy" SG_ 1476 TravelingTimeBPlus_Second "-";
BA_ "Event trans." SG_ 1444 Electric_Dist_Kilometers 0;
BA_ "GenSigSendType" SG_ 1444 Electric_Dist_Kilometers 3;
BA_ "Event trans." SG_ 1444 Electric_Dist_Miles 0;
BA_ "GenSigSendType" SG_ 1444 Electric_Dist_Miles 3;
BA_ "Accuracy" SG_ 748 UConnReq "-";
BA_ "Event trans." SG_ 748 UConnReq 0;
BA_ "GenSigSendType" SG_ 748 UConnReq 6;
BA_ "Accuracy" SG_ 748 UConnReqAuthCode "-";
BA_ "Accuracy" SG_ 748 UConnReqFOBNum "-";
BA_ "Event trans." SG_ 1976 UConnSeed1 0;
BA_ "GenSigSendType" SG_ 1976 UConnSeed1 1;
BA_ "Event trans." SG_ 1976 UConnSeed2 0;
BA_ "GenSigSendType" SG_ 1976 UConnSeed2 1;
BA_ "Event trans." SG_ 1976 UConnSeed3 0;
BA_ "GenSigSendType" SG_ 1976 UConnSeed3 1;
BA_ "Event trans." SG_ 1976 UConnSeed4 0;
BA_ "GenSigSendType" SG_ 1976 UConnSeed4 1;
BA_ "GenSigStartValue" SG_ 992 VIN_MSG 3;
BA_ "Accuracy" SG_ 132 FrameNumber "-";
BA_ "Event trans." SG_ 132 FrameNumber 0;
BA_ "GenSigSendType" SG_ 132 FrameNumber 1;
BA_ "Accuracy" SG_ 132 TotalFrameNumber "-";
BA_ "Accuracy" SG_ 132 UTF_Char1 "-";
BA_ "Accuracy" SG_ 132 UTF_Char2 "-";
BA_ "Accuracy" SG_ 132 UTF_Char3 "-";
BA_ "Accuracy" SG_ 132 UTF_Char4 "-";
BA_ "Accuracy" SG_ 132 UTF_Char5 "-";
BA_ "Accuracy" SG_ 132 UTF_Char6 "-";
BA_ "Accuracy" SG_ 132 UTF_Char7 "-";
BA_ "Accuracy" SG_ 130 FrameNumber "-";
BA_ "Event trans." SG_ 130 FrameNumber 0;
BA_ "GenSigSendType" SG_ 130 FrameNumber 1;
BA_ "Accuracy" SG_ 130 TotalFrameNumber "-";
BA_ "Accuracy" SG_ 130 UTF_Char1 "-";
BA_ "Accuracy" SG_ 130 UTF_Char2 "-";
BA_ "Accuracy" SG_ 130 UTF_Char3 "-";
BA_ "Accuracy" SG_ 130 UTF_Char4 "-";
BA_ "Accuracy" SG_ 130 UTF_Char5 "-";
BA_ "Accuracy" SG_ 130 UTF_Char6 "-";
BA_ "Accuracy" SG_ 130 UTF_Char7 "-";
VAL_ 1283 ManDispCtrl 0 "Not_Active" 1 "Active";
VAL_ 1283 RQ_DISP_INTS 255 "SNA";
VAL_ 1289 ChargeNow 0 "No_Charge" 1 "Charge_Now";
VAL_ 948 SDW_ChimeActivation_LHF 0 "NotActive" 1 "Active";
VAL_ 948 SDW_ChimeActivation_LHR 0 "NotActive" 1 "Active";
VAL_ 948 SDW_ChimeActivation_RHF 0 "NotActive" 1 "Active";
VAL_ 948 SDW_ChimeActivation_RHR 0 "NotActive" 1 "Active";
VAL_ 948 SDW_ChimeType_Left 0 "Type8" 1 "Type6";
VAL_ 948 SDW_ChimeType_Right 0 "Type8" 1 "Type6";
VAL_ 948 SDW_DisplayActivation 0 "NotActive" 1 "Active";
VAL_ 948 SDW_ObstacleInTrajectory_LLF 0 "True" 1 "False";
VAL_ 948 SDW_ObstacleInTrajectory_LLR 0 "True" 1 "False";
VAL_ 948 SDW_ObstacleInTrajectory_LRF 0 "True" 1 "False";
VAL_ 948 SDW_ObstacleInTrajectory_LRR 0 "True" 1 "False";
VAL_ 948 SDW_Warning_Left_1 0 "NoWarning" 1 "Area1" 2 "Area2" 3 "NotActive";
VAL_ 948 SDW_Warning_Left_2 0 "NoWarning" 1 "Area1" 2 "Area2" 3 "NotActive";
VAL_ 948 SDW_Warning_Right_1 0 "NoWarning" 1 "Area1" 2 "Area2" 3 "NotActive";
VAL_ 948 SDW_Warning_Right_2 0 "NoWarning" 1 "Area1" 2 "Area2" 3 "NotActive";
VAL_ 173 ADAS_Seg_BuildUpArea 0 "No_built_up_area" 1 "Built_up_area" 2 "Unknown" 3 "SNA";
VAL_ 173 ADAS_Seg_DividedRoad 0 "SgmntIsNotPartOfDividedRoad_DualCarriage" 1 "SgmntIsPartOfDvddRdDualCrrgway" 2 "Unknown" 3 "SNA";
VAL_ 173 ADAS_Seg_EffSpdLmt 0 "Unknown" 1 "Less_Equal_5kmh" 2 "7_kmh_mph" 3 "10_kmh_mph" 4 "15_kmh_mph" 5 "20_kmh_mph" 6 "25_kmh_mph" 7 "30_kmh_mph" 8 "35_kmh_mph" 9 "40_kmh_mph" 10 "45_kmh_mph" 11 "50_kmh_mph" 12 "55_kmh_mph" 13 "60_kmh_mph" 14 "65_kmh_mph" 15 "70_kmh_mph" 16 "75_kmh_mph" 17 "80_kmh_mph" 18 "85_kmh_mph" 19 "90_kmh_mph" 20 "95_kmh_mph" 21 "100_kmh_mph" 22 "105_kmh_mph" 23 "110_kmh_mph" 24 "115_kmh_mph" 25 "120_kmh_mph" 26 "130_kmh_mph" 27 "140_kmh_mph" 28 "150_kmh_mph" 29 "160_kmh_mph" 30 "Unlimited" 31 "Invalid";
VAL_ 173 ADAS_Seg_EffSpdLmtType 0 "Implicit" 1 "Explicit_On_Traffic_Sign" 2 "Explicit_Night" 3 "Explicit_Day" 4 "Explicit_Time_of_day" 5 "Explicit_Rain" 6 "Explicit_Snow" 7 "Unknown";
VAL_ 173 ADAS_Seg_FormOfWay 0 "TYPE_0" 1 "TYPE_1" 2 "TYPE_2" 3 "TYPE_3" 4 "TYPE_4" 5 "TYPE_5" 6 "TYPE_6" 7 "TYPE_7" 8 "TYPE_8" 9 "TYPE_9" 10 "TYPE_10" 11 "TYPE_11" 12 "TYPE_12" 13 "TYPE_13" 14 "TYPE_14" 15 "SNA";
VAL_ 173 ADAS_Seg_FuncRoadClass 0 "Unknown" 1 "Priority_1" 2 "Priority_2" 3 "Priority_3" 4 "Priority_4" 5 "Priority_5" 6 "Priority_6" 7 "SNA";
VAL_ 173 ADAS_Seg_NumOfLaneDrvDir 0 "Wrong_Direction" 1 "Nmbr_Lanes_1" 2 "Nmbr_Lanes_2" 3 "Nmbr_Lanes_3" 4 "Nmbr_Lanes_4" 5 "Nmbr_Lanes_5" 6 "Nmbr_Lanes_6_or_more" 7 "SNA";
VAL_ 173 ADAS_Seg_PathIdx 0 "Map_data_valid" 1 "Map_data_not_valid_1" 2 "Map_data_not_valid_2" 3 "Map_data_not_valid_3" 4 "Map_data_not_valid_4" 5 "Map_data_not_valid_5" 6 "Map_data_not_valid_6" 7 "Map_data_not_valid_7" 8 "Map_data_not_valid_8" 9 "Map_data_not_valid_9" 10 "Map_data_not_valid_10" 11 "Map_data_not_valid_11" 12 "Map_data_not_valid_12" 13 "Map_data_not_valid_13" 14 "Map_data_not_valid_14" 15 "Map_data_not_valid_15" 16 "Map_data_not_valid_16" 17 "Map_data_not_valid_17" 18 "Map_data_not_valid_18" 19 "Map_data_not_valid_19" 20 "Map_data_not_valid_20" 21 "Map_data_not_valid_21" 22 "Map_data_not_valid_22" 23 "Map_data_not_valid_23" 24 "Map_data_not_valid_24" 25 "Map_data_not_valid_25" 26 "Map_data_not_valid_26" 27 "Map_data_not_valid_27" 28 "Map_data_not_valid_28" 29 "Map_data_not_valid_29" 30 "Map_data_not_valid_30" 31 "Map_data_not_valid_31" 32 "Map_data_not_valid_32" 33 "Map_data_not_valid_33" 34 "Map_data_not_valid_34" 35 "Map_data_not_valid_35" 36 "Map_data_not_valid_36" 37 "Map_data_not_valid_37" 38 "Map_data_not_valid_38" 39 "Map_data_not_valid_39" 40 "Map_data_not_valid_40" 41 "Map_data_not_valid_41" 42 "Map_data_not_valid_42" 43 "Map_data_not_valid_43" 44 "Map_data_not_valid_44" 45 "Map_data_not_valid_45" 46 "Map_data_not_valid_46" 47 "Map_data_not_valid_47" 48 "Map_data_not_valid_48" 49 "Map_data_not_valid_49" 50 "Map_data_not_valid_50" 51 "Map_data_not_valid_51" 52 "Map_data_not_valid_52" 53 "Map_data_not_valid_53" 54 "Map_data_not_valid_54" 55 "Map_data_not_valid_55" 56 "Map_data_not_valid_56" 57 "Map_data_not_valid_57" 58 "Map_data_not_valid_58" 59 "Map_data_not_valid_59" 60 "Map_data_not_valid_60" 61 "Map_data_not_valid_61" 62 "Map_data_not_valid_62" 63 "Map_data_not_valid_63";
VAL_ 1454 CallAction 0 "No_Action" 1 "Iniziate" 2 "Start" 3 "Cancel" 4 "Terminate";
VAL_ 1454 CallRequest 0 "No-Call" 1 "E-Call" 2 "B-Call" 3 "B1-Call" 4 "B2-Call" 5 "B3-Call" 6 "IVA-Call";
VAL_ 1454 TBMUpdateAction 0 "No_Action" 1 "Update_Later" 2 "Update_Now";
VAL_ 1454 WiFiReq 0 "Off" 1 "On";
VAL_ 1446 ClearPersonalData 0 "Not_Active" 1 "Active";
VAL_ 1446 PrivacyMode 0 "Not_Active" 1 "Active";
VAL_ 1446 RestoreApp 0 "Not_Active" 1 "Active";
VAL_ 1446 RestoreDefaultSetting 0 "Not_Active" 1 "Active";
VAL_ 1446 TelematicSetupAck 0 "No_ACK_Required" 1 "ACK_KO" 2 "ACK_OK";
VAL_ 1890 DaysToService 511 "SNA";
VAL_ 1890 DistanceToService 131071 "SNA";
VAL_ 2000 AMP_DSS_STATSts 0 "CFG_ST" 1 "CFG_VID_SURR" 2 "CFG_AUD_SURR" 7 "SNA";
VAL_ 2000 AMP_MUTEDSts 1 "Muted" 0 "Unmuted";
VAL_ 2000 AUDIOSts_AMP 0 "Initialization" 1 "Available" 2 "Not_Available";
VAL_ 2000 PowerModeSts_AMP 0 "Standard_Power" 1 "Logistic_Mode_ON" 2 "Logistic_Mode_PR" 3 "Not_Used";
VAL_ 2000 SURR_AVAILSts 1 "TRUE" 0 "FALSE";
VAL_ 854 BonnetSts 0 "Closed" 1 "Open";
VAL_ 854 BrakeFluidLevelSts 0 "Ok" 1 "Low_Level";
VAL_ 854 FrontWiperMoveSts 0 "Stop" 1 "Moving";
VAL_ 854 LHRDoorSts 0 "Closed" 1 "Open";
VAL_ 854 NightAndDaySensorFailSts 0 "Fail_Not_Present" 1 "Fail_Present";
VAL_ 854 ParkBrakeSts 0 "OFF" 1 "ON";
VAL_ 854 PowerModeSts 0 "Standard_Power" 1 "Logistic_Mode_ON" 2 "Logistic_Mode_PR" 3 "Not_Used";
VAL_ 854 RainSensorFailSts 0 "Fail_not_present" 1 "Fail_present";
VAL_ 854 RearTrunkEnableLastElSts 0 "Disabled" 1 "Enabled";
VAL_ 854 RHatchSts 0 "Closed" 1 "Open";
VAL_ 854 RHRDoorSts 0 "Closed" 1 "Open";
VAL_ 854 SysEOLSts 0 "EOL_Ready" 1 "EOL_Not_Ready";
VAL_ 854 WarningKeyInSts 0 "Not_active" 1 "Active";
VAL_ 854 WashLightWarningSts 0 "Not_Active" 1 "Active";
VAL_ 1132 BatteryChargeSts 15 "SNA";
VAL_ 1132 CmdIgn_FailSts 0 "Fail_Not_Present" 1 "Fail_Present" 3 "SNA";
VAL_ 1132 CmdIgnSts 0 "Initialization" 1 "IGN_LK" 3 "ACC" 4 "RUN" 5 "START" 7 "SNA";
VAL_ 1132 DriveStyleSts 0 "Normal" 1 "City" 2 "Sport_Fun" 3 "Winter_Race" 4 "Eco" 5 "TracPlus" 6 "Trekking" 7 "Auto" 8 "Snow" 9 "Sand" 10 "Mud" 11 "Rock" 12 "Race" 13 "Sand_Mud" 31 "SNA";
VAL_ 1132 ExternalTemperatureC 511 "SNA";
VAL_ 1132 ExternalTemperatureF 511 "SNA";
VAL_ 1132 ExternalTemperatureFailSts 0 "Fail_Not_Present" 1 "Fail_Present";
VAL_ 1132 Int_Relay_FailSts 0 "Fail_Not_Present" 1 "Fail_Present" 3 "SNA";
VAL_ 1132 InternalLightSts 0 "Not_Active" 1 "Active";
VAL_ 1132 RemStActvSts 0 "Remote Start Not Active" 1 "Remote Start Active";
VAL_ 1132 TurnIndicationSts 0 "Center" 1 "Right" 2 "Left" 3 "SNA";
VAL_ 1450 PreCondActvSts 0 "Precondition_Not_Active" 1 "Precondition_Active";
VAL_ 1450 RecoveryIgnOffInd 0 "MSG_DEFAULT" 1 "MSG_ACTIVE" 3 "SNA";
VAL_ 1128 InternalLightLevel2 0 "Level_1" 1 "Level_2" 2 "Level_3" 3 "Level_4" 4 "Level_5" 5 "Level_6" 6 "Level_7" 7 "Level_8" 8 "Level_9" 9 "Level_10" 10 "Level_11" 11 "Level_12" 12 "Level_13" 13 "Level_14" 14 "Level_15" 15 "Level_16";
VAL_ 988 LatAcceleration_BSM 4095 "SNA";
VAL_ 988 LatAccelerationFailSts_BSM 0 "Fail_Not_Present" 1 "Fail_Present";
VAL_ 988 LongAcceleration_BSM 4095 "SNA";
VAL_ 988 LongAccelerationFailSts_BSM 0 "Fail_Not_Present" 1 "Fail_Present";
VAL_ 988 YawRate_BSM 4095 "SNA";
VAL_ 988 YawRateFailSts_BSM 0 "Fail_Not_Present" 1 "Fail_Present";
VAL_ 990 LHF_FastPulseCounter 255 "SNA";
VAL_ 990 LHF_WheelSensorFailSts 0 "Fail_Not_Present" 1 "Fail_Present";
VAL_ 990 LHR_FastPulseCounter 255 "SNA";
VAL_ 990 LHR_WheelSensorFailSts 0 "Fail_Not_Present" 1 "Fail_Present";
VAL_ 990 RHF_FastPulseCounter 255 "SNA";
VAL_ 990 RHF_WheelSensorFailSts 0 "Fail_Not_Present" 1 "Fail_Present";
VAL_ 990 RHR_FastPulseCounter 255 "SNA";
VAL_ 990 RHR_WheelSensorFailSts 0 "Fail_Not_Present" 1 "Fail_Present";
VAL_ 994 PowertrainPrplsnActv 0 "Off" 1 "Active";
VAL_ 994 VehicleSpeedVSOSig 8191 "SNA";
VAL_ 994 VehicleSpeedVSOSigFailSts 0 "Fail_not_present" 1 "Fail_present";
VAL_ 996 ReverseGearSts 0 "Not_Inserted" 1 "Inserted" 2 "Not_Used" 3 "SNA";
VAL_ 998 AirTemp_Outsd 255 "SNA";
VAL_ 998 ShiftLeverPosition 0 "No_Selection_Active_Or_Available" 1 "P" 2 "R" 3 "N" 4 "D" 5 "L" 6 "TIP_Autostick" 7 "Plus" 8 "Minus" 9 "Sport" 10 "Not_Used" 11 "Not_Used" 12 "Not_Used" 13 "Not_Used" 14 "Not_Used" 15 "SNA";
VAL_ 1984 InflationState_LHF_Tyre 0 "Normal_Tyre_Pressure" 1 "Under_Inflated_Tyre" 2 "SignificantlyUnderInflatedTyre" 3 "Over_Inflated_Tyre" 4 "Sensor_Missing";
VAL_ 1984 InflationState_LHR_Tyre 0 "Normal_Tyre_Pressure" 1 "Under_Inflated_Tyre" 2 "SignificantlyUnderInflatedTyre" 3 "Over_Inflated_Tyre" 4 "Sensor_Missing";
VAL_ 1984 InflationState_RHF_Tyre 0 "Normal_Tyre_Pressure" 1 "Under_Inflated_Tyre" 2 "SignificantlyUnderInflatedTyre" 3 "Over_Inflated_Tyre" 4 "Sensor_Missing";
VAL_ 1984 InflationState_RHR_Tyre 0 "Normal_Tyre_Pressure" 1 "Under_Inflated_Tyre" 2 "SignificantlyUnderInflatedTyre" 3 "Over_Inflated_Tyre" 4 "Sensor_Missing";
VAL_ 1984 TyrePressureSystemFailSts 0 "Fail_Not_Present" 1 "Fail_Present";
VAL_ 1426 AEB_CHIME_TYPSts 0 "Default" 1 "Chime1" 2 "Chime2" 3 "Chime3";
VAL_ 1426 AEB_LF_CHIME_RQSts 0 "Not_Active" 1 "Active";
VAL_ 1426 AEB_RF_CHIME_RQSts 0 "Not_Active" 1 "Active";
VAL_ 1426 DDAActivationFeedback 0 "ON" 1 "OFF";
VAL_ 1426 DDAFailSts 0 "Fail_Not_Present" 1 "Fail_Present";
VAL_ 1426 WarningLevel 0 "No_Warning" 1 "Learning" 2 "Level_1" 3 "Level_2" 4 "Level_3" 5 "SysResetted" 6 "Generic_Warning";
VAL_ 1460 PowerModeSts_CStack 0 "Standard_Power" 1 "Logistic_Mode_ON" 2 "Logistic_Mode_PR" 3 "Not_Used";
VAL_ 1130 CompressorACReqSts 0 "Not_Active" 1 "Active";
VAL_ 1130 FHeatedWindowCmd 0 "Not_Active" 1 "Active";
VAL_ 1130 HVAC_Blower_Speed 0 "0% <= PWM < 20%" 1 "20% <= PWM < 30%" 2 "30% <= PWM < 40%" 3 "40% <= PWM < 50%" 4 "50% <= PWM < 55%" 5 "55% <= PWM < 60%" 6 "60% <= PWM < 65%" 7 "65% <= PWM < 70%" 8 "70% <= PWM < 75%" 9 "75% <= PWM < 80%" 10 "80% <= PWM < 85%" 11 "85% <= PWM < 90%" 12 "90% <= PWM < 95%" 13 "95% <= PWM <= 100%" 14 "Blower_shutdown" 15 "SNA";
VAL_ 1130 MaxDefrostSts 0 "OFF" 1 "ON";
VAL_ 1130 PowerModeSts_Climate 0 "Standard_Power" 1 "Logistic_Mode_On" 2 "Logistic_Mode_PR" 3 "Not_Used";
VAL_ 1130 RHeatedWindowCmd 0 "Not_Active" 1 "Active";
VAL_ 1130 StopStartClimateInfo 0 "SPST_ON" 1 "CABIN_HI" 2 "CABIN_LO" 3 "MAX_AC" 4 "FT_DEFROST" 5 "EBL" 7 "SNA";
VAL_ 1130 StopStartEnable 0 "False" 1 "True";
VAL_ 1482 HVACAC_Sts 0 "OFF" 1 "ON" 2 "BLINK" 3 "SNA";
VAL_ 1482 HVACAuto_Sts 0 "OFF" 1 "ON" 2 "BLINK" 3 "SNA";
VAL_ 1482 HVACControl_Sts 0 "HVAC_CTRL_OFF" 1 "Blw_AUTO_Mode_AUTO" 2 "Blw_AUTO_Mode_MAN" 3 "Blw_MAN_Mode_AUTO" 4 "Blw_MAN_Mode_MAN" 7 "SNA";
VAL_ 1482 HVACMaxAC_Sts 0 "OFF" 1 "ON" 2 "BLINK" 3 "SNA";
VAL_ 1482 HVACMode_Sts 0 "Defrost" 1 "Mix_Defrost" 2 "Mix" 3 "Floor_Mix" 4 "Floor" 5 "BiLvl_Floor" 6 "BiLvl" 7 "Panel_BiLvl" 8 "Panel" 9 "Panel_HiLvl" 10 "HiLvl" 11 "HILvl_Defrost" 12 "Trilevel" 15 "SNA";
VAL_ 1482 HVACRearDef_Sts 0 "OFF" 1 "ON" 2 "BLINK" 3 "SNA";
VAL_ 1482 HVACRecirc_Sts 0 "OFF" 1 "ON" 2 "BLINK" 3 "SNA";
VAL_ 1483 HVACDRVTemp 0 "Initialization" 1 "Full Cold" 62 "Full Hot" 63 "SNA";
VAL_ 1904 DEFROST_SEL 0 "Not_Active" 1 "Active";
VAL_ 1904 DRV_TEMP_DR_POS 127 "SNA";
VAL_ 1904 EvapTempTar 255 "SNA";
VAL_ 1904 HtrCorTmp_InTgt 255 "SNA";
VAL_ 1904 HVAC_Blwr_Perct 127 "SNA";
VAL_ 1904 VEH_INT_TEMP 65535 "SNA";
VAL_ 1448 AHP_EnblReq 0 "False" 1 "True" 2 "Not_Used" 3 "SNA";
VAL_ 1448 AirHtwPwrTgt 255 "SNA";
VAL_ 1448 EVAP_TEMP_P1C 2047 "SNA";
VAL_ 1448 PreCondCabinSts 0 "Off" 1 "On" 2 "SPR" 3 "SNA";
VAL_ 1169 FL_HS_STATFailSts 0 "Fail_Not_Present" 1 "Fail_Present";
VAL_ 1169 FL_HS_STATSts 0 "Heated_seat_off" 1 "Heated_seat_low" 2 "Heated_seat_medium" 3 "Heated_seat_high";
VAL_ 1169 FR_HS_STATFailSts 0 "Fail_Not_Present" 1 "Fail_Present";
VAL_ 1169 FR_HS_STATSts 0 "Heated_seat_off" 1 "Heated_seat_low" 2 "Heated_seat_medium" 3 "Heated_seat_high";
VAL_ 1899 AirHtrPwrCnsAct 255 "SNA";
VAL_ 1899 CompStat 0 "NormalOperation" 1 "DegradedOperation" 2 "Inoperative" 3 "Reserved1" 4 "Reserved2" 5 "Reserved3" 6 "Reserved4" 15 "SNA";
VAL_ 1899 FRfShVlvSts 0 "Open" 1 "Closed";
VAL_ 1899 HVBatCritCondT 0 "False" 1 "True";
VAL_ 1899 R134a_PressSts 511 "SNA";
VAL_ 1899 TurtleModeSts 0 "No_Turtle_Mode" 1 "Turtle_Level1" 2 "Turtle_Level2" 3 "Turtle_Level3" 4 "Turtle_Level4" 7 "SNA";
VAL_ 1512 AirHtrCoreTemp 255 "SNA";
VAL_ 1512 AirHtrPCBTemp 255 "SNA";
VAL_ 1512 Cabin_Condition_Sts 0 "Default" 1 "Rejected_not_plugged_in" 2 "Stopped_due_to_SOC" 3 "On" 4 "Cabin_Set_Pt_Reached" 5 "Off" 6 "Failed_Other_Than_HV_Bat_Temp" 7 "Failed_HV_Bat_Temp" 8 "Bat_Cond _complete" 9 "Bat_Cond_Stp_Bfr_Cmpl_HVBat_NOK" 15 "SNA";
VAL_ 1512 ChargingLevel 0 "Default_NoLevel" 1 "Level_1_AC" 2 "Level_2_AC" 3 "Level_3_AC" 4 "Level_1_DC" 5 "Level_2_DC" 6 "PlugInNotDet" 7 "PPI_1_No_Drive" 8 "PPI_2_OK_Drive" 15 "SNA";
VAL_ 1512 ChargingSysSts 0 "NotCharging" 1 "Charging" 2 "ChargeInterrupted" 3 "ChargeComplete" 7 "SNA";
VAL_ 1512 ChrgSysFault 0 "Not_Faulted" 1 "Faulted";
VAL_ 1512 HVBatSOCV_HCP 0 "Valid" 1 "Not_Valid";
VAL_ 1512 SchCond_Time_Till_Dep 127 "SNA";
VAL_ 1512 Service_Battery_Recharge_FailSts 0 "Recharge_Fail" 1 "Recharge_Not_In_Fail";
VAL_ 1462 SWSError 0 "No_Errors" 1 "Error_Present";
VAL_ 1268 FrontSensorSts 0 "Active" 1 "Not_Active_blocked" 2 "Not_Active_failure" 3 "SNA";
VAL_ 1268 LateralSensorSts 0 "Active" 1 "Not_Active_blocked" 2 "Not_Active_failure" 3 "SNA";
VAL_ 1268 PAMAboveSpeed 0 "False" 1 "True";
VAL_ 1268 PAMSystemFault 0 "False" 1 "Temporary_Failure" 2 "External_Failure" 3 "System_Failure";
VAL_ 1268 PAMSystemSts 0 "OFF" 1 "ON_Active" 2 "ON_Inactive" 3 "ON_Disabled";
VAL_ 1268 RearSensorSts 0 "Active" 1 "Not_Active_blocked" 2 "Not_Active_failure" 3 "SNA";
VAL_ 1268 SDWFailSts 0 "Fail_Not_Present" 1 "Fail_Present";
VAL_ 1458 AudioRequest 0 "Not_Active" 1 "Active";
VAL_ 1458 BUBFailSts 0 "No_Fail" 1 "BUB_Maintainance_Fail" 2 "BUB_Down_Fail";
VAL_ 1458 CallSts 0 "Call_Not_Available" 1 "Idle" 2 "Dialing" 3 "Attempt_Fail" 4 "Call_Established" 5 "Call_Fail" 6 "Call_Ended" 7 "Callback_Wait" 8 "Incoming_Call" 9 "Loading" 10 "Menu" 11 "Auto_Bcall_Loading" 15 "SNA";
VAL_ 1458 CallType 0 "No_Call" 1 "E_Call" 2 "ACN_Call" 3 "B_Call" 4 "B1_Call" 5 "B2_Call" 6 "B3_Call" 7 "SNA";
VAL_ 1458 GPSFailSts 0 "Fail_Not_Present" 1 "Fail_Present";
VAL_ 1458 IVA 0 "No_Call" 1 "Call" 3 "SNA";
VAL_ 1458 LTESts 0 "No_Network" 1 "2G" 2 "3G" 3 "4G" 4 "E" 5 "H_Plus" 6 "Unknown";
VAL_ 1458 MuteRequest 0 "Not_Active" 1 "Active";
VAL_ 1458 NetConnection 0 "Not_Connected" 1 "Connected" 2 "Connection_Ongoing" 3 "Connection_Failed";
VAL_ 1458 PowerModeSts_TBM 0 "Standard_Power" 1 "Logistic_Mode_On" 2 "Logistic_Mode_PR" 3 "Not_Used";
VAL_ 1458 Provisioning 0 "Call_Not_Enabled" 1 "Call_Enabled" 7 "SNA";
VAL_ 1458 SignalStrength 0 "0" 1 "1" 2 "2" 3 "3" 4 "4" 5 "5" 7 "SNA";
VAL_ 1458 SOSCallStatus 0 "No_Indication" 1 "Sos_Battery_Fail" 2 "Sos_Fail" 3 "Sos_Call_Ended" 4 "Sos_Call_Establish" 5 "Starting_SOS_Fail" 6 "Incoming_SOS_Call" 7 "Starting_SOS_1_Phase" 8 "Starting_SOS_2_Phase" 9 "Starting_SOS_Auto" 10 "SOS_Low_Battery";
VAL_ 1458 SOSCallType 0 "Initialization" 1 "No_active_SOS_call" 2 "Manual_SOS_call" 3 "Automatic_SOS_call" 4 "Callback_SOS_call" 5 "Callback_wait" 7 "SNA";
VAL_ 1458 SOSFailSts 0 "Fail_Not_Present" 1 "Fail_Present";
VAL_ 1458 SystemFailSts 0 "Fail_Not_Present" 1 "Fail_Present";
VAL_ 1458 WiFiFailSts 0 "Fail_Not_Present" 1 "Fail_Present";
VAL_ 1458 WiFiSts 0 "OFF" 1 "ON" 3 "SNA";
VAL_ 1470 AntitheftSts 0 "Not_Successfully" 1 "In_Progress" 2 "Successfully";
VAL_ 1470 AUDIOSts_Telematic 0 "Initialization" 1 "Available" 2 "Not_Available" 3 "SNA";
VAL_ 1470 CurrentSource 0 "AM_Selected" 1 "FM_Selected" 2 "MW_Selected" 3 "LW_Selected" 4 "Internal_DISC_Selected" 5 "Internal_HDD_Selected" 6 "Internal_AUX_Selected" 7 "Internal_Slot_Media_Slctd" 8 "DTV_Selected" 9 "SDAR1_Selected" 10 "SW_Selected" 11 "VES_DVD1_Selected" 12 "MFLO_Selected" 13 "VES_AUX1_Selected" 14  "VES_AUX2_Selected" 15 "SDARV_Selected" 16 "HFM_Personal_HU_Selected" 18 "DAB_Selected" 19 "TGW_USB1_Selected" 20 "VES_SEL" 21 "USB3_SEL" 22 "TMM_SEL" 23 "HFM_BlueTooth_1_Selected" 25 "USB2_SEL" 26 "APPS_SEL" 27 "AUD_MUTED" 28 "IR_Off_Selected" 29 "HU_Off " 30 "HU_Locked" 31 "SNA";
VAL_ 1470 HFPSts 0 "Not_Active" 1 "Pending" 2 "Active";
VAL_ 1470 MicrophoneFailSts 0 "Fail_Not_Present" 1 "Fail_Present";
VAL_ 1470 MuteSts 0 "Not_Muted" 1 "Muted";
VAL_ 1470 PowerModeSts_Telematic 0 "Standard_Power" 1 "Logistic_Mode_ON" 2 "Logistic_Mode_PR" 3 "Not_Used";
VAL_ 1470 PowerSts_Telematic 0 "Sleep" 1 "Standby" 2 "Timed" 3 "Idle" 4 "Full_Operation" 5 "Logistic_On" 6 "Bench" 7 "Partial_Operation";
VAL_ 1470 VolumeSts 127 "SNA";
VAL_ 1470 VolumeUnit 0 "Int" 1 "Percent";
VAL_ 1470 VRSts 0 "Not_Active" 1 "Active";
VAL_ 1206 Ubss_Blind_RQSts 0 "No_Sensor_Blocked_Request" 1 "Sensor_Blocked_Request";
VAL_ 1206 Ubss_Cfg_StatSts 0 "Not_enabled" 1 "Enabled_for_LED" 2 "Enabled_for_LED_and_Chime" 3 "SNA";
VAL_ 1206 Ubss_LF_Chime_RQSts 0 "No_left_frnt_chime_on_req" 1 "Left_front_chime_on_req";
VAL_ 1206 Ubss_LR_Chime_RQSts 0 "No_left_rear_chime_on_req" 1 "Left_rear_chime_on_req";
VAL_ 1206 Ubss_LT_Chime_TypeSts 0 "None" 1 "Type1" 2 "Type2" 3 "Type3" 4 "Type4" 5 "Type5" 6 "Type6" 7 "Type7" 8 "Type8" 9 "Type9" 10 "Type10" 11 "Type11" 12 "Type12" 13 "Type13" 14 "Type14" 15 "SNA";
VAL_ 1206 Ubss_OPR_StatSts 0 "No_Operational_Failure" 1 "OperatFailure_SystemUnavailable";
VAL_ 1206 Ubss_RF_Chime_RQSts 0 "No_rght_frnt_chime_on_req" 1 "Right_front_chime_on_req";
VAL_ 1206 Ubss_RR_Chime_RQSts 0 "No_rght_rear_chime_on_req" 1 "Right_rear_chime_on_req";
VAL_ 1206 Ubss_RT_Chime_TypeSts 0 "None" 1 "Type1" 2 "Type2" 3 "Type3" 4 "Type4" 5 "Type5" 6 "Type6" 7 "Type7" 8 "Type8" 9 "Type9" 10 "Type10" 11 "Type11" 12 "Type12" 13 "Type13" 14 "Type14" 15 "SNA";
VAL_ 1206 Ubss_SRV_RQSts 0 "No_Service_Request" 1 "Service_Request";
VAL_ 1206 Ubss_Sts 0 "Initialization" 1 "System_Off" 2 "Bsd_Active" 3 "Standby" 4 "Disabled" 5 "Unavailable" 7 "SNA";
VAL_ 1206 UbssLtLedFaultSts 0 "No_Fault" 1 "Short_to_Ground" 2 "Short_to_Batt" 3 "Open_Circuit";
VAL_ 1206 UbssLtWrnSts 0 "Not_Present" 1 "Present";
VAL_ 1206 UbssRtLedFaultSts 0 "No_Fault" 1 "Short_to_Ground" 2 "Short_to_Batt" 3 "Open_Circuit";
VAL_ 1206 UbssRtWrnSts 0 "Not_Present" 1 "Present";
VAL_ 750 Command_01Sts 0 "Not_Pressed" 1 "Pressed" 3 "SNA";
VAL_ 750 Command_02Sts 0 "Not_Pressed" 1 "Pressed" 3 "SNA";
VAL_ 750 Command_03Sts 0 "Not_Pressed" 1 "Pressed" 3 "SNA";
VAL_ 750 Command_04Sts 0 "Not_Pressed" 1 "Pressed" 3 "SNA";
VAL_ 750 Command_05Sts 0 "Not_Pressed" 1 "Pressed" 3 "SNA";
VAL_ 750 Command_06Sts 0 "Not_Pressed" 1 "Pressed" 3 "SNA";
VAL_ 750 Command_07Sts 0 "Not_Pressed" 1 "Pressed" 3 "SNA";
VAL_ 750 Command_08Sts 0 "Not_Pressed" 1 "Pressed" 3 "SNA";
VAL_ 750 Command_09Sts 0 "Not_Pressed" 1 "Pressed" 3 "SNA";
VAL_ 750 Command_10Sts 0 "Not_Pressed" 1 "Pressed" 3 "SNA";
VAL_ 750 Command_11Sts 0 "Not_Pressed" 1 "Pressed" 3 "SNA";
VAL_ 750 Command_12Sts 0 "Not_Pressed" 1 "Pressed" 3 "SNA";
VAL_ 750 Command_13Sts 0 "Not_Pressed" 1 "Pressed" 3 "SNA";
VAL_ 750 Command_14Sts 0 "Not_Pressed" 1 "Pressed" 3 "SNA";
VAL_ 750 Command_15Sts 0 "Not_Pressed" 1 "Pressed" 3 "SNA";
VAL_ 178 ChargeNow 0 "No_Charge" 1 "Charge_Now";
VAL_ 172 Batt_CabinPriority1 0 "Checkbox Unselected" 1 "Checkbox Selected";
VAL_ 172 ChargeUntilFull1 0 "Charge Until Full Not selected" 1 "Charge Until Full";
VAL_ 172 Do_Not_Repeat1 0 "Repeat" 1 "Do Not Repeat";
VAL_ 172 Enable_Schedule1 0 "Disable schedule1" 1 "Enable schedule1";
VAL_ 172 End_Time_Hr1 31 "SNA";
VAL_ 172 End_Time_Min1 15 "SNA";
VAL_ 172 Schedule_Day1 0 "No Selection" 1 "M" 2 "T" 3 "TM" 4 "W" 5 "WM" 6 "WT" 7 "WTM" 8 "Th" 9 "ThM" 10 "ThT" 11 "ThTM" 12 "ThW" 13 "ThWM" 14 "ThWT" 15 "ThWTM" 16 "F" 17 "FM" 18 "FT" 19 "FTM" 20 "FW" 21 "FWM" 22 "FWT" 23 "FWTM" 24 "FTh" 25 "FThM" 26 "FThT" 27 "FThTM" 28 "FThW" 29 "FThWM" 30 "FThWT" 31 "FThWTM" 32 "S" 33 "SM" 34 "ST" 35 "STM" 36 "SW" 37 "SWM" 38 "SWT" 39 "SWTM" 40 "STh" 41 "SThM" 42 "SThT" 43 "SThTM" 44 "SThW" 45 "SThWM" 46 "SThWT" 47 "SThWTM" 48 "SF" 49 "SFM" 50 "SFT" 51 "SFTM" 52 "SFW" 53 "SFWM" 54 "SFWT" 55 "SFWTM" 56 "SFTh" 57 "SFThM" 58 "SFThT" 59 "SFThTM" 60 "SFThW" 61 "SFThWM" 62 "SFThWT" 63 "SFThWTM" 64 "Sa" 65 "SaM" 66 "SaT" 67 "SaTM" 68 "SaW" 69 "SaWM" 70 "SaWT" 71 "SaWTM" 72 "SaTh" 73 "SaThM" 74 "SaThT" 75 "SaThTM" 76 "SaThW" 77 "SaThWM" 78 "SaThWT" 79 "SaThWTM" 80 "SaF" 81 "SaFM" 82 "SaFT" 83 "SaFTM" 84 "SaFW" 85 "SaFWM" 86 "SaFWT" 87 "SaFWTM" 88 "SaFTh" 89 "SaFThM" 90 "SaFThT" 91 "SaFThTM" 92 "SaFThW" 93 "SaFThWM" 94 "SaFThWT" 95 "SaFThWTM" 96 "SaS" 97 "SaSM" 98 "SaST" 99 "SaSTM" 100 "SaSW" 101 "SaSWM" 102 "SaSWT" 103 "SaSWTM" 104 "SaSTh" 105 "SaSThM" 106 "SaSThT" 107 "SaSThTM" 108 "SaSThW" 109 "SaSThWM" 110 "SaSThWT" 111 "SaSThWTM" 112 "SaSF" 113 "SaSFM" 114 "SaSFT" 115 "SaSFTM" 116 "SaSFW" 117 "SaSFWM" 118 "SaSFWT" 119 "SaSFWTM" 120 "SaSFTh" 121 "SaSFThM" 122 "SaSFThT" 123 "SaSFThTM" 124 "SaSFThW" 125 "SaSFThWM" 126 "SaSFThWT" 127 "SaSFThWTM" 255 "SNA";
VAL_ 172 Schedule_Type1 0 "No Selection" 1 "Departure Time" 2 "Charge Interval" 3 "SNA";
VAL_ 172 Start_Time_Hr1 31 "SNA";
VAL_ 172 Start_Time_Min1 15 "SNA";
VAL_ 172 Submit_Schedule1 0 "No Change" 1 "Change in schedule 1";
VAL_ 174 Batt_CabinPriority2 0 "Checkbox Unselected" 1 "Checkbox Selected";
VAL_ 174 ChargeUntilFull2 0 "Charge Until Full Not selected" 1 "Charge Until Full";
VAL_ 174 Do_Not_Repeat2 0 "Repeat" 1 "Do Not Repeat";
VAL_ 174 Enable_Schedule2 0 "Disable schedule2" 1 "Enable schedule2";
VAL_ 174 End_Time_Hr2 31 "SNA";
VAL_ 174 End_Time_Min2 15 "SNA";
VAL_ 174 Schedule_Day2 0 "No Selection" 1 "M" 2 "T" 3 "TM" 4 "W" 5 "WM" 6 "WT" 7 "WTM" 8 "Th" 9 "ThM" 10 "ThT" 11 "ThTM" 12 "ThW" 13 "ThWM" 14 "ThWT" 15 "ThWTM" 16 "F" 17 "FM" 18 "FT" 19 "FTM" 20 "FW" 21 "FWM" 22 "FWT" 23 "FWTM" 24 "FTh" 25 "FThM" 26 "FThT" 27 "FThTM" 28 "FThW" 29 "FThWM" 30 "FThWT" 31 "FThWTM" 32 "S" 33 "SM" 34 "ST" 35 "STM" 36 "SW" 37 "SWM" 38 "SWT" 39 "SWTM" 40 "STh" 41 "SThM" 42 "SThT" 43 "SThTM" 44 "SThW" 45 "SThWM" 46 "SThWT" 47 "SThWTM" 48 "SF" 49 "SFM" 50 "SFT" 51 "SFTM" 52 "SFW" 53 "SFWM" 54 "SFWT" 55 "SFWTM" 56 "SFTh" 57 "SFThM" 58 "SFThT" 59 "SFThTM" 60 "SFThW" 61 "SFThWM" 62 "SFThWT" 63 "SFThWTM" 64 "Sa" 65 "SaM" 66 "SaT" 67 "SaTM" 68 "SaW" 69 "SaWM" 70 "SaWT" 71 "SaWTM" 72 "SaTh" 73 "SaThM" 74 "SaThT" 75 "SaThTM" 76 "SaThW" 77 "SaThWM" 78 "SaThWT" 79 "SaThWTM" 80 "SaF" 81 "SaFM" 82 "SaFT" 83 "SaFTM" 84 "SaFW" 85 "SaFWM" 86 "SaFWT" 87 "SaFWTM" 88 "SaFTh" 89 "SaFThM" 90 "SaFThT" 91 "SaFThTM" 92 "SaFThW" 93 "SaFThWM" 94 "SaFThWT" 95 "SaFThWTM" 96 "SaS" 97 "SaSM" 98 "SaST" 99 "SaSTM" 100 "SaSW" 101 "SaSWM" 102 "SaSWT" 103 "SaSWTM" 104 "SaSTh" 105 "SaSThM" 106 "SaSThT" 107 "SaSThTM" 108 "SaSThW" 109 "SaSThWM" 110 "SaSThWT" 111 "SaSThWTM" 112 "SaSF" 113 "SaSFM" 114 "SaSFT" 115 "SaSFTM" 116 "SaSFW" 117 "SaSFWM" 118 "SaSFWT" 119 "SaSFWTM" 120 "SaSFTh" 121 "SaSFThM" 122 "SaSFThT" 123 "SaSFThTM" 124 "SaSFThW" 125 "SaSFThWM" 126 "SaSFThWT" 127 "SaSFThWTM" 255 "SNA";
VAL_ 174 Schedule_Type2 0 "No Selection" 1 "Departure Time" 2 "Charge Interval" 3 "SNA";
VAL_ 174 Start_Time_Hr2 31 "SNA";
VAL_ 174 Start_Time_Min2 15 "SNA";
VAL_ 174 Submit_Schedule2 0 "No Change" 1 "Change in schedule 2";
VAL_ 176 Batt_CabinPriority3 0 "Checkbox Unselected" 1 "Checkbox Selected";
VAL_ 176 ChargeUntilFull3 0 "Charge Until Full Not selected" 1 "Charge Until Full";
VAL_ 176 Do_Not_Repeat3 0 "Repeat" 1 "Do Not Repeat";
VAL_ 176 Enable_Schedule3 0 "Disable schedule3" 1 "Enable schedule3";
VAL_ 176 End_Time_Hr3 31 "SNA";
VAL_ 176 End_Time_Min3 15 "SNA";
VAL_ 176 Schedule_Day3 0 "No Selection" 1 "M" 2 "T" 3 "TM" 4 "W" 5 "WM" 6 "WT" 7 "WTM" 8 "Th" 9 "ThM" 10 "ThT" 11 "ThTM" 12 "ThW" 13 "ThWM" 14 "ThWT" 15 "ThWTM" 16 "F" 17 "FM" 18 "FT" 19 "FTM" 20 "FW" 21 "FWM" 22 "FWT" 23 "FWTM" 24 "FTh" 25 "FThM" 26 "FThT" 27 "FThTM" 28 "FThW" 29 "FThWM" 30 "FThWT" 31 "FThWTM" 32 "S" 33 "SM" 34 "ST" 35 "STM" 36 "SW" 37 "SWM" 38 "SWT" 39 "SWTM" 40 "STh" 41 "SThM" 42 "SThT" 43 "SThTM" 44 "SThW" 45 "SThWM" 46 "SThWT" 47 "SThWTM" 48 "SF" 49 "SFM" 50 "SFT" 51 "SFTM" 52 "SFW" 53 "SFWM" 54 "SFWT" 55 "SFWTM" 56 "SFTh" 57 "SFThM" 58 "SFThT" 59 "SFThTM" 60 "SFThW" 61 "SFThWM" 62 "SFThWT" 63 "SFThWTM" 64 "Sa" 65 "SaM" 66 "SaT" 67 "SaTM" 68 "SaW" 69 "SaWM" 70 "SaWT" 71 "SaWTM" 72 "SaTh" 73 "SaThM" 74 "SaThT" 75 "SaThTM" 76 "SaThW" 77 "SaThWM" 78 "SaThWT" 79 "SaThWTM" 80 "SaF" 81 "SaFM" 82 "SaFT" 83 "SaFTM" 84 "SaFW" 85 "SaFWM" 86 "SaFWT" 87 "SaFWTM" 88 "SaFTh" 89 "SaFThM" 90 "SaFThT" 91 "SaFThTM" 92 "SaFThW" 93 "SaFThWM" 94 "SaFThWT" 95 "SaFThWTM" 96 "SaS" 97 "SaSM" 98 "SaST" 99 "SaSTM" 100 "SaSW" 101 "SaSWM" 102 "SaSWT" 103 "SaSWTM" 104 "SaSTh" 105 "SaSThM" 106 "SaSThT" 107 "SaSThTM" 108 "SaSThW" 109 "SaSThWM" 110 "SaSThWT" 111 "SaSThWTM" 112 "SaSF" 113 "SaSFM" 114 "SaSFT" 115 "SaSFTM" 116 "SaSFW" 117 "SaSFWM" 118 "SaSFWT" 119 "SaSFWTM" 120 "SaSFTh" 121 "SaSFThM" 122 "SaSFThT" 123 "SaSFThTM" 124 "SaSFThW" 125 "SaSFThWM" 126 "SaSFThWT" 127 "SaSFThWTM" 255 "SNA";
VAL_ 176 Schedule_Type3 0 "No Selection" 1 "Departure Time" 2 "Charge Interval" 3 "SNA";
VAL_ 176 Start_Time_Hr3 31 "SNA";
VAL_ 176 Start_Time_Min3 15 "SNA";
VAL_ 176 Submit_Schedule3 0 "No Change" 1 "Change in schedule 3";
VAL_ 1480 FL_HS_Cmd_Tlm_Req 0 "Not_Pressed" 1 "Pressed";
VAL_ 1480 FR_HS_Cmd_Tlm_Req 0 "Not_Pressed" 1 "Pressed";
VAL_ 1480 HVAC_MAXDef_Req 0 "Not_Pressed" 1 "Pressed";
VAL_ 1480 HVACAC_Req 0 "Not_Pressed" 1 "Pressed";
VAL_ 1480 HVACAuto_Req 0 "Not_Pressed" 1 "Pressed";
VAL_ 1480 HVACFrontDef_Req 0 "Not_Pressed" 1 "Pressed";
VAL_ 1480 HVACFunc_Req 0 "No Function" 1 "FTDRVTemp_Inc" 2 "FTDRVTemp_Dec" 3 "FTDRVTemp_JUMP" 4 "FTPSNTemp_Inc" 5 "FTPSNTemp_Dec" 6 "FTPSNTemp_JUMP" 7 "RRTemp_DRV_Inc" 8 "RRTemp_DRV_Dec" 9 "RRTemp_DRV_JUMP" 10 "FTBlw_Inc" 11 "FTBlw_Dec" 12 "FTBlw_JUMP" 13 "RRBlw_Inc" 14 "RRBlw_Dec" 15 "RRBlw_JUMP" 16 "RRTemp_PAS_Inc" 17 "RRTemp_PAS_Dec" 18 "RRTemp_PAS_JUMP" 31 "SNA";
VAL_ 1480 HVACMaxAC_Req 0 "Not_Pressed" 1 "Pressed";
VAL_ 1480 HVACMode_Req 0 "No Change" 1 "Defrost" 2 "Mix_Defrost" 3 "Mix" 4 "Floor_Mix" 5 "Floor" 6 "BiLvl_Floor" 7 "BiLvl" 8 "Panel_BiLvl" 9 "Panel" 10 "Panel_HiLvl" 11 "HiLvl" 12 "HILvl_Defrost" 13 "Trilevel" 15 "SNA";
VAL_ 1480 HVACPower_Req 0 "Not_Pressed" 1 "Pressed";
VAL_ 1480 HVACRearDef_Req 0 "Not_Pressed" 1 "Pressed";
VAL_ 1480 HVACRecirc_Req 0 "Not_Pressed" 1 "Pressed";
VAL_ 1052 Radio_btn0_Req 0 "Not_Pressed" 1 "Pressed";
VAL_ 1052 Radio_btn1_Req 0 "Not_Pressed" 1 "Pressed";
VAL_ 1052 Radio_Knob1_DIR_Req 0 "Knob_no_change" 1 "Knob_increment" 2 "Knob_decrement" 3 "Knob_enter";
VAL_ 144 FrameNumber 0 "Frame1" 1 "Frame2" 2 "Frame3" 3 "Frame4" 4 "Frame5" 5 "Frame6" 6 "Frame7" 7 "Frame8" 8 "Frame9" 9 "Frame10" 10 "Frame11" 11 "Frame12" 12 "Frame13" 13 "Frame14" 14 "Frame15" 15 "Frame16" 16 "Frame17" 17 "Frame18" 18 "Frame19" 19 "Frame20" 20 "Frame21" 21 "Frame22" 22 "Frame23" 23 "Frame24" 24 "Frame25" 25 "Frame26" 26 "Frame27" 27 "Frame28" 28 "Frame29" 29 "Frame30" 30 "Frame31" 31 "Frame32";
VAL_ 144 TotalFrameNumber 0 "Frame1" 1 "Frame2" 2 "Frame3" 3 "Frame4" 4 "Frame5" 5 "Frame6" 6 "Frame7" 7 "Frame8" 8 "Frame9" 9 "Frame10" 10 "Frame11" 11 "Frame12" 12 "Frame13" 13 "Frame14" 14 "Frame15" 15 "Frame16" 16 "Frame17" 17 "Frame18" 18 "Frame19" 19 "Frame20" 20 "Frame21" 21 "Frame22" 22 "Frame23" 23 "Frame24" 24 "Frame25" 25 "Frame26" 26 "Frame27" 27 "Frame28" 28 "Frame29" 29 "Frame30" 30 "Frame31" 31 "Frame32";
VAL_ 1502 TGW_PT_CAB_DRSts 1 "TGW_pntr_for_cabin";
VAL_ 1502 TGW_RQ1Sts 255 "SNA";
VAL_ 1500 TGW_DISP_STATSts 0 "Display_off" 1 "Display_closed" 2 "Normal_mode" 3 "DVD_menu" 4 "DVD_Setup" 5 "DVD_display" 6 "Mode_select_display" 7 "Rear_Camera_Display" 8 "On_blanked_screen" 9 "Splashscreen_Display" 10 "Rear Entertainment HMI" 11 "Rear Entertainment Full Screen Video " 12 "DTV Program Display" 13 "DTV fullscreen Video Display" 14 "DTV Camera Video Display" 15 "SNA";
VAL_ 126 CurrTimeMin 255 "SNA";
VAL_ 126 CurrTimeSec 63 "SNA";
VAL_ 126 DLS 0 "NoInfo" 1 "Artist" 2 "Composer" 3 "Conductor" 4 "Band" 5 "Comment" 6 "Title" 7 "Composition" 8 "Movement" 15 "SNA";
VAL_ 126 PresetNumber 0 "NoPreset" 1 "Preset1" 2 "Preset2" 3 "Preset3" 4 "Preset4" 5 "Preset5" 6 "Preset6" 7 "Preset7" 8 "Preset8" 9 "Preset9" 10 "Preset10" 11 "Preset11" 12 "Preset12" 13 "Preset13" 14 "Preset14" 15 "Preset15" 16 "Preset16" 17 "Preset17" 18 "Preset18" 19 "Preset19" 20 "Preset20" 21 "Preset21" 22 "Preset22" 23 "Preset23" 24 "Preset24" 25 "Preset25" 26 "Preset26" 27 "Preset27" 28 "Preset28" 29 "Preset29" 30 "Preset30" 31 "SNA";
VAL_ 126 Presets 0 "No" 1 "Yes";
VAL_ 126 ProgressBarPerc 127 "SNA";
VAL_ 126 PTY 0 "No_Program" 1 "News" 2 "Current_affairs" 3 "Information" 4 "Sports" 5 "Education" 6 "Drama" 7 "Culture" 8 "Science" 9 "Varied" 10 "Pop_music" 11 "Rock_music" 12 "Easy_listening" 13 "Light_classical" 14 "Serious_classical" 15 "Other_music" 16 "Weather" 17 "Finance" 18 "Childrens_programs" 19 "Social_affairs" 20 "Religion" 21 "Phone_in" 22 "Travel" 23 "Leisure" 24 "Jazz_music" 25 "Country_music" 26 "National_music" 27 "Oldies_music" 28 "Folk_music" 29 "Documentary" 30 "Alarm_test" 31 "Alarm";
VAL_ 126 RadioText 0 "NoInfo" 1 "Artist" 2 "Composer" 3 "Conductor" 4 "Band" 5 "Comment" 6 "Title" 7 "Composition" 8 "Movement" 15 "SNA";
VAL_ 126 TotDurMin 255 "SNA";
VAL_ 126 TotDurSec 63 "SNA";
VAL_ 126 TrafficAnnouncement 0 "NoInfo" 1 "Disabled" 2 "Enabled" 3 "Active";
VAL_ 136 LastAnnouncement 0 "Not_Last" 1 "Last";
VAL_ 136 ResolutionDistToTurn 0 "One" 1 "ZeroPointOne" 2 "ZeroPointZeroOne";
VAL_ 136 Unit 0 "ClearUnit" 1 "Kilometer" 2 "Meter" 3 "Mile" 4 "Feet" 5 "Yard" 6 "SNA";
VAL_ 124 BatteryLevel 127 "SNA";
VAL_ 124 ConnectedPhoneID 7 "SNA";
VAL_ 124 IsFavorite 0 "No" 1 "Yes";
VAL_ 124 NetworkID 0 "None" 1 "H" 2 "3G" 3 "3.5G" 4 "4G" 5 "4.5G" 6 "5G" 7 "SNA";
VAL_ 124 PowerSignal 127 "SNA";
VAL_ 170 ClearPersonalDataReq 0 "Not_Active" 1 "Active";
VAL_ 170 PrivacyModeReq 0 "Not_Active" 1 "Active";
VAL_ 170 RestoreAppReq 0 "Not_Active" 1 "Active";
VAL_ 170 RestoreDefaultSettingReq 0 "Not_Active" 1 "Active";
VAL_ 158 AutoHighBeamEnable_Req 0 "Not_Enable" 1 "Enable";
VAL_ 158 AutoParkBrake_Req 0 "On" 1 "Off";
VAL_ 158 BSDEnable_Req 0 "Not_Enable" 1 "Enable_LED" 2 "Enable_ LED_Chime";
VAL_ 158 CorneringEnable_Req 0 "True" 1 "False";
VAL_ 158 DistanceUnit_Req 0 "km" 1 "miles";
VAL_ 158 DRLEnable_Req 0 "True" 1 "False";
VAL_ 158 ExternalLightSensorLevel_Req 0 "Level_3" 1 "Level_2" 2 "Level_1" 3 "Level_0";
VAL_ 158 HourMode_Req 0 "0_24_h" 1 "0_12_h";
VAL_ 158 LanguageSelection_Req 0 "Italian" 1 "Deutsch" 2 "English" 3 "Espanol" 4 "Francais" 5 "Portugues" 6 "Polish" 7 "Dutch" 8 "Brazilian" 9 "Turkish" 10 "Mexican" 11 "English_US" 12 "Canadian" 13 "Russian" 14 "Chinese" 15 "Japanese" 16 "Korean" 17 "Arabic" 18 "Czech" 19 "Slovakian" 20 "Hungarian" 21 "Hindi";
VAL_ 158 PamAlertMode_Req 0 "Off" 1 "Sound" 2 "Sound_Display";
VAL_ 158 PamChimeVolumeFront_Req 0 "Low" 1 "Medium" 2 "High";
VAL_ 158 PamChimeVolumeRear_Req 0 "Low" 1 "Medium" 2 "High";
VAL_ 158 PassiveEntry_Req 0 "On" 1 "Off";
VAL_ 158 RainSensorLevel_Req 0 "Not_Enable" 1 "Enable";
VAL_ 158 RemoteDoorUnlock_Req 0 "Driver" 1 "All";
VAL_ 158 Sdw_Req 0 "Off" 1 "Sound" 2 "Sound_Display";
VAL_ 158 SoundHornLock_Req 0 "Off" 1 "1st Press" 2 "2nd Press";
VAL_ 158 SoundHornRemoteStart_Req 0 "On" 1 "Off";
VAL_ 158 SpeedLockDoorEnable_Req 0 "Not_Enable" 1 "Enable";
VAL_ 158 TemperatureUnit_Req 0 "°C" 1 "°F";
VAL_ 162 AutoUnlockDoorExit_Req 0 "Not_Enable" 1 "Enable";
VAL_ 162 EPB_MaintenanceMode_Req 0 "Off" 1 "On";
VAL_ 162 EV_ConsumptionUnit_Req 0 "Km_Per_KWh" 1 "KWh_Per_100Km" 2 "Miles_Per_KWh" 3 "KWh_Per_Miles" 4 "MPGe";
VAL_ 162 FlashLightWLock_Req 0 "Off" 1 "On";
VAL_ 162 FSFCWPlusActivationMode_Req 0 "Near" 1 "Med" 2 "Far";
VAL_ 162 FSFCWPlusSetting_Req 0 "Off" 1 "Audio" 2 "Brake" 3 "Audio_Brake" 4 "Not_Request";
VAL_ 162 HeadlightsOffDelay_Req 0 "0sec" 1 "30sec" 2 "60sec" 3 "90sec";
VAL_ 162 LDW_Intensity_Req 0 "Low" 1 "Med" 2 "High";
VAL_ 162 LDW_Sensibility_Req 0 "Early" 1 "Med" 2 "Late";
VAL_ 162 PowerLevelReq 0 "Level1" 1 "Level2" 2 "Level3" 3 "Level4" 4 "Level5";
VAL_ 162 RemStNrmlStEnbl_Req 0 "Off" 1 "Remote_Start_Only" 2 "Remote_And_Normal_Start";
VAL_ 162 TSREnableReq 0 "Not_Active" 1 "Active";
VAL_ 162 TyrePressureUnit_Req 0 "kPa" 1 "psi" 2 "bar";
VAL_ 1291 AutoHoldReq 0 "Off" 1 "On";
VAL_ 1291 Drowsy_Driver_Alert_Req 0 "Off" 1 "On";
VAL_ 1291 Speed_Unit_Req 0 "mph" 1 "kph";
VAL_ 163 GreetingLightsLevel_Req 0 "0sec" 1 "30sec" 2 "60sec" 3 "90sec";
VAL_ 163 HUtoIPC_NAV_Sts 0 "Active" 1 "Not_Active" 2 "Map_Not_Available" 3 "Initialization" 4 "AppleCarPlay_projection_Active" 5 "AndroidAuto_projection_Active" 6 "BaiduCarLife_projection_Active" 7 "SNA";
VAL_ 163 New_Spd_Zone_Ind_Req 0 "Off" 1 "Visual" 2 "Chime" 3 "Visual_Chime";
VAL_ 163 SignCaptureModeReq 0 "Confirmation" 1 "Automatic";
VAL_ 163 Traffic_Sign_Warn_Req 0 "Off" 1 "Visual" 2 "Visual_Chime";
VAL_ 1472 AverageFuelConsumptionAPlus 1023 "SNA";
VAL_ 1472 AverageSpeedAPlus 255 "SNA";
VAL_ 1472 PartialOdometerAPlus 1048575 "SNA";
VAL_ 1888 AutonomyDistance 2047 "SNA";
VAL_ 1888 InstantaneousFuelConsumption1 15 "SNA";
VAL_ 1888 InstantaneousFuelConsumption2 15 "SNA";
VAL_ 1888 InstantaneousFuelConsumption3 15 "SNA";
VAL_ 1476 AverageFuelConsumptionBPlus 1023 "SNA";
VAL_ 1476 AverageSpeedBPlus 255 "SNA";
VAL_ 1476 PartialOdometerBPlus 1048575 "SNA";
VAL_ 1444 Electric_Dist_Kilometers 1023 "SNA";
VAL_ 1444 Electric_Dist_Miles 1023 "SNA";
VAL_ 748 UConnReq 0 "NO_BASIC_REQUEST" 1 "LOCK_REQUEST" 2 "RELOCK_REQUEST" 3 "DRIVER_UNLOCK_REQUEST" 4 "ALL_UNLOCK_REQUEST" 5 "TRUNK_PLG_TOGGLE_REQUEST" 6 "LEFT_SLIDER_TOGGLE_REQUEST" 7 "RIGHT_SLIDER_TOGGLE_REQUEST" 8 "FLIPPER_GLASS_REQUEST" 9 "REMOTE_START_ON" 10 "REMOTE_START_OFF" 11 "GLOBAL_WINDOW_DOWN_REQUEST" 12 "OPEN_CONVERTIBLE_TOP" 13 "CLOSE_CONVERTIBLE_TOP" 14 "PANIC_TOGGLE_REQUEST" 15 "DEAD_LOCK_REQUEST" 16 "GLOBAL_WINDOWS_UP_REQUEST" 17 "HEADLIGHTS_OFF_DELAY" 18 "TRUNK_PLG_STOP_REQUEST" 19 "ABORT_CRANKING_ON_REQUEST" 20 "ABORT_CRANKING_OFF_REQUEST" 21 "PRE_COND_ON" 22 "PRE_COND_OFF" 23 "CAR_FINDER_REQUEST" 24 "AUTHENTICATION_REQUEST" 25 "LIGHTS_ON_REQUEST" 26 "LIGHTS_OFF_REQUEST" 27 "LOCK_AND_LIGHTS_OFF_REQUEST" 28 "WARNING_FOB_INSIDE" 29 "WARN_FOB_INSIDE_LIGHTS_OFF_REQ" 31 "SNA";
VAL_ 748 UConnReqFOBNum 0 "FOB_DEFAULT" 1 "FOB_1" 2 "FOB_2" 3 "FOB_3" 4 "FOB_4" 5 "FOB_5" 6 "FOB_6" 7 "FOB_7" 8 "FOB_8" 15 "SNA";
VAL_ 992 VIN_MSG 0 "VIN_LO" 1 "VIN_MID" 2 "VIN_HI" 3 "SNA";
VAL_ 132 FrameNumber 0 "Frame1" 1 "Frame2" 2 "Frame3" 3 "Frame4" 4 "Frame5" 5 "Frame6" 6 "Frame7" 7 "Frame8" 8 "Frame9" 9 "Frame10" 10 "Frame11" 11 "Frame12" 12 "Frame13" 13 "Frame14" 14 "Frame15" 15 "Frame16";
VAL_ 132 TotalFrameNumber 0 "Frame1" 1 "Frame2" 2 "Frame3" 3 "Frame4" 4 "Frame5" 5 "Frame6" 6 "Frame7" 7 "Frame8" 8 "Frame9" 9 "Frame10" 10 "Frame11" 11 "Frame12" 12 "Frame13" 13 "Frame14" 14 "Frame15" 15 "Frame16";
VAL_ 130 FrameNumber 0 "Frame1" 1 "Frame2" 2 "Frame3" 3 "Frame4" 4 "Frame5" 5 "Frame6" 6 "Frame7" 7 "Frame8" 8 "Frame9" 9 "Frame10" 10 "Frame11" 11 "Frame12" 12 "Frame13" 13 "Frame14" 14 "Frame15" 15 "Frame16";
VAL_ 130 TotalFrameNumber 0 "Frame1" 1 "Frame2" 2 "Frame3" 3 "Frame4" 4 "Frame5" 5 "Frame6" 6 "Frame7" 7 "Frame8" 8 "Frame9" 9 "Frame10" 10 "Frame11" 11 "Frame12" 12 "Frame13" 13 "Frame14" 14 "Frame15" 15 "Frame16";
